VERSION ""

NS_ :

BS_:

BU_: ACC GW LAS BDC mADC FC APA HPP

BO_ 381 GW_17D: 64 GW
 SG_ PCU_RollingCounter_17D : 491|4@0+ (1,0) [0|15] ""  ACC,LAS,mADC
 SG_ PCU_CRCCheck_17D : 503|16@0+ (1,0) [0|65535] ""  ACC,LAS,mADC
 SG_ PCU_RollingCounter_1C4 : 435|4@0+ (1,0) [0|15] ""  APA
 SG_ PCU_RearMotSts : 408|1@0+ (1,0) [0|1] "" Vector__XXX
 SG_ PCU_PwrIndcdRealTqRearWhl : 391|15@0+ (1,-5400) [-5400|12000] "Nm"  ACC,LAS,APA,FC,mADC
 SG_ PCU_PwrIndcdDrvrReqTqWhlRear : 392|15@0+ (1,-5400) [-5400|12000] "Nm"  ACC,LAS,FC
 SG_ PCU_ESPTqReqAvlRear : 409|1@0+ (1,0) [0|1] "" Vector__XXX
 SG_ PCU_CRCCheck_1C4 : 447|8@0+ (1,0) [0|255] ""  APA
 SG_ PCU_RollingCounter_1BE : 371|4@0+ (1,0) [0|15] "" Vector__XXX
 SG_ PCU_MbRegenWhlRear : 343|16@0+ (1,-32768) [-32768|32767] "Nm" Vector__XXX
 SG_ PCU_MbRegenMaxWhlTotal : 327|16@0+ (1,-32768) [-32768|32767] "Nm" Vector__XXX
 SG_ PCU_MbRegenMaxRearWhl : 359|16@0+ (1,-32768) [-32768|32767] "Nm" Vector__XXX
 SG_ PCU_CRCCheck_1BE : 383|8@0+ (1,0) [0|255] "" Vector__XXX
 SG_ PCU_PwrTrainSts : 311|2@0+ (1,0) [0|3] ""  ACC,LAS,APA,FC
 SG_ PCU_RollingCounter_1A6 : 307|4@0+ (1,0) [0|15] ""  APA
 SG_ PCU_MbRegenWhlFront : 263|16@0+ (1,-32768) [-32768|32767] "Nm" Vector__XXX
 SG_ PCU_MbRegenMaxWhlQlfr : 293|2@0+ (1,0) [0|2] "" Vector__XXX
 SG_ PCU_MbRegenMaxFrontWhlVld : 294|1@0+ (1,0) [0|1] "" Vector__XXX
 SG_ PCU_MbRegenMaxFrontWhl : 279|16@0+ (1,-32768) [-32768|32767] "Nm" Vector__XXX
 SG_ PCU_CRCCheck_1A6 : 319|8@0+ (1,0) [0|255] ""  APA
 SG_ PCU_APATorqRequestAvailable : 289|1@0+ (1,0) [0|1] ""  APA,mADC
 SG_ PCU_APARequestEnable : 309|2@0+ (1,0) [0|3] ""  APA,mADC
 SG_ PCU_AccPedlVld : 288|1@0+ (1,0) [0|1] ""  ACC,LAS,APA,mADC,FC
 SG_ PCU_AccPedl : 303|8@0+ (0.392,0) [0|99.96] "pct"  ACC,LAS,APA,mADC,FC
 SG_ PCU_StartStopActiveVld : 234|1@0+ (1,0) [0|1] ""  mADC
 SG_ PCU_StartStopActive : 235|1@0+ (1,0) [0|1] ""  mADC
 SG_ PCU_RollingCounter_211 : 243|4@0+ (1,0) [0|15] "" Vector__XXX
 SG_ PCU_RearMotStsVld : 236|1@0+ (1,0) [0|1] "" Vector__XXX
 SG_ PCU_QECACC : 230|2@0+ (1,0) [0|3] ""  ACC,LAS,mADC,FC
 SG_ PCU_PwrIndcdRealTqWhlFailr : 225|1@0+ (1,0) [0|1] ""  ACC,LAS,APA,mADC,FC
 SG_ PCU_PwrIndcdRealTqFrontWhl : 199|15@0+ (1,-5400) [-5400|12000] "Nm"  ACC,LAS,APA,mADC,FC
 SG_ PCU_PwrIndcdDrvrReqTqWhlFront : 200|15@0+ (1,-5400) [-5400|12000] "Nm"  ACC,LAS,APA,mADC,FC
 SG_ PCU_FrontMotStsVld : 239|1@0+ (1,0) [0|1] "" Vector__XXX
 SG_ PCU_FrontMotSts : 217|1@0+ (1,0) [0|1] "" Vector__XXX
 SG_ PCU_ESPTqReqAvlFront : 216|1@0+ (1,0) [0|1] "" Vector__XXX
 SG_ PCU_EngStsVld : 238|1@0+ (1,0) [0|1] ""  mADC
 SG_ PCU_EngSts : 227|1@0+ (1,0) [0|1] ""  mADC
 SG_ PCU_EngClutchStsVld : 237|1@0+ (1,0) [0|1] "" Vector__XXX
 SG_ PCU_EngClutchSts : 226|1@0+ (1,0) [0|1] "" Vector__XXX
 SG_ PCU_ECGPOvrd : 231|1@0+ (1,0) [0|1] ""  ACC,LAS,FC,mADC
 SG_ PCU_CRCCheck_211 : 255|8@0+ (1,0) [0|255] "" Vector__XXX
 SG_ PCU_AccReqPossible : 228|1@0+ (1,0) [0|1] ""  ACC,LAS,FC,mADC
 SG_ RGearbox_ActualDrivingGear : 110|2@0+ (1,0) [0|3] "" Vector__XXX
 SG_ PCU_TrsmTarIdleSpdReq : 108|9@0+ (10,0) [0|5110] "rpm" Vector__XXX
 SG_ PCU_TarGearReqValid : 111|1@0+ (1,0) [0|1] ""  ACC,LAS,FC
 SG_ PCU_TarGearReq : 99|4@0+ (1,0) [0|15] ""  ACC,LAS,FC
 SG_ PCU_SpdCtrlModSelect : 88|2@0+ (1,0) [0|3] "" Vector__XXX
 SG_ PCU_RollingCounter_1C6 : 115|4@0+ (1,0) [0|15] "" Vector__XXX
 SG_ PCU_RealAccPedlVld : 79|1@0+ (1,0) [0|1] ""  ACC,LAS,APA,mADC,FC
 SG_ PCU_RealAccPedl : 71|8@0+ (0.392,0) [0|99.96] "%"  LAS,APA,mADC,FC,ACC
 SG_ PCU_MILReq : 100|1@0+ (1,0) [0|1] "" Vector__XXX
 SG_ PCU_K3CluSts : 78|1@0+ (1,0) [0|1] "" Vector__XXX
 SG_ PCU_FlywhTqTransLoadActInvld : 77|1@0+ (1,0) [0|1] "" Vector__XXX
 SG_ PCU_FlywhTqTransLoadAct : 76|8@0+ (1,0) [0|254] "Nm" Vector__XXX
 SG_ PCU_EngTarIdleSpdReq : 84|9@0+ (10,0) [0|5110] "rpm" Vector__XXX
 SG_ PCU_EngStrtMod : 91|3@0+ (1,0) [0|7] "" Vector__XXX
 SG_ PCU_CRCCheck_1C6 : 127|8@0+ (1,0) [0|255] "" Vector__XXX
 SG_ PCU_ClrDiagcInfo : 102|2@0+ (1,0) [0|3] "" Vector__XXX
 SG_ PCU_StrtTrqCtl : 182|1@0+ (1,0) [0|1] "" Vector__XXX
 SG_ PCU_StrtInhb : 183|1@0+ (1,0) [0|1] "" Vector__XXX
 SG_ PCU_RollingCounter_1E1 : 179|4@0+ (1,0) [0|15] "" Vector__XXX
 SG_ PCU_PtStsChrgCrp : 135|2@0+ (1,0) [0|3] "" Vector__XXX
 SG_ PCU_FuCutOffReq : 153|1@0+ (1,0) [0|1] "" Vector__XXX
 SG_ PCU_EngIgnAgIntvEnbl : 169|1@0+ (1,0) [0|1] "" Vector__XXX
 SG_ PCU_EngTqFlywhSlowReq : 151|13@0+ (0.1,-350) [-350|400] "Nm" Vector__XXX
 SG_ PCU_EngTqFlywhReqVld : 133|1@0+ (1,0) [0|1] "" Vector__XXX
 SG_ PCU_EngTqFlywhFastReq : 132|13@0+ (0.1,-350) [-350|400] "Nm" Vector__XXX
 SG_ PCU_EngTqFlywhAllwdMaxVld : 152|1@0+ (1,0) [0|1] "" Vector__XXX
 SG_ PCU_EngTqFlywhAllwdMax : 167|13@0+ (0.1,-350) [-350|400] "Nm" Vector__XXX
 SG_ PCU_EngStrtOrd : 180|1@0+ (1,0) [0|1] "" Vector__XXX
 SG_ PCU_EngStpOrd : 181|1@0+ (1,0) [0|1] "" Vector__XXX
 SG_ PCU_EMSSurgeDamperEna : 168|1@0+ (1,0) [0|1] "" Vector__XXX
 SG_ PCU_CRCCheck_1E1 : 191|8@0+ (1,0) [0|255] "" Vector__XXX
 SG_ PCU_BrkPedlSts2 : 170|1@0+ (1,0) [0|1] ""  mADC
 SG_ PCU_BrkPedlSts1 : 154|1@0+ (1,0) [0|1] ""  mADC
 SG_ PCU_VehSts : 8|3@0+ (1,0) [0|7] "" Vector__XXX
 SG_ PCU_VehSpdVld : 44|1@0+ (1,0) [0|1] "" Vector__XXX
 SG_ PCU_VehSpd : 43|8@0+ (1,0) [0|254] "km/h" Vector__XXX
 SG_ PCU_SOCDisp : 15|7@0+ (1,0) [0|100] "%" Vector__XXX
 SG_ PCU_CRCID191 : 63|8@0+ (1,0) [0|255] "" Vector__XXX
 SG_ PCU_ChrgUnlckILimReq : 29|1@0+ (1,0) [0|1] "" Vector__XXX
 SG_ PCU_ChrgSuspReq : 47|1@0+ (1,0) [0|1] "" Vector__XXX
 SG_ PCU_ChrgIReqLimFac : 26|2@0+ (1,0) [0|3] "" Vector__XXX
 SG_ PCU_ChrgAllwd : 31|1@0+ (1,0) [0|1] "" Vector__XXX
 SG_ PCU_CHMAsignalSts : 27|1@0+ (1,0) [0|1] "" Vector__XXX
 SG_ PCU_BMSOperModReq : 21|3@0+ (1,0) [0|6] "" Vector__XXX
 SG_ PCU_BattIntrHeatAllwd : 30|1@0+ (1,0) [0|1] "" Vector__XXX
 SG_ PCU_ActHVPwrCnsExt : 7|8@0+ (0.1,0) [0|25.5] "kw" Vector__XXX
 SG_ PCU_191CycCntr : 51|4@0+ (1,0) [0|15] "" Vector__XXX

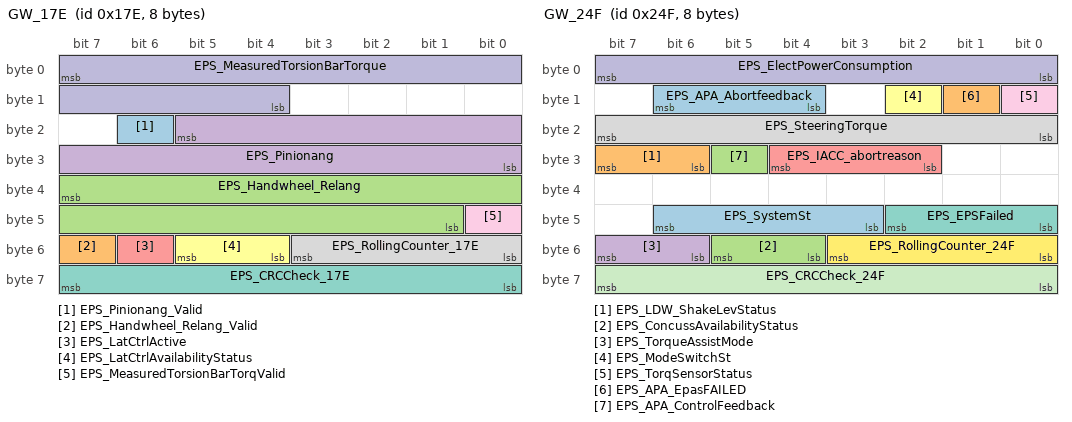
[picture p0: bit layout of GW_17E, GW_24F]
BO_ 382 GW_17E: 8 GW
 SG_ EPS_Pinionang_Valid : 22|1@0+ (1,0) [0|1] ""  mADC,FC
 SG_ EPS_Handwheel_Relang_Valid : 55|1@0+ (1,0) [0|1] ""  LAS,mADC
 SG_ EPS_Handwheel_Relang : 39|15@0+ (0.1,-1080) [-1080|1080] "degree"  LAS,FC,mADC
 SG_ EPS_Pinionang : 21|14@0+ (0.1,-720) [-720|720] "degree"  LAS,FC,mADC
 SG_ EPS_LatCtrlActive : 54|1@0+ (1,0) [0|1] ""  LAS,FC,mADC
 SG_ EPS_LatCtrlAvailabilityStatus : 53|2@0+ (1,0) [0|3] ""  LAS,FC,mADC
 SG_ EPS_CRCCheck_17E : 63|8@0+ (1,0) [0|255] ""  ACC,LAS,FC,mADC
 SG_ EPS_RollingCounter_17E : 51|4@0+ (1,0) [0|15] ""  ACC,LAS,FC,mADC
 SG_ EPS_MeasuredTorsionBarTorqValid : 40|1@0+ (1,0) [0|1] ""  ACC,LAS,FC,mADC
 SG_ EPS_MeasuredTorsionBarTorque : 7|12@0+ (0.01,-20.48) [-20.48|20.46] "Nm"  ACC,LAS,FC,mADC

BO_ 442 ACC_1BA: 32 ACC
 SG_ ACC_CRCCheck_1BA_0 : 63|8@0+ (1,0) [0|255] ""  ACC,LAS,GW,FC,mADC
 SG_ ACC_RollingCounter_1BA_0 : 51|4@0+ (1,0) [0|15] ""  ACC,LAS,GW,FC,mADC
 SG_ ACC_LatAngReqActive : 35|1@0+ (1,0) [0|1] ""  ACC,LAS,GW,FC,mADC
 SG_ ACC_LatAngReq : 17|14@0+ (0.1,-720) [-720|720] "degree"  ACC,LAS,GW,FC,mADC
 SG_ ACC_MotorTorqueMinLimitRequest : 12|11@0+ (0.02,-20.48) [-20.48|20.44] "Nm"  ACC,LAS,GW,FC,mADC
 SG_ ACC_MotorTorqueMaxLimitRequest : 7|11@0+ (0.02,-20.48) [-20.48|20.44] "Nm"  ACC,LAS,GW,FC,mADC

BO_ 523 GW_20B: 64 GW
 SG_ IBCU_BrkPedlStsGbVld : 303|2@0+ (1,0) [0|2] ""  ACC,LAS,APA,FC,mADC
 SG_ IBCU_BrkPedoplStsGb : 295|8@0+ (1,0) [0|255] "%"  ACC,LAS,APA,FC,mADC
 SG_ ESP_Vehicle_Speed_Reference : 103|13@0+ (0.05625,0) [0|360] "km/h"  ACC,LAS,FC,APA
 SG_ IBCU_precheckStatus : 309|2@0+ (1,0) [0|3] ""  ACC,LAS,APA
 SG_ ESP_PrefillforAPA_Available : 280|1@0+ (1,0) [0|1] ""  ACC,LAS,APA,mADC
 SG_ ESP_PrefillforAPA_active : 281|1@0+ (1,0) [0|1] ""  ACC,LAS,APA,mADC
 SG_ IBCU_BrakeDiscHighTempWarning : 283|2@0+ (1,0) [0|3] ""  ACC,LAS,FC,APA
 SG_ ESP_RollingCounter_20B : 491|4@0+ (1,0) [0|15] ""  ACC,LAS,FC,HPP,mADC
 SG_ ESP_CRCCheck_20B : 503|16@0+ (1,0) [0|65535] ""  ACC,LAS,FC,HPP,mADC
 SG_ Wheel_Speed_RR_Valid_Data : 71|1@0+ (1,0) [0|1] ""  APA,ACC,LAS,FC,HPP,mADC
 SG_ Wheel_Speed_RR_Pulse : 231|8@0+ (1,0) [0|254] ""  APA,ACC,LAS,FC,HPP,mADC
 SG_ Wheel_Speed_RR_Direction : 70|2@0+ (1,0) [0|3] ""  APA,ACC,LAS,FC,HPP,mADC
 SG_ Wheel_Speed_RR_Data : 68|13@0+ (0.05625,0) [0|360] "km/h"  APA,ACC,LAS,FC,HPP,mADC
 SG_ Wheel_Speed_RL_Valid_Data : 87|1@0+ (1,0) [0|1] ""  APA,ACC,LAS,FC,HPP,mADC
 SG_ Wheel_Speed_RL_Pulse : 239|8@0+ (1,0) [0|254] ""  APA,ACC,LAS,FC,HPP,mADC
 SG_ Wheel_Speed_RL_Direction : 86|2@0+ (1,0) [0|3] ""  APA,ACC,LAS,FC,HPP,mADC
 SG_ Wheel_Speed_RL_Data : 84|13@0+ (0.05625,0) [0|360] "km/h"  APA,ACC,LAS,FC,HPP,mADC
 SG_ Wheel_Speed_FR_Valid_Data : 7|1@0+ (1,0) [0|1] ""  APA,ACC,LAS,FC,HPP,mADC
 SG_ Wheel_Speed_FR_Pulse : 223|8@0+ (1,0) [0|254] ""  APA,ACC,LAS,FC,HPP,mADC
 SG_ Wheel_Speed_FR_Direction : 6|2@0+ (1,0) [0|3] ""  APA,ACC,LAS,FC,HPP,mADC
 SG_ Wheel_Speed_FR_Data : 4|13@0+ (0.05625,0) [0|360] "km/h"  APA,ACC,LAS,FC,HPP,mADC
 SG_ Wheel_Speed_FL_Valid_Data : 23|1@0+ (1,0) [0|1] ""  APA,ACC,LAS,FC,HPP,mADC
 SG_ Wheel_Speed_FL_Pulse : 215|8@0+ (1,0) [0|254] ""  APA,ACC,LAS,FC,HPP,mADC
 SG_ Wheel_Speed_FL_Direction : 22|2@0+ (1,0) [0|3] ""  APA,ACC,LAS,FC,HPP,mADC
 SG_ Wheel_Speed_FL_Data : 20|13@0+ (0.05625,0) [0|360] "km/h"  APA,ACC,LAS,FC,HPP,mADC
 SG_ ESP_VehicleStandstill : 267|1@0+ (1,0) [0|1] ""  APA,ACC,LAS,FC,mADC
 SG_ ESP_VDCActive : 266|1@0+ (1,0) [0|1] ""  ACC,LAS,FC,mADC
 SG_ ESP_UrgencyBrakeAlarm : 118|1@0+ (1,0) [0|1] "" Vector__XXX
 SG_ ESP_TODTorqueMaxLimit : 47|12@0+ (1,0) [0|4094] "NM" Vector__XXX
 SG_ ESP_TCSActive : 265|1@0+ (1,0) [0|1] ""  ACC,LAS,FC,mADC
 SG_ ESP_RollingCounter_277 : 307|4@0+ (1,0) [0|15] ""  APA,ACC,LAS,FC
 SG_ ESP_RollingCounter_258 : 243|4@0+ (1,0) [0|15] ""  APA,ACC,LAS,FC,HPP
 SG_ ESP_RollingCounter_208 : 115|4@0+ (1,0) [0|15] ""  APA,ACC,LAS,FC,HPP
 SG_ ESP_RollingCounter_206 : 51|4@0+ (1,0) [0|15] ""  APA,ACC,LAS,FC,HPP
 SG_ ESP_QDCACC : 279|2@0+ (1,0) [0|3] ""  ACC,LAS,FC,mADC
 SG_ ESP_PrefillAvailable : 259|1@0+ (1,0) [0|1] ""  ACC,LAS,FC,APA,mADC,HPP
 SG_ ESP_PrefillActive : 260|1@0+ (1,0) [0|1] ""  ACC,LAS,FC,APA,mADC,HPP
 SG_ ESP_OnlyABSActive : 264|1@0+ (1,0) [0|1] ""  ACC,LAS,FC,mADC
 SG_ ESP_MasCylBrakePressureValid : 199|1@0+ (1,0) [0|1] ""  APA,ACC,LAS,FC,mADC
 SG_ ESP_MasCylBrakePressure : 195|12@0+ (0.1,0) [0|250] "Bar"  APA,ACC,LAS,FC,mADC
 SG_ ESP_IncreasePressureReqOK : 275|1@0+ (1,0) [0|1] "NA"  APA,mADC
 SG_ ESP_HHC_Available : 245|1@0+ (1,0) [0|1] ""  mADC
 SG_ ESP_HHC_Active : 244|1@0+ (1,0) [0|1] ""  mADC
 SG_ ESP_HDC_STATUS : 274|2@0+ (1,0) [0|3] ""  ACC,LAS,mADC
 SG_ ESP_HBBActiveStatus : 272|1@0+ (1,0) [0|1] ""  mADC
 SG_ ESP_ECDAvailable : 116|1@0+ (1,0) [0|1] "" Vector__XXX
 SG_ ESP_ECDActive : 117|1@0+ (1,0) [0|1] "" Vector__XXX
 SG_ ESP_CRCCheck_277 : 319|8@0+ (1,0) [0|255] ""  APA,ACC,LAS,FC
 SG_ ESP_CRCCheck_258 : 255|8@0+ (1,0) [0|255] ""  ACC,LAS,FC,APA,HPP
 SG_ ESP_CRCCheck_208 : 127|8@0+ (1,0) [0|255] ""  APA,ACC,LAS,FC,HPP
 SG_ ESP_CRCCheck_206 : 63|8@0+ (1,0) [0|255] ""  APA,ACC,LAS,FC,HPP
 SG_ ESP_CDP_ParkingAvailForACC : 284|1@0+ (1,0) [0|1] "" Vector__XXX
 SG_ ESP_CDP_ParkingActiveForACC : 285|1@0+ (1,0) [0|1] "" Vector__XXX
 SG_ ESP_CDD_Available_APA : 276|1@0+ (1,0) [0|1] "NA"  APA,mADC
 SG_ ESP_CDD_Available : 268|1@0+ (1,0) [0|1] ""  ACC,LAS,FC,mADC
 SG_ ESP_CDD_Active_APA : 277|1@0+ (1,0) [0|1] "NA"  APA,mADC
 SG_ ESP_CDD_Active : 269|1@0+ (1,0) [0|1] ""  ACC,LAS,FC,mADC
 SG_ ESP_BrakeOverHeatBrakeDiscTemp : 270|1@0+ (1,0) [0|1] ""  ACC,LAS,FC,mADC
 SG_ ESP_BrakeLightOnRequest : 197|2@0+ (1,0) [0|3] "" Vector__XXX
 SG_ ESP_BrakeForce : 263|1@0+ (1,0) [0|1] ""  ACC,LAS,FC,APA,mADC
 SG_ ESP_AWBavailable : 271|1@0+ (1,0) [0|1] ""  ACC,LAS,FC,mADC
 SG_ ESP_AWBactive : 256|1@0+ (1,0) [0|1] ""  ACC,LAS,FC,mADC
 SG_ ESP_AutoHoldStandby : 198|1@0+ (1,0) [0|1] "" Vector__XXX
 SG_ ESP_AutoHoldAvailable : 246|1@0+ (1,0) [0|1] ""  LAS,ACC
 SG_ ESP_AutoHoldActive : 247|1@0+ (1,0) [0|1] ""  LAS,ACC,mADC
 SG_ ESP_AEBdecActive : 257|1@0+ (1,0) [0|1] ""  ACC,LAS,FC,mADC
 SG_ ESP_AEBAvailable : 258|1@0+ (1,0) [0|1] ""  ACC,LAS,FC,mADC
 SG_ ESP_ABAavailable : 261|1@0+ (1,0) [0|1] ""  ACC,LAS,FC,mADC
 SG_ ESP_ABAactive : 262|1@0+ (1,0) [0|1] ""  ACC,LAS,FC,mADC
 SG_ ABS_TODFastOpenRequest : 33|2@0+ (1,0) [0|3] "" Vector__XXX

BO_ 591 GW_24F: 8 GW
 SG_ EPS_SystemSt : 46|4@0+ (1,0) [0|15] ""  mADC
 SG_ EPS_LDW_ShakeLevStatus : 31|2@0+ (1,0) [0|3] ""  LAS,FC,mADC
 SG_ EPS_ConcussAvailabilityStatus : 53|2@0+ (1,0) [0|3] ""  ACC,LAS,FC,APA,mADC,HPP
 SG_ EPS_TorqueAssistMode : 55|2@0+ (1,0) [0|3] ""  ACC,LAS,FC,APA,mADC
 SG_ EPS_IACC_abortreason : 28|3@0+ (1,0) [0|7] ""  LAS,FC,APA,mADC,HPP
 SG_ EPS_ModeSwitchSt : 10|1@0+ (1,0) [0|1] ""  mADC
 SG_ EPS_EPSFailed : 42|3@0+ (1,0) [0|7] ""  mADC
 SG_ EPS_SteeringTorque : 23|8@0+ (0.1794,-22.78) [-22.78|22.78] "Nm"  APA,mADC
 SG_ EPS_TorqSensorStatus : 8|1@0+ (1,0) [0|1] ""  APA,mADC
 SG_ EPS_ElectPowerConsumption : 7|8@0+ (0.5,0) [0|127] "A"  APA,mADC
 SG_ EPS_CRCCheck_24F : 63|8@0+ (1,0) [0|255] ""  ACC,LAS,FC,APA,mADC,HPP
 SG_ EPS_RollingCounter_24F : 51|4@0+ (1,0) [0|15] ""  ACC,LAS,FC,APA,mADC
 SG_ EPS_APA_Abortfeedback : 14|3@0+ (1,0) [0|7] ""  APA,mADC
 SG_ EPS_APA_EpasFAILED : 9|1@0+ (1,0) [0|1] ""  APA,mADC
 SG_ EPS_APA_ControlFeedback : 29|1@0+ (1,0) [0|1] ""  APA,mADC

BO_ 651 GW_28B: 8 GW
 SG_ BCM_RefuelReq : 55|1@0+ (1,0) [0|1] "" Vector__XXX
 SG_ BCM_TrunkReleaseTrigger : 31|4@0+ (1,0) [0|15] "" Vector__XXX
 SG_ BCM_LockTrigger : 12|5@0+ (1,0) [0|31] ""  mADC
 SG_ BCM_UnlockTrigger : 44|5@0+ (1,0) [0|31] ""  mADC
 SG_ BCM_CRCCheck_28B : 63|8@0+ (1,0) [0|255] ""  FC,LAS,ACC,mADC
 SG_ BCM_RollingCounter_28B : 51|4@0+ (1,0) [0|15] ""  FC,LAS,ACC,mADC
 SG_ BCM_TurnIndicatorLeft : 22|2@0+ (1,0) [0|3] ""  ACC,LAS,FC,APA,mADC,HPP
 SG_ BCM_TurnIndicatorRight : 20|2@0+ (1,0) [0|3] ""  ACC,LAS,FC,APA,mADC,HPP
 SG_ PEPS_ShiftForbidRq : 54|1@0+ (1,0) [0|1] "" Vector__XXX
 SG_ BCM_KeyAlarmStatus : 53|2@0+ (1,0) [0|3] ""  APA,mADC
 SG_ PEPS_RemoteStartReq : 39|2@0+ (1,0) [0|3] ""  APA
 SG_ BCM_emergencylightstatus : 37|2@0+ (1,0) [0|3] ""  LAS,FC,APA,mADC,ACC
 SG_ BCM_PowerStatusFeedback : 35|2@0+ (1,0) [0|3] ""  APA,ACC,LAS,FC,mADC
 SG_ BCM_RearDefrosterstatus : 33|2@0+ (1,0) [0|3] ""  mADC
 SG_ BCM_DriverDoorStatus : 23|1@0+ (1,0) [0|1] ""  APA,ACC,FC,LAS,mADC
 SG_ BCM_HoodStatus : 18|1@0+ (1,0) [0|1] ""  ACC,mADC
 SG_ PEPS_StartControlsignal : 17|2@0+ (1,0) [0|3] "" Vector__XXX
 SG_ BCM_LowBeamStatus : 7|2@0+ (1,0) [0|3] ""  LAS,FC,APA,mADC
 SG_ BCM_HighBeamStatus : 5|2@0+ (1,0) [0|3] ""  LAS,FC,APA,mADC
 SG_ BCM_TurnLightSwitchSts : 3|2@0+ (1,0) [0|3] ""  APA,LAS,FC,ACC,mADC
 SG_ BCM_MirrorAdjustSts : 14|2@0+ (1,0) [0|3] ""  LAS,ACC,mADC

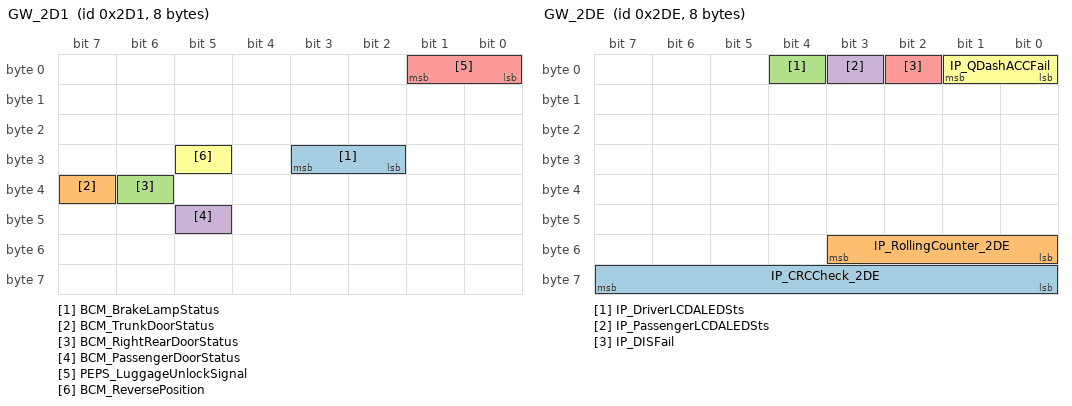
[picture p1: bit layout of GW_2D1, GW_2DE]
BO_ 721 GW_2D1: 8 GW
 SG_ BCM_BrakeLampStatus : 27|2@0+ (1,0) [0|3] ""  mADC
 SG_ BCM_TrunkDoorStatus : 39|1@0+ (1,0) [0|1] ""  ACC,LAS,FC,APA,mADC
 SG_ BCM_RightRearDoorStatus : 38|1@0+ (1,0) [0|1] ""  ACC,LAS,FC,APA,mADC
 SG_ BCM_PassengerDoorStatus : 45|1@0+ (1,0) [0|1] ""  ACC,LAS,FC,APA,mADC
 SG_ PEPS_LuggageUnlockSignal : 1|2@0+ (1,0) [0|3] "" Vector__XXX
 SG_ BCM_ReversePosition : 29|1@0+ (1,0) [0|1] ""  mADC

BO_ 734 GW_2DE: 8 GW
 SG_ IP_CRCCheck_2DE : 63|8@0+ (1,0) [0|255] ""  ACC,APA,FC,LAS,mADC
 SG_ IP_RollingCounter_2DE : 51|4@0+ (1,0) [0|15] ""  ACC,APA,FC,LAS,mADC
 SG_ IP_DriverLCDALEDSts : 4|1@0+ (1,0) [0|1] ""  APA,mADC
 SG_ IP_PassengerLCDALEDSts : 3|1@0+ (1,0) [0|1] ""  APA,mADC
 SG_ IP_DISFail : 2|1@0+ (1,0) [0|1] ""  ACC,LAS,FC,mADC
 SG_ IP_QDashACCFail : 1|2@0+ (1,0) [0|3] ""  ACC,LAS,FC,mADC

BO_ 742 GW_2E6: 8 GW
 SG_ EMS_WarmUpCycle : 9|1@0+ (1,0) [0|1] "" Vector__XXX
 SG_ EMS_SecIgnitionCyclesCounter : 53|1@0+ (1,0) [0|1] "" Vector__XXX
 SG_ EMS_RollingCounter_2E6 : 51|4@0+ (1,0) [0|15] "" Vector__XXX
 SG_ EMS_LoBattU : 31|8@0+ (0.1,0) [0|25.4] "V" Vector__XXX
 SG_ EMS_LoBattErr : 14|1@0+ (1,0) [0|1] "" Vector__XXX
 SG_ EMS_IgnitionCyclesCounterValid : 52|1@0+ (1,0) [0|1] "" Vector__XXX
 SG_ EMS_GeneralDenoStatusValid : 11|1@0+ (1,0) [0|1] "" Vector__XXX
 SG_ EMS_GeneralDenominatorStatus : 12|1@0+ (1,0) [0|1] "" Vector__XXX
 SG_ EMS_FirstIgnitionCycleCounter : 10|1@0+ (1,0) [0|1] "" Vector__XXX
 SG_ EMS_EngTCoolt : 23|8@0+ (0.75,-48) [-48|142.5] "°C" Vector__XXX
 SG_ EMS_EngineIntakeAirTemp : 7|8@0+ (0.75,-40) [-40|150.5] "degreeC" Vector__XXX
 SG_ EMS_DrivingCycle : 8|1@0+ (1,0) [0|1] "" Vector__XXX
 SG_ EMS_CRCCheck_2E6 : 63|8@0+ (1,0) [0|255] "" Vector__XXX
 SG_ EMS_CooltTErr : 15|1@0+ (1,0) [0|1] "" Vector__XXX
 SG_ EMS_Coolreq : 39|7@0+ (1,0) [0|100] "%" Vector__XXX
 SG_ EMS_CatalystWarmUp : 13|1@0+ (1,0) [0|1] "" Vector__XXX
 SG_ EMS_AltitudeFactorValid : 32|1@0+ (1,0) [0|1] "" Vector__XXX
 SG_ EMS_AltitudeFactor : 47|8@0+ (0.01575,0) [0|4] ""  ACC,FC

BO_ 794 ACC_31A: 64 ACC
 SG_ ADC_EcasModeReq : 165|3@0+ (1,0) [0|7] ""  ACC,LAS,mADC,GW
 SG_ ACC_AEBTargetLatRelSpeed : 293|10@0+ (0.125,-64) [-64|63.875] "m/s"  ACC,LAS,GW,mADC
 SG_ ACC_LngTakeOverReqReason : 232|5@0+ (1,0) [0|31] ""  ACC,LAS,FC,GW,mADC
 SG_ ACC_ELKAlert : 25|2@0+ (1,0) [0|3] ""  ACC,LAS,GW,mADC
 SG_ ACC_CRCCheck_367 : 255|8@0+ (1,0) [0|255] ""  ACC,LAS,FC,GW
 SG_ ACC_RollingCounter_367 : 243|4@0+ (1,0) [0|15] ""  ACC,LAS,FC,GW
 SG_ ACC_LatPathHeadingAngle : 227|11@0- (0.1,0) [-90|90] "degree"  ACC,LAS,GW,mADC
 SG_ ACC_ELKEnableStatus : 222|1@0+ (1,0) [0|1] ""  ACC,LAS,GW,mADC
 SG_ ACC_ELKInterventionMode : 210|2@0+ (1,0) [0|3] ""  ACC,LAS,GW,mADC
 SG_ ACC_ELKMode : 213|3@0+ (1,0) [0|7] ""  ACC,LAS,GW,mADC
 SG_ ACC_CRCCheck_30D : 191|8@0+ (1,0) [0|255] ""  ACC,LAS,FC,GW
 SG_ ACC_RollingCounter_30D : 179|4@0+ (1,0) [0|15] ""  ACC,LAS,FC,GW
 SG_ ACC_RRLaneDetection : 174|2@0+ (1,0) [0|3] ""  ACC,LAS,GW,mADC
 SG_ ACC_LLLaneDetection : 167|2@0+ (1,0) [0|3] ""  ACC,LAS,GW,mADC
 SG_ ACC_HighBeamControl : 182|2@0+ (1,0) [0|3] ""  ACC,LAS,GW
 SG_ ACC_TargetBasedLateralControl : 150|2@0+ (1,0) [0|3] ""  ACC,LAS,FC,GW,mADC
 SG_ ACC_IACCHWATextInfoForDriver : 128|6@0+ (1,0) [0|63] ""  ACC,LAS,FC,GW,mADC
 SG_ ACC_EmergencyLightingRequest : 148|2@0+ (1,0) [0|3] ""  ACC,LAS,FC,GW,mADC
 SG_ ACC_DriverHandsOffStatus : 137|2@0+ (1,0) [0|3] ""  ACC,LAS,FC,GW,mADC
 SG_ ACC_IACCHWAMode : 135|3@0+ (1,0) [0|7] ""  ACC,LAS,FC,GW,APA,mADC
 SG_ ACC_CRCCheck_30A : 127|8@0+ (1,0) [0|255] ""  ACC,LAS,FC,GW
 SG_ ACC_RollingCounter_30A : 115|4@0+ (1,0) [0|15] ""  ACC,LAS,FC,GW
 SG_ ACC_LaneChangeStatus : 117|2@0+ (1,0) [0|3] ""  ACC,LAS,GW,mADC
 SG_ ACC_RoadCurvatureFar : 109|7@0+ (0.0005,-0.03) [-0.03|0.03] "1/m"  ACC,LAS,GW
 SG_ ACC_RoadCurvatureNear : 100|7@0+ (0.0005,-0.03) [-0.03|0.03] "1/m"  ACC,LAS,GW
 SG_ ACC_RoadCurvature : 91|7@0+ (0.0005,-0.03) [-0.03|0.03] "1/m"  ACC,LAS,GW
 SG_ ACC_IACCHWAEnable : 78|1@0+ (1,0) [0|1] ""  ACC,LAS,GW,mADC
 SG_ ACC_RLaneMarkerType : 71|4@0+ (1,0) [0|15] ""  ACC,LAS,FC,GW,mADC
 SG_ ACC_LLaneMarkerType : 95|4@0+ (1,0) [0|15] ""  ACC,LAS,FC,GW,mADC
 SG_ ACC_HostLaneRightStatus : 87|4@0+ (1,0) [0|15] ""  ACC,LAS,FC,GW,mADC
 SG_ ACC_HostLaneLeftStatus : 83|4@0+ (1,0) [0|15] ""  ACC,LAS,FC,GW,mADC
 SG_ ACC_LASWarningModeSelectionSts : 74|3@0+ (1,0) [0|7] ""  ACC,GW,LAS,mADC
 SG_ ACC_LASModeSelectionStatus : 66|3@0+ (1,0) [0|7] ""  ACC,LAS,GW,mADC
 SG_ ACC_CRCCheck_36D : 63|8@0+ (1,0) [0|255] ""  ACC,LAS,FC,GW
 SG_ ACC_RollingCounter_36D : 51|4@0+ (1,0) [0|15] ""  ACC,LAS,FC,GW
 SG_ ACC_FRadarFailureStatus : 53|2@0+ (1,0) [0|3] ""  LAS,ACC,GW,mADC
 SG_ ACC_AEBTargetLatRange : 21|10@0+ (0.1,-50) [-50|50] "m"  ACC,LAS,GW,mADC
 SG_ ACC_AEBTargetRelSpeed : 14|9@0+ (1,-250) [-250|250] "km/h"  ACC,LAS,GW,mADC
 SG_ ACC_AEBTargetLngRange : 7|9@0+ (0.5,-70) [-70|180] "m"  ACC,LAS,GW,mADC
 SG_ ACC_Voiceinfo : 47|5@0+ (1,0) [0|31] ""  ACC,LAS,FC,GW,mADC
 SG_ ACC_AEBTargetmode : 33|2@0+ (1,0) [0|3] ""  ACC,LAS,GW,mADC
 SG_ ACC_AEBTextInfo : 37|4@0+ (1,0) [0|15] ""  ACC,LAS,GW,mADC
 SG_ ACC_AEBStatus : 39|2@0+ (1,0) [0|3] ""  ACC,LAS,GW,mADC

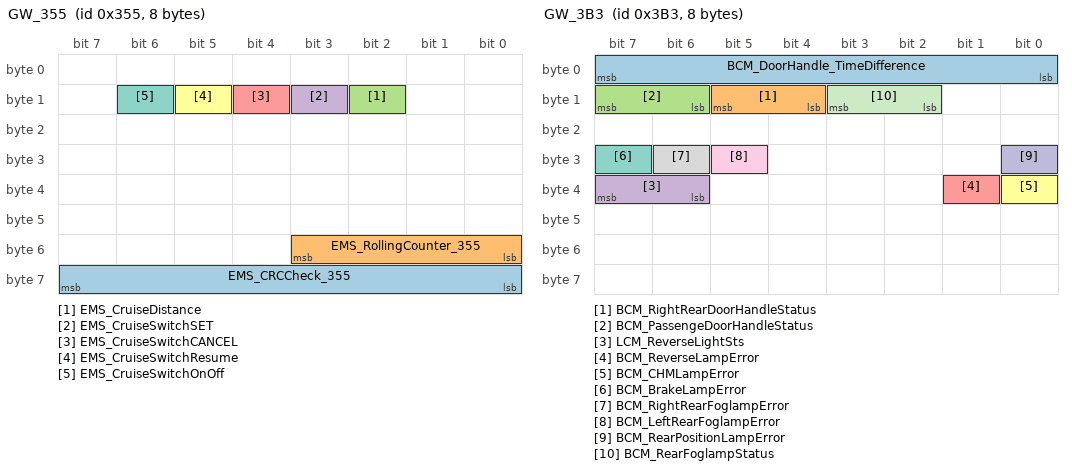
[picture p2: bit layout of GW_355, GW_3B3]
BO_ 853 GW_355: 8 GW
 SG_ EMS_CRCCheck_355 : 63|8@0+ (1,0) [0|255] ""  ACC,FC,LAS
 SG_ EMS_RollingCounter_355 : 51|4@0+ (1,0) [0|15] ""  ACC,FC,LAS
 SG_ EMS_CruiseDistance : 10|1@0+ (1,0) [0|1] ""  ACC,LAS,FC
 SG_ EMS_CruiseSwitchSET : 11|1@0+ (1,0) [0|1] ""  ACC,LAS,FC
 SG_ EMS_CruiseSwitchCANCEL : 12|1@0+ (1,0) [0|1] ""  ACC,LAS,FC
 SG_ EMS_CruiseSwitchResume : 13|1@0+ (1,0) [0|1] ""  ACC,LAS,FC
 SG_ EMS_CruiseSwitchOnOff : 14|1@0+ (1,0) [0|1] ""  ACC,LAS,FC

BO_ 943 GW_3AF: 64 GW
 SG_ HU_CRCCheck_3AF : 503|16@0+ (1,0) [0|65535] ""  ACC,LAS
 SG_ HU_RollingCounter_3AF : 491|4@0+ (1,0) [0|15] ""  ACC,LAS
 SG_ HU_Novice_Enable : 245|2@0+ (1,0) [0|3] ""  APA
 SG_ HU_ADAS_Posn_Offset : 353|13@0+ (1,0) [0|8191] "m"  ACC,LAS,mADC
 SG_ HU_ADAS_Posn_Pathldx : 359|6@0+ (1,0) [0|63] ""  ACC,LAS,mADC
 SG_ HU_EHPHeartFlag : 345|1@0+ (1,0) [0|1] ""  ACC,LAS
 SG_ HU_EHRHeartFlag : 344|1@0+ (1,0) [0|1] ""  ACC,LAS
 SG_ HU_LaneType_ID6 : 349|4@0+ (1,0) [0|15] ""  ACC,LAS,mADC
 SG_ HU_LaneType_ID5 : 337|4@0+ (1,0) [0|15] ""  ACC,LAS,mADC
 SG_ HU_LaneType_ID4 : 341|4@0+ (1,0) [0|15] ""  ACC,LAS,mADC
 SG_ HU_LaneType_ID3 : 329|4@0+ (1,0) [0|15] ""  ACC,LAS,mADC
 SG_ HU_LaneType_ID2 : 333|4@0+ (1,0) [0|15] ""  ACC,LAS,mADC
 SG_ HU_LaneType_ID1 : 321|4@0+ (1,0) [0|15] ""  ACC,LAS,mADC
 SG_ HU_ServiceRoadDis : 327|6@0+ (10,0) [0|600] "m"  ACC,LAS,mADC
 SG_ HU_ServiceRoad : 183|2@0+ (1,0) [0|3] "m"  ACC,LAS,mADC
 SG_ HU_WeatherType : 181|7@0+ (1,0) [0|127] ""  ACC,LAS,mADC
 SG_ HU_BridgeDis : 163|6@0+ (10,0) [0|600] "m"  ACC,LAS,mADC
 SG_ HU_BridgeInfo : 165|2@0+ (1,0) [0|3] ""  ACC,LAS,mADC
 SG_ HU_AccidentProneDistance : 147|6@0+ (10,0) [0|600] "m"  ACC,LAS,mADC
 SG_ HU_AccidentProne : 149|2@0+ (1,0) [0|3] ""  ACC,LAS,mADC
 SG_ HU_IntervalVelocityDis : 139|6@0+ (10,0) [0|600] "m"  ACC,LAS,mADC
 SG_ HU_IntervalVelocityInfo : 141|2@0+ (1,0) [0|3] ""  ACC,LAS,mADC
 SG_ HU_SlopeGradient_100m : 135|10@0+ (0.1,-51.1) [-51.1|51.1] "m"  ACC,LAS,mADC
 SG_ HU_SlopeGradient_50m : 111|10@0+ (0.1,-51.1) [-51.1|51.1] ""  ACC,LAS,mADC
 SG_ HU_SlopeGradient_40m : 89|10@0+ (0.1,-51.1) [-51.1|51.1] "m"  ACC,LAS,mADC
 SG_ HU_SlopeGradient_30m : 83|10@0+ (0.1,-51.1) [-51.1|51.1] ""  ACC,LAS,mADC
 SG_ HU_SlopeGradient_20m : 77|10@0+ (0.1,-51.1) [-51.1|51.1] ""  ACC,LAS,mADC
 SG_ HU_SlopeGradient_10m : 71|10@0+ (0.1,-51.1) [-51.1|51.1] ""  ACC,LAS,mADC
 SG_ HU_CRCCheck_3AF_3 : 255|8@0+ (1,0) [0|255] ""  LAS,ACC,mADC
 SG_ HU_RollingCounter_3AF_3 : 243|4@0+ (1,0) [0|15] ""  LAS,ACC,mADC
 SG_ HU_RampDistance : 239|10@0+ (10,0) [0|3000] "m"  LAS,ACC,mADC
 SG_ HU_NavSpeedLimitType : 231|2@0+ (1,0) [0|3] ""  LAS,ACC,mADC
 SG_ HU_CurveDistance : 229|6@0+ (10,0) [0|600] "m"  LAS,ACC,mADC
 SG_ HU_EnterCurveInfo : 220|2@0+ (1,0) [0|3] ""  LAS,ACC,mADC
 SG_ HU_NavCurrentRoadType : 218|3@0+ (1,0) [0|7] ""  LAS,ACC,FC,mADC
 SG_ HU_EnterRampInfo : 215|2@0+ (1,0) [0|3] ""  LAS,ACC,mADC
 SG_ HU_RampInfo : 209|2@0+ (1,0) [0|3] ""  LAS,ACC,mADC
 SG_ HU_NavCountryCode : 199|8@0+ (1,0) [0|255] ""  ACC,LAS,mADC
 SG_ HU_NavStatus : 223|1@0+ (1,0) [0|1] ""  LAS,ACC,mADC
 SG_ HU_NavSpeedLimitUnits : 213|2@0+ (1,0) [0|3] ""  ACC,LAS,mADC
 SG_ HU_NavSpeedLimitStatus : 211|2@0+ (1,0) [0|3] ""  ACC,LAS,mADC
 SG_ HU_NavSpeedLimit : 207|8@0+ (1,0) [0|255] ""  LAS,ACC,mADC
 SG_ HU_CRCCheck_3BB : 319|8@0+ (1,0) [0|255] ""  ACC,FC,LAS
 SG_ HU_RollingCounter_3BB : 307|4@0+ (1,0) [0|15] ""  ACC,FC,LAS
 SG_ HU_SpeedLimitDistance : 261|6@0+ (10,0) [0|600] "m"  ACC,LAS,mADC

BO_ 947 GW_3B3: 8 GW
 SG_ BCM_DoorHandle_TimeDifference : 7|8@0+ (5,0) [0|1275] "ms" Vector__XXX
 SG_ BCM_RightRearDoorHandleStatus : 13|2@0+ (1,0) [0|3] ""  mADC
 SG_ BCM_PassengeDoorHandleStatus : 15|2@0+ (1,0) [0|3] ""  mADC
 SG_ LCM_ReverseLightSts : 39|2@0+ (1,0) [0|3] ""  mADC
 SG_ BCM_ReverseLampError : 33|1@0+ (1,0) [0|1] ""  mADC
 SG_ BCM_CHMLampError : 32|1@0+ (1,0) [0|1] ""  mADC
 SG_ BCM_BrakeLampError : 31|1@0+ (1,0) [0|1] ""  ACC,LAS,mADC
 SG_ BCM_RightRearFoglampError : 30|1@0+ (1,0) [0|1] ""  mADC
 SG_ BCM_LeftRearFoglampError : 29|1@0+ (1,0) [0|1] ""  mADC
 SG_ BCM_RearPositionLampError : 24|1@0+ (1,0) [0|1] ""  mADC
 SG_ BCM_RearFoglampStatus : 11|2@0+ (1,0) [0|3] ""  ACC,LAS,mADC

BO_ 957 GW_3BD: 64 GW
 SG_ HU_ADSRoadVoiceEnable : 23|2@0+ (1,0) [0|3] "" Vector__XXX
 SG_ HU_ADSLaneChangeVoiceEnable : 55|2@0+ (1,0) [0|3] "" Vector__XXX
 SG_ HU_ADSSafeVoiceEnable : 53|2@0+ (1,0) [0|3] "" Vector__XXX
 SG_ HU_AVMMapDisplayFeedback : 101|2@0+ (1,0) [0|3] ""  APA
 SG_ HU_APAThemeChange : 292|3@0+ (1,0) [0|7] ""  APA
 SG_ HU_RearFoglampSet : 244|2@0+ (1,0) [0|3] "" Vector__XXX
 SG_ HU_AutoHeadLiSet : 242|3@0+ (1,0) [0|7] ""  mADC
 SG_ HU_TransparentValueCarRequest : 31|7@0+ (1,0) [0|100] ""  APA
 SG_ HU_RADSSwitch : 220|2@0+ (1,0) [0|3] ""  mADC
 SG_ HU_CRCCheck_394 : 63|8@0+ (1,0) [0|255] ""  mADC
 SG_ HU_RollingCounter_394 : 51|4@0+ (1,0) [0|15] ""  mADC
 SG_ HU_CurrentMedia_Info : 207|8@0+ (1,0) [0|255] "" Vector__XXX
 SG_ HU_LaneChangeReq : 13|2@0+ (1,0) [0|3] ""  mADC
 SG_ HU_HWAEnable : 5|2@0+ (1,0) [0|3] "" Vector__XXX
 SG_ HU_Compass : 179|9@0+ (1,0) [0|360] "Degree" Vector__XXX
 SG_ HU_APARemoteDispSts : 208|1@0+ (1,0) [0|1] "" Vector__XXX
 SG_ HU_RemoteDispSts : 195|1@0+ (1,0) [0|1] "" Vector__XXX
 SG_ HU_IRLCEnable : 3|2@0+ (1,0) [0|3] "" Vector__XXX
 SG_ HU_ADSRescueConfirm : 19|2@0+ (1,0) [0|3] "" Vector__XXX
 SG_ HU_CSLAEnable : 7|2@0+ (1,0) [0|3] ""  ACC,LAS
 SG_ HU_UDLCEnable : 17|2@0+ (1,0) [0|3] ""  mADC
 SG_ HU_ESSEnable : 11|2@0+ (1,0) [0|3] ""  mADC
 SG_ HU_ELKEnable : 1|2@0+ (1,0) [0|3] ""  LAS,FC,mADC
 SG_ HU_TLAEnable : 9|2@0+ (1,0) [0|3] ""  LAS,mADC
 SG_ HU_EXT_RemoteDetectUploadStatus : 227|2@0+ (1,0) [0|3] "" Vector__XXX
 SG_ HU_PACModeSelect : 229|2@0+ (1,0) [0|3] "" Vector__XXX
 SG_ HU_APAActive : 196|1@0+ (1,0) [0|1] "" Vector__XXX
 SG_ HU_CrossParkingModeSet : 235|2@0+ (1,0) [0|3] "" Vector__XXX
 SG_ HU_ASPSwitch : 233|2@0+ (1,0) [0|3] "" Vector__XXX
 SG_ HU_ASPRemindEnable : 231|2@0+ (1,0) [0|3] "" Vector__XXX
 SG_ HU_ASPModeSelect : 238|3@0+ (1,0) [0|7] "" Vector__XXX
 SG_ HU_LAEBEnable : 194|2@0+ (1,0) [0|3] ""  APA,mADC
 SG_ HU_APAModeSelect : 247|3@0+ (1,0) [0|7] ""  mADC
 SG_ HU_DVRUpdateReq : 289|2@0+ (1,0) [0|3] "" Vector__XXX
 SG_ HU_LicenseNumberCheckSum : 284|8@0+ (1,0) [0|255] "" Vector__XXX
 SG_ HU_LicenseNumber : 275|7@0+ (1,0) [0|127] "" Vector__XXX
 SG_ HU_LicenseNumberSet : 264|4@0+ (1,0) [0|15] "" Vector__XXX
 SG_ HU_WheelHubSet : 267|3@0+ (1,0) [0|7] "" Vector__XXX
 SG_ HU_BodyColourSet : 263|4@0+ (1,0) [0|15] "" Vector__XXX
 SG_ HU_AVMDVRReplayModeReq : 258|3@0+ (1,0) [0|7] "" Vector__XXX
 SG_ HU_HUDPosAdjustDec : 180|1@0+ (1,0) [0|1] "" Vector__XXX
 SG_ HU_HUDPosAdjustInc : 181|1@0+ (1,0) [0|1] "" Vector__XXX
 SG_ HU_VC_VR : 183|2@0+ (1,0) [0|3] "" Vector__XXX
 SG_ HU_Seeoffanimation : 143|1@0+ (1,0) [0|1] "" Vector__XXX
 SG_ HU_LanguageSync : 218|3@0+ (1,0) [0|7] ""  APA
 SG_ HU_DVREditSelected : 117|12@0+ (1,0) [0|4095] "" Vector__XXX
 SG_ HU_NaviIconNumber_2 : 135|4@0+ (1,0) [0|15] "" Vector__XXX
 SG_ HU_SurrondingMonitorDone : 151|1@0+ (1,0) [0|1] "" Vector__XXX
 SG_ HU_BcallReq : 150|2@0+ (1,0) [0|3] "" Vector__XXX
 SG_ HU_NaviIconNumber : 175|8@0+ (1,0) [0|255] "" Vector__XXX
 SG_ HU_NaviDistance : 144|17@0+ (1,0) [0|131070] "m"  ACC,LAS,mADC
 SG_ HU_DVRErrorRecord : 148|2@0+ (1,0) [0|3] "" Vector__XXX
 SG_ HU_DVRSystemImprint : 146|2@0+ (1,0) [0|3] "" Vector__XXX
 SG_ HU_SDCapacity : 129|2@0+ (1,0) [0|3] "" Vector__XXX
 SG_ HU_TUIDReq : 139|2@0+ (1,0) [0|3] "" Vector__XXX
 SG_ HU_RegisterStatus : 137|2@0+ (1,0) [0|3] "" Vector__XXX
 SG_ HU_AutoViewSet : 130|1@0+ (1,0) [0|1] "" Vector__XXX
 SG_ HU_RealTimeReq : 119|2@0+ (1,0) [0|3] "" Vector__XXX
 SG_ HU_RebroadcastReq : 97|2@0+ (1,0) [0|3] "" Vector__XXX
 SG_ HU_360AVMdetectionRequest : 108|5@0+ (1,0) [0|31] "" Vector__XXX
 SG_ HU_3DAVMReq : 32|2@0+ (1,0) [0|3] "" Vector__XXX
 SG_ HU_VisionAngleReq : 121|2@0+ (1,0) [0|3] "" Vector__XXX

BO_ 964 GW_3C4: 64 GW
 SG_ HU_CRCCheck_3C4 : 503|16@0+ (1,0) [0|65535] ""  ACC,LAS
 SG_ HU_RollingCounter_3C4 : 491|4@0+ (1,0) [0|15] ""  ACC,LAS
 SG_ HU_CRCCheck_3C7 : 319|8@0+ (1,0) [0|255] ""  LAS,ACC
 SG_ HU_RollingCounter_3C7 : 307|4@0+ (1,0) [0|15] ""  LAS,ACC
 SG_ HU_CRCCheck_3C6 : 255|8@0+ (1,0) [0|255] ""  LAS,ACC
 SG_ HU_RollingCounter_3C6 : 243|4@0+ (1,0) [0|15] ""  LAS,ACC
 SG_ HU_CRCCheck_3C4_2 : 191|8@0+ (1,0) [0|255] ""  LAS,ACC
 SG_ HU_RollingCounter_3C4_2 : 179|4@0+ (1,0) [0|15] ""  LAS,ACC
 SG_ HU_CRCCheck_3C2 : 127|8@0+ (1,0) [0|255] ""  LAS,ACC
 SG_ HU_RollingCounter_3C2 : 115|4@0+ (1,0) [0|15] ""  LAS,ACC
 SG_ HU_MapMatchStatus : 309|2@0+ (1,0) [0|3] ""  LAS,ACC,mADC
 SG_ HU_MapDataUpdateStatus : 118|3@0+ (1,0) [0|7] ""  LAS,ACC,mADC
 SG_ HU_RoadCurvature_600m : 281|10@0+ (1,0) [0|1023] "1/m"  LAS,ACC,mADC
 SG_ HU_RoadCurvature_400m : 275|10@0+ (1,0) [0|1023] "1/m"  LAS,ACC,mADC
 SG_ HU_RoadCurvature_300m : 269|10@0+ (1,0) [0|1023] "1/m"  LAS,ACC,mADC
 SG_ HU_RoadCurvature_100m : 263|10@0+ (1,0) [0|1023] "1/m"  LAS,ACC,mADC
 SG_ HU_RoadCurvature_90m : 239|10@0+ (1,0) [0|1023] "1/m"  LAS,ACC,mADC
 SG_ HU_RoadCurvature_80m : 217|10@0+ (1,0) [0|1023] "1/m"  LAS,ACC,mADC
 SG_ HU_RoadCurvature_70m : 211|10@0+ (1,0) [0|1023] "1/m"  LAS,ACC,mADC
 SG_ HU_RoadCurvature_60m : 205|10@0+ (1,0) [0|1023] "1/m"  LAS,ACC,mADC
 SG_ HU_RoadCurvature_50m : 199|10@0+ (1,0) [0|1023] "1/m"  LAS,ACC,mADC
 SG_ HU_RoadCurvature_40m : 161|10@0+ (1,0) [0|1023] "1/m"  LAS,ACC,mADC
 SG_ HU_RoadCurvature_30m : 155|10@0+ (1,0) [0|1023] "1/m"  LAS,ACC,mADC
 SG_ HU_RoadCurvature_20m : 149|10@0+ (1,0) [0|1023] "1/m"  LAS,ACC,mADC
 SG_ HU_RoadCurvature_10m : 143|10@0+ (1,0) [0|1023] "1/m"  LAS,ACC,mADC
 SG_ HU_Road_TrafficFlow : 105|3@0+ (1,0) [0|7] ""  LAS,ACC,mADC
 SG_ HU_Lane_Changtype : 129|2@0+ (1,0) [0|3] ""  LAS,ACC
 SG_ HU_To_NumchangeOfLanes_Dist : 135|6@0+ (10,0) [0|600] "m"  LAS,ACC
 SG_ HU_TollDis : 85|6@0+ (10,0) [0|600] "m"  LAS,ACC,mADC
 SG_ HU_TollInfo : 87|2@0+ (1,0) [0|3] ""  LAS,ACC,mADC
 SG_ HU_LaneCnt : 66|3@0+ (1,0) [0|7] ""  LAS,ACC,mADC
 SG_ HU_ForwardRoadType : 69|3@0+ (1,0) [0|7] ""  LAS,ACC,mADC
 SG_ HU_RampSide : 71|2@0+ (1,0) [0|3] ""  LAS,ACC,mADC
 SG_ HU_CRCCheck_3B8 : 63|8@0+ (1,0) [0|255] ""  LAS,ACC
 SG_ HU_RollingCounter_3B8 : 51|4@0+ (1,0) [0|15] ""  LAS,ACC
 SG_ HU_NavGuiganceStatus : 47|2@0+ (1,0) [0|3] ""  LAS,ACC,mADC
 SG_ HU_TunnelLength : 37|6@0+ (1,0) [0|63] "m"  LAS,ACC,mADC
 SG_ HU_RoadCurvatureFar : 17|10@0+ (1,0) [0|1023] ""  LAS,ACC,mADC
 SG_ HU_TunnelDistance : 23|6@0+ (10,0) [0|600] "m"  LAS,ACC,mADC
 SG_ HU_RoadCurvature : 1|10@0+ (1,0) [0|1023] ""  LAS,ACC,mADC
 SG_ HU_EnterTunnelInfo : 3|2@0+ (1,0) [0|3] ""  LAS,ACC,mADC

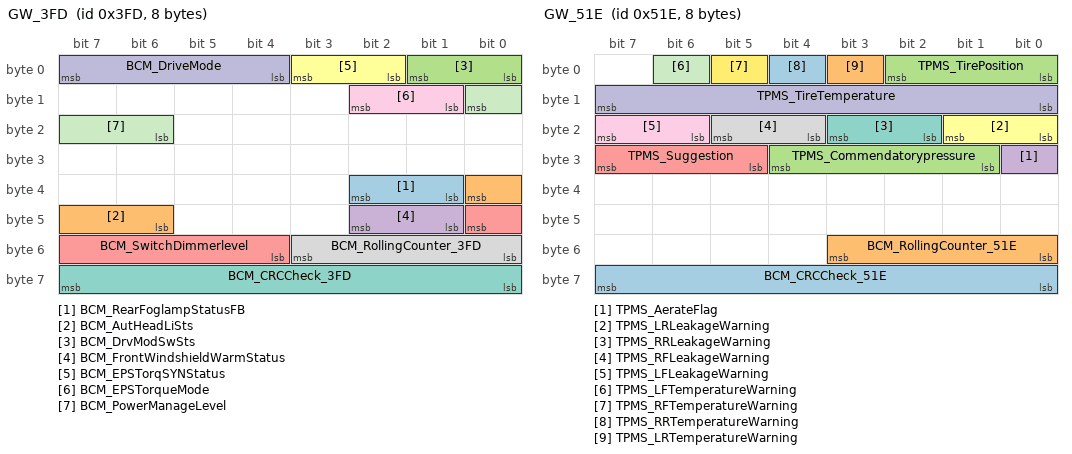
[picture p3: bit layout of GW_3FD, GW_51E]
BO_ 1021 GW_3FD: 8 GW
 SG_ BCM_RearFoglampStatusFB : 34|2@0+ (1,0) [0|3] "" Vector__XXX
 SG_ BCM_AutHeadLiSts : 32|3@0+ (1,0) [0|7] ""  mADC
 SG_ BCM_DrvModSwSts : 1|2@0+ (1,0) [0|3] "" Vector__XXX
 SG_ BCM_FrontWindshieldWarmStatus : 42|2@0+ (1,0) [0|3] ""  mADC
 SG_ BCM_SwitchDimmerlevel : 40|5@0+ (1,0) [0|31] "" Vector__XXX
 SG_ BCM_EPSTorqSYNStatus : 3|2@0+ (1,0) [0|3] "" Vector__XXX
 SG_ BCM_CRCCheck_3FD : 63|8@0+ (1,0) [0|255] ""  ACC,LAS,mADC
 SG_ BCM_RollingCounter_3FD : 51|4@0+ (1,0) [0|15] ""  ACC,LAS,mADC
 SG_ BCM_EPSTorqueMode : 10|2@0+ (1,0) [0|3] "" Vector__XXX
 SG_ BCM_DriveMode : 7|4@0+ (1,0) [0|15] ""  ACC,LAS,FC,mADC
 SG_ BCM_PowerManageLevel : 8|3@0+ (1,0) [0|7] ""  mADC,FC,ACC,LAS,APA

BO_ 1023 GW_3FF: 8 GW
 SG_ BCM_CRCCheck_3FF : 63|8@0+ (1,0) [0|255] ""  ACC,LAS,mADC
 SG_ BCM_RollingCounter_3FF : 51|4@0+ (1,0) [0|15] ""  ACC,LAS,mADC
 SG_ BCM_FloorLampStatus : 55|2@0+ (1,0) [0|3] "" Vector__XXX
 SG_ BCM_TurnIndicatorRightError : 46|1@0+ (1,0) [0|1] ""  mADC
 SG_ BCM_TurnIndicatorLeftError : 45|1@0+ (1,0) [0|1] ""  mADC
 SG_ BCM_PositionLampSwitchStatus : 44|1@0+ (1,0) [0|1] "" Vector__XXX
 SG_ LCM_DRLSts : 43|1@0+ (1,0) [0|1] "" Vector__XXX
 SG_ BCM_FollowMeHomeLightSetStatus : 42|3@0+ (1,0) [0|7] "" Vector__XXX
 SG_ BCM_RightDayLampError : 35|1@0+ (1,0) [0|1] "" Vector__XXX
 SG_ BCM_LeftDayLampError : 34|1@0+ (1,0) [0|1] "" Vector__XXX
 SG_ BCM_RightFrontFoglampError : 28|1@0+ (1,0) [0|1] ""  mADC
 SG_ BCM_LeftFrontFoglampError : 27|1@0+ (1,0) [0|1] ""  mADC
 SG_ BCM_RightLowBeamError : 26|1@0+ (1,0) [0|1] ""  ACC,LAS,FC,mADC
 SG_ BCM_LeftLowBeamError : 25|1@0+ (1,0) [0|1] ""  ACC,LAS,FC,mADC
 SG_ BCM_FrontPositionLampError : 23|1@0+ (1,0) [0|1] "" Vector__XXX
 SG_ BCM_HighBeamLampError : 53|1@0+ (1,0) [0|1] ""  mADC
 SG_ BCM_AutoHeadlightSts : 22|1@0+ (1,0) [0|1] ""  ACC,LAS,FC,mADC
 SG_ BCM_FrontFoglampStatus : 21|2@0+ (1,0) [0|3] ""  ACC,LAS,mADC
 SG_ BCM_FollowMeTurnon : 15|1@0+ (1,0) [0|1] "" Vector__XXX
 SG_ BCM_PositionLampStatus : 17|2@0+ (1,0) [0|3] ""  APA
 SG_ PEPS_WelcomeLightStaus : 14|2@0+ (1,0) [0|3] "" Vector__XXX
 SG_ BCM_Musiclightfeedback : 12|2@0+ (1,0) [0|3] "" Vector__XXX
 SG_ BCM_MusicPlayRequestSignal : 7|2@0+ (1,0) [0|3] "" Vector__XXX
 SG_ BCM_MusicLightModeSelectSts : 2|3@0+ (1,0) [0|7] "" Vector__XXX

BO_ 1310 GW_51E: 8 GW
 SG_ BCM_CRCCheck_51E : 63|8@0+ (1,0) [0|255] "" Vector__XXX
 SG_ BCM_RollingCounter_51E : 51|4@0+ (1,0) [0|15] "" Vector__XXX
 SG_ TPMS_Commendatorypressure : 28|4@0+ (1,0) [0|15] "" Vector__XXX
 SG_ TPMS_AerateFlag : 24|1@0+ (1,0) [0|1] "" Vector__XXX
 SG_ TPMS_Suggestion : 31|3@0+ (1,0) [0|7] "" Vector__XXX
 SG_ TPMS_LRLeakageWarning : 17|2@0+ (1,0) [0|3] "" Vector__XXX
 SG_ TPMS_RRLeakageWarning : 19|2@0+ (1,0) [0|3] "" Vector__XXX
 SG_ TPMS_RFLeakageWarning : 21|2@0+ (1,0) [0|3] "" Vector__XXX
 SG_ TPMS_LFLeakageWarning : 23|2@0+ (1,0) [0|3] "" Vector__XXX
 SG_ TPMS_TireTemperature : 15|8@0+ (1,-40) [-40|215] "°C"  ACC,LAS
 SG_ TPMS_LFTemperatureWarning : 6|1@0+ (1,0) [0|1] "" Vector__XXX
 SG_ TPMS_RFTemperatureWarning : 5|1@0+ (1,0) [0|1] "" Vector__XXX
 SG_ TPMS_RRTemperatureWarning : 4|1@0+ (1,0) [0|1] "" Vector__XXX
 SG_ TPMS_LRTemperatureWarning : 3|1@0+ (1,0) [0|1] "" Vector__XXX
 SG_ TPMS_TirePosition : 2|3@0+ (1,0) [0|4] ""  ACC,LAS

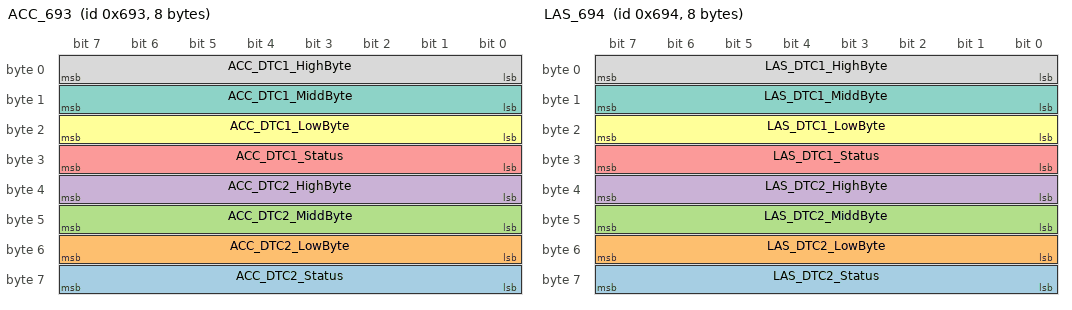
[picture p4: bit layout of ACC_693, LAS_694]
BO_ 1683 ACC_693: 8 ACC
 SG_ ACC_DTC2_Status : 63|8@0+ (1,0) [0|255] ""  GW,mADC
 SG_ ACC_DTC2_LowByte : 55|8@0+ (1,0) [0|255] ""  GW,mADC
 SG_ ACC_DTC2_MiddByte : 47|8@0+ (1,0) [0|255] ""  GW,mADC
 SG_ ACC_DTC2_HighByte : 39|8@0+ (1,0) [0|255] ""  GW,mADC
 SG_ ACC_DTC1_Status : 31|8@0+ (1,0) [0|255] ""  GW,mADC
 SG_ ACC_DTC1_LowByte : 23|8@0+ (1,0) [0|255] ""  GW,mADC
 SG_ ACC_DTC1_MiddByte : 15|8@0+ (1,0) [0|255] ""  GW,mADC
 SG_ ACC_DTC1_HighByte : 7|8@0+ (1,0) [0|255] ""  GW,mADC

BO_ 1684 LAS_694: 8 LAS
 SG_ LAS_DTC2_Status : 63|8@0+ (1,0) [0|255] ""  GW,FC
 SG_ LAS_DTC2_LowByte : 55|8@0+ (1,0) [0|255] ""  GW,FC
 SG_ LAS_DTC2_MiddByte : 47|8@0+ (1,0) [0|255] ""  GW,FC
 SG_ LAS_DTC2_HighByte : 39|8@0+ (1,0) [0|255] ""  GW,FC
 SG_ LAS_DTC1_Status : 31|8@0+ (1,0) [0|255] ""  GW,FC
 SG_ LAS_DTC1_LowByte : 23|8@0+ (1,0) [0|255] ""  GW,FC
 SG_ LAS_DTC1_MiddByte : 15|8@0+ (1,0) [0|255] ""  GW,FC
 SG_ LAS_DTC1_HighByte : 7|8@0+ (1,0) [0|255] ""  GW,FC

BO_ 1106 LAS_452: 8 LAS
 SG_ NM_message452 : 0|1@0+ (1,0) [1|1] ""  FC,GW,BDC

CM_ BO_ 381 " ";
CM_ SG_ 381 PCU_RollingCounter_1C4 " ";
CM_ SG_ 381 PCU_RearMotSts " ";
CM_ SG_ 381 PCU_PwrIndcdRealTqRearWhl "ACC 主控则ACC接收，LAS 主控则LAS接收 ";
CM_ SG_ 381 PCU_PwrIndcdDrvrReqTqWhlRear "ACC 主控则ACC接收，LAS 主控则LAS接收 ";
CM_ SG_ 381 PCU_ESPTqReqAvlRear " ";
CM_ SG_ 381 PCU_CRCCheck_1C4 " ";
CM_ SG_ 381 PCU_RollingCounter_1BE " ";
CM_ SG_ 381 PCU_MbRegenWhlRear " ";
CM_ SG_ 381 PCU_MbRegenMaxWhlTotal " ";
CM_ SG_ 381 PCU_MbRegenMaxRearWhl " ";
CM_ SG_ 381 PCU_CRCCheck_1BE " ";
CM_ SG_ 381 PCU_PwrTrainSts "ACC 主控则ACC接收，LAS 主控则LAS接收 ";
CM_ SG_ 381 PCU_RollingCounter_1A6 " ";
CM_ SG_ 381 PCU_MbRegenWhlFront " ";
CM_ SG_ 381 PCU_MbRegenMaxWhlQlfr " ";
CM_ SG_ 381 PCU_MbRegenMaxFrontWhlVld " ";
CM_ SG_ 381 PCU_MbRegenMaxFrontWhl " ";
CM_ SG_ 381 PCU_CRCCheck_1A6 " ";
CM_ SG_ 381 PCU_APATorqRequestAvailable "APA配置接收方无BDC ";
CM_ SG_ 381 PCU_APARequestEnable "APA配置接收方无BDC ";
CM_ SG_ 381 PCU_AccPedlVld "ACC 主控则ACC接收，LAS 主控则LAS接收 ";
CM_ SG_ 381 PCU_AccPedl "RMU法规要求
ACC 主控则ACC接收，LAS 主控则LAS接收 ";
CM_ SG_ 381 PCU_StartStopActiveVld " ";
CM_ SG_ 381 PCU_StartStopActive " ";
CM_ SG_ 381 PCU_RollingCounter_211 " ";
CM_ SG_ 381 PCU_RearMotStsVld " ";
CM_ SG_ 381 PCU_QECACC "ACC 主控则ACC接收，LAS 主控则LAS接收 ";
CM_ SG_ 381 PCU_PwrIndcdRealTqWhlFailr "ACC 主控则ACC接收，LAS 主控则LAS接收 ";
CM_ SG_ 381 PCU_PwrIndcdRealTqFrontWhl "ACC 主控则ACC接收，LAS 主控则LAS接收 ";
CM_ SG_ 381 PCU_PwrIndcdDrvrReqTqWhlFront "ACC 主控则ACC接收，LAS 主控则LAS接收 ";
CM_ SG_ 381 PCU_FrontMotStsVld " ";
CM_ SG_ 381 PCU_FrontMotSts " ";
CM_ SG_ 381 PCU_ESPTqReqAvlFront " ";
CM_ SG_ 381 PCU_EngStsVld " ";
CM_ SG_ 381 PCU_EngSts " ";
CM_ SG_ 381 PCU_EngClutchStsVld " ";
CM_ SG_ 381 PCU_EngClutchSts " ";
CM_ SG_ 381 PCU_ECGPOvrd "ACC 主控则ACC接收，LAS 主控则LAS接收 ";
CM_ SG_ 381 PCU_CRCCheck_211 " ";
CM_ SG_ 381 PCU_AccReqPossible "ACC 主控则ACC接收，LAS 主控则LAS接收 ";
CM_ SG_ 381 RGearbox_ActualDrivingGear " ";
CM_ SG_ 381 PCU_TarGearReqValid "ACC 主控则ACC接收，LAS 主控则LAS接收 ";
CM_ SG_ 381 PCU_TarGearReq "ACC 主控则ACC接收，LAS 主控则LAS接收 ";
CM_ SG_ 381 PCU_RollingCounter_1C6 "，类型增加REEV ";
CM_ SG_ 381 PCU_RealAccPedlVld "ACC 主控则ACC接收，LAS 主控则LAS接收 ";
CM_ SG_ 381 PCU_RealAccPedl "APA配置接收方无BDC ";
CM_ SG_ 381 PCU_K3CluSts " ";
CM_ SG_ 381 PCU_ClrDiagcInfo " ";
CM_ SG_ 381 PCU_FuCutOffReq " ";
CM_ SG_ 381 PCU_VehSts "
0x0=静止
0x1=电机驱动
0x2=串联驱动
0x3=并联驱动
0x4=能量回收（将制动,滑行能量回收合并为能量回收）
0x5=并联充电
0x6=车辆静止，怠速充电
0x7=怠速 ";
CM_ SG_ 381 PCU_VehSpdVld " ";
CM_ SG_ 381 PCU_VehSpd " ";
CM_ SG_ 381 PCU_SOCDisp " ";
CM_ SG_ 381 PCU_CRCID191 " ";
CM_ SG_ 381 PCU_ChrgUnlckILimReq " ";
CM_ SG_ 381 PCU_ChrgSuspReq "充电枪电子锁需要 ";
CM_ SG_ 381 PCU_ChrgIReqLimFac " ";
CM_ SG_ 381 PCU_ChrgAllwd " ";
CM_ SG_ 381 PCU_CHMAsignalSts " ";
CM_ SG_ 381 PCU_BMSOperModReq " ";
CM_ SG_ 381 PCU_BattIntrHeatAllwd " ";
CM_ SG_ 381 PCU_ActHVPwrCnsExt " ";
CM_ SG_ 381 PCU_191CycCntr " ";
CM_ BO_ 382 " ";
CM_ SG_ 382 EPS_Pinionang_Valid " ";
CM_ SG_ 382 EPS_Handwheel_Relang_Valid " ";
CM_ SG_ 382 EPS_Handwheel_Relang " ";
CM_ SG_ 382 EPS_Pinionang " ";
CM_ SG_ 382 EPS_LatCtrlActive "平台为10ms，CD569特例为8ms ";
CM_ SG_ 382 EPS_LatCtrlAvailabilityStatus "平台为10ms，CD569特例为8ms ";
CM_ SG_ 382 EPS_CRCCheck_17E "平台为10ms，CD569特例为8ms ";
CM_ SG_ 382 EPS_RollingCounter_17E "1.rolling counter
2.平台为10ms，CD569特例为8ms ";
CM_ SG_ 382 EPS_MeasuredTorsionBarTorqValid "平台为10ms，CD569特例为8ms ";
CM_ SG_ 382 EPS_MeasuredTorsionBarTorque "平台为10ms，CD569特例为8ms ";
CM_ BO_ 442 " ";
CM_ SG_ 442 ACC_CRCCheck_1BA_0 "ACC 主控则ACC发送，LAS 主控则LAS发送 ";
CM_ SG_ 442 ACC_RollingCounter_1BA_0 "ACC 主控则ACC发送，LAS 主控则LAS发送 ";
CM_ SG_ 442 ACC_LatAngReqActive "ACC 主控则ACC发送，LAS 主控则LAS发送 ";
CM_ SG_ 442 ACC_LatAngReq "ACC 主控则ACC发送，LAS 主控则LAS发送 ";
CM_ SG_ 442 ACC_MotorTorqueMinLimitRequest "ACC 主控则ACC发送，LAS 主控则LAS发送 ";
CM_ SG_ 442 ACC_MotorTorqueMaxLimitRequest "ACC 主控则ACC发送，LAS 主控则LAS发送 ";
CM_ BO_ 523 " ";
CM_ SG_ 523 IBCU_precheckStatus "APA配置接收方无BDC ";
CM_ SG_ 523 Wheel_Speed_RR_Pulse "All4wheelpulsesignalsaresentbyABSwithoutfiltering.Theriseedgeandfalledgearebothcountedinit,thewheelpulsemustbesequentialintheway0,1,2…254,0,1… ";
CM_ SG_ 523 Wheel_Speed_RR_Direction "APA配置接收方无BDC ";
CM_ SG_ 523 Wheel_Speed_RR_Data "APA配置接收方无BDC ";
CM_ SG_ 523 Wheel_Speed_RL_Pulse "All4wheelpulsesignalsaresentbyABSwithoutfiltering.Theriseedgeandfalledgearebothcountedinit,thewheelpulsemustbesequentialintheway0,1,2…254,0,2… ";
CM_ SG_ 523 Wheel_Speed_RL_Direction "APA配置接收方无BDC ";
CM_ SG_ 523 Wheel_Speed_RL_Data "APA配置接收方无BDC ";
CM_ SG_ 523 Wheel_Speed_FR_Pulse "All4wheelpulsesignalsaresentbyABSwithoutfiltering.Theriseedgeandfalledgearebothcountedinit,thewheelpulsemustbesequentialintheway0,1,2…254,0,3… ";
CM_ SG_ 523 Wheel_Speed_FR_Direction "APA配置接收方无BDC ";
CM_ SG_ 523 Wheel_Speed_FR_Data "APA配置接收方无BDC ";
CM_ SG_ 523 Wheel_Speed_FL_Pulse "All4wheelpulsesignalsaresentbyABSwithoutfiltering.Theriseedgeandfalledgearebothcountedinit,thewheelpulsemustbesequentialintheway0,1,2…254,0,4… ";
CM_ SG_ 523 Wheel_Speed_FL_Direction "APA配置接收方无BDC ";
CM_ SG_ 523 Wheel_Speed_FL_Data "APA配置接收方无BDC ";
CM_ SG_ 523 ESP_VehicleStandstill "APA配置接收方无BDC ";
CM_ SG_ 523 ESP_UrgencyBrakeAlarm " ";
CM_ SG_ 523 ESP_TODTorqueMaxLimit " ";
CM_ SG_ 523 ESP_RollingCounter_277 "rollingcounter ";
CM_ SG_ 523 ESP_RollingCounter_258 "258 ";
CM_ SG_ 523 ESP_RollingCounter_208 "rollingcounter ";
CM_ SG_ 523 ESP_RollingCounter_206 "rollingcounter ";
CM_ SG_ 523 ESP_QDCACC "ACC 主控则ACC接收，LAS 主控则LAS接收 ";
CM_ SG_ 523 ESP_PrefillAvailable "ACC 主控则ACC接收，LAS 主控则LAS接收 ";
CM_ SG_ 523 ESP_PrefillActive "ACC 主控则ACC接收，LAS 主控则LAS接收 ";
CM_ SG_ 523 ESP_MasCylBrakePressureValid "258 ";
CM_ SG_ 523 ESP_MasCylBrakePressure "indicatedthepressureofbrakemastercylinder,butnotthepressureofbrake ";
CM_ SG_ 523 ESP_IncreasePressureReqOK "建压成功后持续发15帧 ";
CM_ SG_ 523 ESP_HHC_Available "258 AT/DCT ";
CM_ SG_ 523 ESP_HHC_Active "258 ";
CM_ SG_ 523 ESP_ECDAvailable "ESP发送 ";
CM_ SG_ 523 ESP_ECDActive "ESP发送 ";
CM_ SG_ 523 ESP_CRCCheck_277 " ";
CM_ SG_ 523 ESP_CRCCheck_258 "258 ";
CM_ SG_ 523 ESP_CRCCheck_208 " ";
CM_ SG_ 523 ESP_CRCCheck_206 " ";
CM_ SG_ 523 ESP_CDP_ParkingAvailForACC " ";
CM_ SG_ 523 ESP_CDP_ParkingActiveForACC " ";
CM_ SG_ 523 ESP_CDD_Available_APA "APA配置接收方无BDC ";
CM_ SG_ 523 ESP_CDD_Available "ACC 主控则ACC接收，LAS 主控则LAS接收 ";
CM_ SG_ 523 ESP_CDD_Active_APA "APA配置接收方无BDC ";
CM_ SG_ 523 ESP_CDD_Active "ACC 主控则ACC接收，LAS 主控则LAS接收 ";
CM_ SG_ 523 ESP_BrakeLightOnRequest "258 ";
CM_ SG_ 523 ESP_BrakeForce "APA配置接收方无BDC ";
CM_ SG_ 523 ESP_AWBavailable "ACC 主控则ACC接收，LAS 主控则LAS接收 ";
CM_ SG_ 523 ESP_AWBactive "ACC 主控则ACC接收，LAS 主控则LAS接收 ";
CM_ SG_ 523 ESP_AutoHoldStandby "258 ";
CM_ SG_ 523 ESP_AutoHoldAvailable "258 ";
CM_ SG_ 523 ESP_AutoHoldActive "258 ";
CM_ SG_ 523 ESP_AEBdecActive "ACC 主控则ACC接收，LAS 主控则LAS接收 ";
CM_ SG_ 523 ESP_AEBAvailable "ACC 主控则ACC接收，LAS 主控则LAS接收 ";
CM_ SG_ 523 ESP_ABAavailable "ACC 主控则ACC接收，LAS 主控则LAS接收 ";
CM_ SG_ 523 ESP_ABAactive "ACC 主控则ACC接收，LAS 主控则LAS接收 ";
CM_ SG_ 523 ABS_TODFastOpenRequest " ";
CM_ BO_ 591 " ";
CM_ SG_ 591 EPS_SystemSt " ";
CM_ SG_ 591 EPS_LDW_ShakeLevStatus " ";
CM_ SG_ 591 EPS_EPSFailed "APA配置接收方无BDC ";
CM_ SG_ 591 EPS_APA_Abortfeedback "APA配置接收方无BDC ";
CM_ SG_ 591 EPS_APA_EpasFAILED "APA needs ";
CM_ SG_ 591 EPS_APA_ControlFeedback "即EPS_PAS_Requestfeedback ";
CM_ BO_ 651 " ";
CM_ SG_ 651 BCM_RefuelReq "PHEV专用 ";
CM_ SG_ 651 PEPS_ShiftForbidRq "GW报文转发 ";
CM_ BO_ 721 " ";
CM_ SG_ 721 BCM_ReversePosition "MT车型 ";
CM_ BO_ 734 " ";
CM_ SG_ 734 IP_DriverLCDALEDSts "GW报文转发 ";
CM_ SG_ 734 IP_PassengerLCDALEDSts "GW报文转发 ";
CM_ SG_ 734 IP_DISFail "GW报文转发 ";
CM_ SG_ 734 IP_QDashACCFail "ACC 主控则ACC接收，LAS 主控则LAS接收 ";
CM_ BO_ 742 " ";
CM_ SG_ 742 EMS_WarmUpCycle " ";
CM_ SG_ 742 EMS_RollingCounter_2E6 " ";
CM_ SG_ 742 EMS_GeneralDenoStatusValid "TCU是否需要
法规需求 ";
CM_ SG_ 742 EMS_GeneralDenominatorStatus "TCU是否需要
法规需求 ";
CM_ SG_ 742 EMS_FirstIgnitionCycleCounter "TCU是否需要
法规需求 ";
CM_ SG_ 742 EMS_DrivingCycle "TCU是否需要 ";
CM_ SG_ 742 EMS_CRCCheck_2E6 " ";
CM_ SG_ 742 EMS_Coolreq " ";
CM_ BO_ 794 " ";
CM_ SG_ 794 ACC_AEBTargetLatRelSpeed "借鉴C385 ";
CM_ SG_ 794 ACC_ELKAlert "ACC 主控则ACC发送，LAS 主控则LAS发送 ";
CM_ SG_ 794 ACC_CRCCheck_367 "ACC 主控则ACC发送，LAS 主控则LAS发送 ";
CM_ SG_ 794 ACC_RollingCounter_367 "ACC 主控则ACC发送，LAS 主控则LAS发送 ";
CM_ SG_ 794 ACC_LatPathHeadingAngle "ACC 主控则ACC发送，LAS 主控则LAS发送 ";
CM_ SG_ 794 ACC_ELKEnableStatus "ACC 主控则ACC发送，LAS 主控则LAS发送 ";
CM_ SG_ 794 ACC_ELKInterventionMode "ACC 主控则ACC发送，LAS 主控则LAS发送 ";
CM_ SG_ 794 ACC_ELKMode "ACC 主控则ACC发送，LAS 主控则LAS发送 ";
CM_ SG_ 794 ACC_CRCCheck_30D "ACC 主控则ACC发送，LAS 主控则LAS发送 ";
CM_ SG_ 794 ACC_RollingCounter_30D "ACC 主控则ACC发送，LAS 主控则LAS发送 ";
CM_ SG_ 794 ACC_RRLaneDetection "ACC 主控则ACC发送，LAS 主控则LAS发送 ";
CM_ SG_ 794 ACC_LLLaneDetection "ACC 主控则ACC发送，LAS 主控则LAS发送 ";
CM_ SG_ 794 ACC_HighBeamControl "ACC 主控则ACC发送，LAS 主控则LAS发送 ";
CM_ SG_ 794 ACC_TargetBasedLateralControl "ACC 主控则ACC发送，LAS 主控则LAS发送 ";
CM_ SG_ 794 ACC_IACCHWATextInfoForDriver "ACC 主控则ACC发送，LAS 主控则LAS发送 ";
CM_ SG_ 794 ACC_EmergencyLightingRequest "ACC 主控则ACC发送，LAS 主控则LAS发送 ";
CM_ SG_ 794 ACC_DriverHandsOffStatus "ACC 主控则ACC发送，LAS 主控则LAS发送 ";
CM_ SG_ 794 ACC_IACCHWAMode "ACC 主控则ACC发送，LAS 主控则LAS发送 ";
CM_ SG_ 794 ACC_CRCCheck_30A "ACC 主控则ACC发送，LAS 主控则LAS发送 ";
CM_ SG_ 794 ACC_RollingCounter_30A "ACC 主控则ACC发送，LAS 主控则LAS发送 ";
CM_ SG_ 794 ACC_LaneChangeStatus "800W摄像头使用 ";
CM_ SG_ 794 ACC_RoadCurvatureFar "1、向左为正，向右为负
2、ACC 主控则ACC发送，LAS 主控则LAS发送 ";
CM_ SG_ 794 ACC_RoadCurvatureNear "1、向左为正，向右为负
2、ACC 主控则ACC发送，LAS 主控则LAS发送 ";
CM_ SG_ 794 ACC_RoadCurvature "ACC 主控则ACC发送，LAS 主控则LAS发送 ";
CM_ SG_ 794 ACC_IACCHWAEnable "ACC 主控则ACC发送，LAS 主控则LAS发送 ";
CM_ SG_ 794 ACC_RLaneMarkerType "ACC 主控则ACC发送，LAS 主控则LAS发送，其余由APA或AVM发送 ";
CM_ SG_ 794 ACC_LLaneMarkerType "ACC 主控则ACC发送，LAS 主控则LAS发送，其余由APA或AVM发送 ";
CM_ SG_ 794 ACC_HostLaneRightStatus "ACC 主控则ACC发送，LAS 主控则LAS发送，其余由APA或AVM发送 ";
CM_ SG_ 794 ACC_HostLaneLeftStatus "ACC 主控则ACC发送，LAS 主控则LAS发送，其余由APA或AVM发送 ";
CM_ SG_ 794 ACC_LASWarningModeSelectionSts "ACC 主控则ACC发送，LAS 主控则LAS发送 ";
CM_ SG_ 794 ACC_LASModeSelectionStatus "ACC 主控则ACC发送，LAS 主控则LAS发送 ";
CM_ SG_ 794 ACC_CRCCheck_36D "ACC 主控则ACC发送，LAS 主控则LAS发送 ";
CM_ SG_ 794 ACC_RollingCounter_36D "ACC 主控则ACC发送，LAS 主控则LAS发送 ";
CM_ SG_ 794 ACC_FRadarFailureStatus " ";
CM_ SG_ 794 ACC_AEBTargetLatRange "ACC 主控则ACC发送，LAS 主控则LAS发送 ";
CM_ SG_ 794 ACC_AEBTargetRelSpeed "ACC 主控则ACC发送，LAS 主控则LAS发送 ";
CM_ SG_ 794 ACC_AEBTargetLngRange "1、负数代表向后，正数代表向前，原点为前雷达波束发射面
2、ACC 主控则ACC发送，LAS 主控则LAS发送 ";
CM_ SG_ 794 ACC_Voiceinfo "ACC 主控则ACC发送，LAS 主控则LAS发送 ";
CM_ SG_ 794 ACC_AEBTargetmode "ACC 主控则ACC发送，LAS 主控则LAS发送 ";
CM_ SG_ 794 ACC_AEBTextInfo "ACC 主控则ACC发送，LAS 主控则LAS发送 ";
CM_ SG_ 794 ACC_AEBStatus "ACC 主控则ACC发送，LAS 主控则LAS发送 ";
CM_ BO_ 853 "源端P_EMS_355 ";
CM_ SG_ 853 EMS_CRCCheck_355 " ";
CM_ SG_ 853 EMS_CruiseDistance "1、无相关配置时保留信号默认发0
2、ACC 主控则ACC接收，LAS 主控则LAS接收 ";
CM_ SG_ 853 EMS_CruiseSwitchSET "1、无相关配置时保留信号默认发0
2、ACC 主控则ACC接收，LAS 主控则LAS接收 ";
CM_ SG_ 853 EMS_CruiseSwitchCANCEL "1、无相关配置时保留信号默认发0
2、ACC 主控则ACC接收，LAS 主控则LAS接收 ";
CM_ SG_ 853 EMS_CruiseSwitchResume "1、无相关配置时保留信号默认发0
2、ACC 主控则ACC接收，LAS 主控则LAS接收 ";
CM_ SG_ 853 EMS_CruiseSwitchOnOff "1、无相关配置时保留信号默认发0
2、ACC 主控则ACC接收，LAS 主控则LAS接收 ";
CM_ BO_ 943 " ";
CM_ SG_ 943 HU_Novice_Enable " ";
CM_ SG_ 943 HU_ADAS_Posn_Offset " ";
CM_ SG_ 943 HU_ADAS_Posn_Pathldx " ";
CM_ SG_ 943 HU_EHPHeartFlag " ";
CM_ SG_ 943 HU_EHRHeartFlag " ";
CM_ SG_ 943 HU_LaneType_ID6 " ";
CM_ SG_ 943 HU_LaneType_ID5 " ";
CM_ SG_ 943 HU_LaneType_ID4 " ";
CM_ SG_ 943 HU_LaneType_ID3 " ";
CM_ SG_ 943 HU_LaneType_ID2 " ";
CM_ SG_ 943 HU_LaneType_ID1 " ";
CM_ SG_ 943 HU_ServiceRoadDis " ";
CM_ SG_ 943 HU_ServiceRoad " ";
CM_ SG_ 943 HU_WeatherType " ";
CM_ SG_ 943 HU_BridgeDis " ";
CM_ SG_ 943 HU_BridgeInfo " ";
CM_ SG_ 943 HU_AccidentProneDistance " ";
CM_ SG_ 943 HU_AccidentProne " ";
CM_ SG_ 943 HU_IntervalVelocityDis " ";
CM_ SG_ 943 HU_IntervalVelocityInfo " ";
CM_ SG_ 943 HU_SlopeGradient_100m " ";
CM_ SG_ 943 HU_SlopeGradient_50m " ";
CM_ SG_ 943 HU_SlopeGradient_40m " ";
CM_ SG_ 943 HU_SlopeGradient_30m " ";
CM_ SG_ 943 HU_SlopeGradient_20m " ";
CM_ SG_ 943 HU_SlopeGradient_10m " ";
CM_ BO_ 947 " ";
CM_ SG_ 947 BCM_DoorHandle_TimeDifference "1、检测到第一个输入变低时开始计时，输出停止前检测到第二个输入变低时停止计时，CAN信号的时间为两个输入变化的时间，发送三帧，
2、两个都未到位发送无效值，
3、展开或者折叠时如果在最大驱动时间内都未收到最后一个到位（第一个收到了），则发送无效值
4、3帧信号还没有更新完成时，如果又触发计时逻辑，按后一次的时间更新CAN信号，不保持上一次3帧发完 ";
CM_ BO_ 957 " ";
CM_ SG_ 957 HU_RearFoglampSet " ";
CM_ SG_ 957 HU_AutoHeadLiSet " ";
CM_ SG_ 957 HU_RADSSwitch " ";
CM_ SG_ 957 HU_RollingCounter_394 " ";
CM_ SG_ 957 HU_CurrentMedia_Info " ";
CM_ SG_ 957 HU_HWAEnable " ";
CM_ SG_ 957 HU_Compass "仪表车头朝向指北针罗盘显示控制信号 ";
CM_ SG_ 957 HU_APARemoteDispSts " ";
CM_ SG_ 957 HU_RemoteDispSts " ";
CM_ SG_ 957 HU_IRLCEnable " ";
CM_ SG_ 957 HU_ADSRescueConfirm " ";
CM_ SG_ 957 HU_CSLAEnable "ACC 主控则ACC接收，LAS 主控则LAS接收 ";
CM_ SG_ 957 HU_UDLCEnable " ";
CM_ SG_ 957 HU_ESSEnable " ";
CM_ SG_ 957 HU_ELKEnable " ";
CM_ SG_ 957 HU_TLAEnable " ";
CM_ SG_ 957 HU_ASPModeSelect "需要HU判断逻辑,用户a秒之内未操作发送0x3（同用户直接点取消）,车机记忆NeverRemind状态,并根据情况响应APA发出的ASP可用请求,如果NeverRemind被勾选,则忽略APA的请求；NeverRemind可以在设置中取消；
APP收到0x3后退出到遥控泊车界面,同时车机退出显示,需要按键激活进入泊车界面,两个界面均显示ASP实际的状态。此时,无论从车机还是APP点击进入ASP,两个界面均同步显示相关信息(网关加密发送给RFBT) ";
CM_ SG_ 957 HU_DVRUpdateReq "GW报文转发 ";
CM_ SG_ 957 HU_LicenseNumberCheckSum "该信号是对车牌设置的校验，非该帧报文的校验
G ";
CM_ SG_ 957 HU_LicenseNumber "GW报文转发 ";
CM_ SG_ 957 HU_LicenseNumberSet "GW报文转发 ";
CM_ SG_ 957 HU_WheelHubSet "GW报文转发 ";
CM_ SG_ 957 HU_BodyColourSet "GW报文转发 ";
CM_ SG_ 957 HU_AVMDVRReplayModeReq "GW报文转发 ";
CM_ SG_ 957 HU_VC_VR "暂时C301使用 ";
CM_ SG_ 957 HU_VisionAngleReq "513(周期)和514(事件)，当前多数项目使用514(事件)报文。 ";
CM_ BO_ 964 " ";
CM_ SG_ 964 HU_CRCCheck_3C7 " ";
CM_ SG_ 964 HU_RollingCounter_3C7 " ";
CM_ SG_ 964 HU_CRCCheck_3C6 " ";
CM_ SG_ 964 HU_RollingCounter_3C6 " ";
CM_ SG_ 964 HU_CRCCheck_3C4_2 " ";
CM_ SG_ 964 HU_RollingCounter_3C4_2 " ";
CM_ SG_ 964 HU_CRCCheck_3C2 " ";
CM_ SG_ 964 HU_RollingCounter_3C2 " ";
CM_ SG_ 964 HU_MapMatchStatus " ";
CM_ SG_ 964 HU_MapDataUpdateStatus " ";
CM_ SG_ 964 HU_RoadCurvature_600m " ";
CM_ SG_ 964 HU_RoadCurvature_400m " ";
CM_ SG_ 964 HU_RoadCurvature_300m " ";
CM_ SG_ 964 HU_RoadCurvature_100m " ";
CM_ SG_ 964 HU_RoadCurvature_90m " ";
CM_ SG_ 964 HU_RoadCurvature_80m " ";
CM_ SG_ 964 HU_RoadCurvature_70m " ";
CM_ SG_ 964 HU_RoadCurvature_60m " ";
CM_ SG_ 964 HU_RoadCurvature_50m " ";
CM_ SG_ 964 HU_RoadCurvature_40m " ";
CM_ SG_ 964 HU_RoadCurvature_30m " ";
CM_ SG_ 964 HU_RoadCurvature_20m " ";
CM_ SG_ 964 HU_RoadCurvature_10m " ";
CM_ SG_ 964 HU_Road_TrafficFlow " ";
CM_ SG_ 964 HU_Lane_Changtype " ";
CM_ SG_ 964 HU_To_NumchangeOfLanes_Dist " ";
CM_ SG_ 964 HU_TollDis " ";
CM_ SG_ 964 HU_TollInfo " ";
CM_ SG_ 964 HU_LaneCnt " ";
CM_ SG_ 964 HU_ForwardRoadType " ";
CM_ SG_ 964 HU_RampSide " ";
CM_ BO_ 1021 " ";
CM_ SG_ 1021 BCM_RearFoglampStatusFB " ";
CM_ SG_ 1021 BCM_AutHeadLiSts " ";
CM_ SG_ 1021 BCM_DrvModSwSts "PHEV使用 ";
CM_ SG_ 1021 BCM_EPSTorqSYNStatus "GW报文转发 ";
CM_ SG_ 1021 BCM_DriveMode "ACC 主控则ACC接收，LAS 主控则LAS接收 ";
CM_ BO_ 1023 " ";
CM_ SG_ 1023 BCM_HighBeamLampError " ";
CM_ BO_ 1310 " ";
CM_ SG_ 1310 TPMS_LRTemperatureWarning "GW报文转发 ";
CM_ SG_ 1310 TPMS_TirePosition "GW报文转发 ";
CM_ BO_ 1683 " ";
CM_ SG_ 1683 ACC_DTC2_Status "DTC上传 ";
CM_ SG_ 1683 ACC_DTC2_LowByte "DTC上传 ";
CM_ SG_ 1683 ACC_DTC2_MiddByte "DTC上传 ";
CM_ SG_ 1683 ACC_DTC2_HighByte "DTC上传 ";
CM_ SG_ 1683 ACC_DTC1_Status "DTC上传 ";
CM_ SG_ 1683 ACC_DTC1_LowByte "DTC上传 ";
CM_ SG_ 1683 ACC_DTC1_MiddByte "DTC上传 ";
CM_ SG_ 1683 ACC_DTC1_HighByte "DTC上传 ";
CM_ BO_ 1684 " ";
CM_ SG_ 1684 LAS_DTC2_Status "DTC上传 ";
CM_ SG_ 1684 LAS_DTC2_LowByte "DTC上传 ";
CM_ SG_ 1684 LAS_DTC2_MiddByte "DTC上传 ";
CM_ SG_ 1684 LAS_DTC2_HighByte "DTC上传 ";
CM_ SG_ 1684 LAS_DTC1_Status "DTC上传 ";
CM_ SG_ 1684 LAS_DTC1_LowByte "DTC上传 ";
CM_ SG_ 1684 LAS_DTC1_MiddByte "DTC上传 ";
CM_ SG_ 1684 LAS_DTC1_HighByte "DTC上传 ";
CM_ BO_ 1106 "Diag--VDC--ADAS1 ";
BA_DEF_ SG_  "GenSigStartValue" INT 0 0;
BA_DEF_ SG_  "GenSigInvalidValue" STRING ;
BA_DEF_ SG_  "GenSigCycleTime" INT 0 0;
BA_DEF_ SG_  "GenSigSendType" ENUM  "Cyclic","OnWrite","OnWriteWithRepetition","OnChange","OnChangeWithRepetition","IfActive","IfActiveWithRepetition","NoSigSendType","NotUsed","NotUsed","NotUsed","NotUsed","NotUsed";
BA_DEF_ BO_  "GenMsgSendType" ENUM  "Cyclic","Event","NotUsed","NotUsed","NotUsed","Cyclic","NotUsed","IfActive","NoMsgSendType","NotUsed";
BA_DEF_ BO_  "GenMsgILSupport" ENUM  "No","Yes";
BA_DEF_ BO_  "GenMsgCycleTime" INT 0 65535;
BA_DEF_ BO_  "CANFD_BRS" ENUM  "0","1";
BA_DEF_ BO_  "VFrameFormat" ENUM  "StandardCAN","ExtendedCAN","reserved","reserved","reserved","reserved","reserved","reserved","reserved","reserved","reserved","reserved","reserved","reserved","StandardCAN_FD","ExtendedCAN_FD";
BA_DEF_DEF_  "GenSigStartValue" 0;
BA_DEF_DEF_  "GenSigInvalidValue" "/";
BA_DEF_DEF_  "GenSigCycleTime" 0;
BA_DEF_DEF_  "GenSigSendType" "Cyclic";
BA_DEF_DEF_  "GenMsgSendType" "NoMsgSendType";
BA_DEF_DEF_  "GenMsgILSupport" "Yes";
BA_DEF_DEF_  "GenMsgCycleTime" 0;
BA_DEF_DEF_  "CANFD_BRS" "1";
BA_DEF_DEF_  "VFrameFormat" "StandardCAN";
BA_ "GenMsgSendType" BO_ 381 0;
BA_ "GenMsgCycleTime" BO_ 381 10;
BA_ "VFrameFormat" BO_ 381 14;
BA_ "GenMsgSendType" BO_ 382 0;
BA_ "GenMsgCycleTime" BO_ 382 10;
BA_ "VFrameFormat" BO_ 382 14;
BA_ "GenMsgSendType" BO_ 442 0;
BA_ "GenMsgCycleTime" BO_ 442 10;
BA_ "VFrameFormat" BO_ 442 14;
BA_ "GenMsgSendType" BO_ 523 0;
BA_ "GenMsgCycleTime" BO_ 523 20;
BA_ "VFrameFormat" BO_ 523 14;
BA_ "GenMsgSendType" BO_ 591 0;
BA_ "GenMsgCycleTime" BO_ 591 20;
BA_ "VFrameFormat" BO_ 591 14;
BA_ "GenMsgSendType" BO_ 651 0;
BA_ "GenMsgCycleTime" BO_ 651 40;
BA_ "VFrameFormat" BO_ 651 14;
BA_ "GenMsgSendType" BO_ 721 0;
BA_ "GenMsgCycleTime" BO_ 721 40;
BA_ "VFrameFormat" BO_ 721 14;
BA_ "GenMsgSendType" BO_ 734 0;
BA_ "GenMsgCycleTime" BO_ 734 50;
BA_ "VFrameFormat" BO_ 734 14;
BA_ "GenMsgSendType" BO_ 742 0;
BA_ "GenMsgCycleTime" BO_ 742 50;
BA_ "VFrameFormat" BO_ 742 14;
BA_ "GenMsgSendType" BO_ 794 0;
BA_ "GenMsgCycleTime" BO_ 794 100;
BA_ "VFrameFormat" BO_ 794 14;
BA_ "GenMsgSendType" BO_ 853 0;
BA_ "GenMsgCycleTime" BO_ 853 100;
BA_ "VFrameFormat" BO_ 853 14;
BA_ "GenMsgSendType" BO_ 943 0;
BA_ "GenMsgCycleTime" BO_ 943 100;
BA_ "VFrameFormat" BO_ 943 14;
BA_ "GenMsgSendType" BO_ 947 0;
BA_ "GenMsgCycleTime" BO_ 947 100;
BA_ "VFrameFormat" BO_ 947 14;
BA_ "GenMsgSendType" BO_ 957 0;
BA_ "GenMsgCycleTime" BO_ 957 100;
BA_ "VFrameFormat" BO_ 957 14;
BA_ "GenMsgSendType" BO_ 964 0;
BA_ "GenMsgCycleTime" BO_ 964 100;
BA_ "VFrameFormat" BO_ 964 14;
BA_ "GenMsgSendType" BO_ 1021 0;
BA_ "GenMsgCycleTime" BO_ 1021 100;
BA_ "VFrameFormat" BO_ 1021 14;
BA_ "GenMsgSendType" BO_ 1023 0;
BA_ "GenMsgCycleTime" BO_ 1023 100;
BA_ "VFrameFormat" BO_ 1023 14;
BA_ "GenMsgSendType" BO_ 1310 0;
BA_ "GenMsgCycleTime" BO_ 1310 500;
BA_ "VFrameFormat" BO_ 1310 14;
BA_ "GenMsgSendType" BO_ 1683 0;
BA_ "GenMsgCycleTime" BO_ 1683 500;
BA_ "VFrameFormat" BO_ 1683 14;
BA_ "GenMsgSendType" BO_ 1684 0;
BA_ "GenMsgCycleTime" BO_ 1684 500;
BA_ "VFrameFormat" BO_ 1684 14;
BA_ "GenMsgSendType" BO_ 1106 1;
BA_ "GenSigCycleTime" SG_ 381 PCU_RollingCounter_17D 10;
BA_ "GenSigCycleTime" SG_ 381 PCU_CRCCheck_17D 10;
BA_ "GenSigCycleTime" SG_ 381 PCU_RollingCounter_1C4 10;
BA_ "GenSigCycleTime" SG_ 381 PCU_RearMotSts 10;
BA_ "GenSigInvalidValue" SG_ 381 PCU_PwrIndcdRealTqRearWhl "32767";
BA_ "GenSigCycleTime" SG_ 381 PCU_PwrIndcdRealTqRearWhl 10;
BA_ "GenSigInvalidValue" SG_ 381 PCU_PwrIndcdDrvrReqTqWhlRear "32767";
BA_ "GenSigCycleTime" SG_ 381 PCU_PwrIndcdDrvrReqTqWhlRear 10;
BA_ "GenSigCycleTime" SG_ 381 PCU_ESPTqReqAvlRear 10;
BA_ "GenSigCycleTime" SG_ 381 PCU_CRCCheck_1C4 10;
BA_ "GenSigCycleTime" SG_ 381 PCU_RollingCounter_1BE 10;
BA_ "GenSigInvalidValue" SG_ 381 PCU_MbRegenWhlRear "65535";
BA_ "GenSigCycleTime" SG_ 381 PCU_MbRegenWhlRear 10;
BA_ "GenSigInvalidValue" SG_ 381 PCU_MbRegenMaxWhlTotal "65535";
BA_ "GenSigCycleTime" SG_ 381 PCU_MbRegenMaxWhlTotal 10;
BA_ "GenSigInvalidValue" SG_ 381 PCU_MbRegenMaxRearWhl "65535";
BA_ "GenSigCycleTime" SG_ 381 PCU_MbRegenMaxRearWhl 10;
BA_ "GenSigCycleTime" SG_ 381 PCU_CRCCheck_1BE 10;
BA_ "GenSigInvalidValue" SG_ 381 PCU_PwrTrainSts "3";
BA_ "GenSigCycleTime" SG_ 381 PCU_PwrTrainSts 10;
BA_ "GenSigCycleTime" SG_ 381 PCU_RollingCounter_1A6 10;
BA_ "GenSigInvalidValue" SG_ 381 PCU_MbRegenWhlFront "65535";
BA_ "GenSigCycleTime" SG_ 381 PCU_MbRegenWhlFront 10;
BA_ "GenSigCycleTime" SG_ 381 PCU_MbRegenMaxWhlQlfr 10;
BA_ "GenSigCycleTime" SG_ 381 PCU_MbRegenMaxFrontWhlVld 10;
BA_ "GenSigCycleTime" SG_ 381 PCU_MbRegenMaxFrontWhl 10;
BA_ "GenSigCycleTime" SG_ 381 PCU_CRCCheck_1A6 10;
BA_ "GenSigCycleTime" SG_ 381 PCU_APATorqRequestAvailable 10;
BA_ "GenSigInvalidValue" SG_ 381 PCU_APARequestEnable "3";
BA_ "GenSigCycleTime" SG_ 381 PCU_APARequestEnable 10;
BA_ "GenSigCycleTime" SG_ 381 PCU_AccPedlVld 10;
BA_ "GenSigCycleTime" SG_ 381 PCU_AccPedl 10;
BA_ "GenSigCycleTime" SG_ 381 PCU_StartStopActiveVld 10;
BA_ "GenSigCycleTime" SG_ 381 PCU_StartStopActive 10;
BA_ "GenSigCycleTime" SG_ 381 PCU_RollingCounter_211 10;
BA_ "GenSigCycleTime" SG_ 381 PCU_RearMotStsVld 10;
BA_ "GenSigCycleTime" SG_ 381 PCU_QECACC 10;
BA_ "GenSigInvalidValue" SG_ 381 PCU_PwrIndcdRealTqWhlFailr "1";
BA_ "GenSigCycleTime" SG_ 381 PCU_PwrIndcdRealTqWhlFailr 10;
BA_ "GenSigInvalidValue" SG_ 381 PCU_PwrIndcdRealTqFrontWhl "32767";
BA_ "GenSigCycleTime" SG_ 381 PCU_PwrIndcdRealTqFrontWhl 10;
BA_ "GenSigInvalidValue" SG_ 381 PCU_PwrIndcdDrvrReqTqWhlFront "32767";
BA_ "GenSigCycleTime" SG_ 381 PCU_PwrIndcdDrvrReqTqWhlFront 10;
BA_ "GenSigCycleTime" SG_ 381 PCU_FrontMotStsVld 10;
BA_ "GenSigCycleTime" SG_ 381 PCU_FrontMotSts 10;
BA_ "GenSigCycleTime" SG_ 381 PCU_ESPTqReqAvlFront 10;
BA_ "GenSigCycleTime" SG_ 381 PCU_EngStsVld 10;
BA_ "GenSigCycleTime" SG_ 381 PCU_EngSts 10;
BA_ "GenSigCycleTime" SG_ 381 PCU_EngClutchStsVld 10;
BA_ "GenSigCycleTime" SG_ 381 PCU_EngClutchSts 10;
BA_ "GenSigCycleTime" SG_ 381 PCU_ECGPOvrd 10;
BA_ "GenSigCycleTime" SG_ 381 PCU_CRCCheck_211 10;
BA_ "GenSigCycleTime" SG_ 381 PCU_AccReqPossible 10;
BA_ "GenSigInvalidValue" SG_ 381 RGearbox_ActualDrivingGear "3";
BA_ "GenSigCycleTime" SG_ 381 RGearbox_ActualDrivingGear 10;
BA_ "GenSigStartValue" SG_ 381 PCU_TrsmTarIdleSpdReq 800;
BA_ "GenSigCycleTime" SG_ 381 PCU_TrsmTarIdleSpdReq 10;
BA_ "GenSigCycleTime" SG_ 381 PCU_TarGearReqValid 10;
BA_ "GenSigInvalidValue" SG_ 381 PCU_TarGearReq "15";
BA_ "GenSigCycleTime" SG_ 381 PCU_TarGearReq 10;
BA_ "GenSigCycleTime" SG_ 381 PCU_SpdCtrlModSelect 10;
BA_ "GenSigCycleTime" SG_ 381 PCU_RollingCounter_1C6 10;
BA_ "GenSigCycleTime" SG_ 381 PCU_RealAccPedlVld 10;
BA_ "GenSigCycleTime" SG_ 381 PCU_RealAccPedl 10;
BA_ "GenSigCycleTime" SG_ 381 PCU_MILReq 10;
BA_ "GenSigCycleTime" SG_ 381 PCU_K3CluSts 10;
BA_ "GenSigCycleTime" SG_ 381 PCU_FlywhTqTransLoadActInvld 10;
BA_ "GenSigCycleTime" SG_ 381 PCU_FlywhTqTransLoadAct 10;
BA_ "GenSigStartValue" SG_ 381 PCU_EngTarIdleSpdReq 50;
BA_ "GenSigCycleTime" SG_ 381 PCU_EngTarIdleSpdReq 10;
BA_ "GenSigCycleTime" SG_ 381 PCU_EngStrtMod 10;
BA_ "GenSigCycleTime" SG_ 381 PCU_CRCCheck_1C6 10;
BA_ "GenSigCycleTime" SG_ 381 PCU_ClrDiagcInfo 10;
BA_ "GenSigCycleTime" SG_ 381 PCU_StrtTrqCtl 10;
BA_ "GenSigCycleTime" SG_ 381 PCU_StrtInhb 10;
BA_ "GenSigCycleTime" SG_ 381 PCU_RollingCounter_1E1 10;
BA_ "GenSigCycleTime" SG_ 381 PCU_PtStsChrgCrp 10;
BA_ "GenSigCycleTime" SG_ 381 PCU_FuCutOffReq 10;
BA_ "GenSigCycleTime" SG_ 381 PCU_EngIgnAgIntvEnbl 10;
BA_ "GenSigCycleTime" SG_ 381 PCU_EngTqFlywhSlowReq 10;
BA_ "GenSigCycleTime" SG_ 381 PCU_EngTqFlywhReqVld 10;
BA_ "GenSigCycleTime" SG_ 381 PCU_EngTqFlywhFastReq 10;
BA_ "GenSigCycleTime" SG_ 381 PCU_EngTqFlywhAllwdMaxVld 10;
BA_ "GenSigCycleTime" SG_ 381 PCU_EngTqFlywhAllwdMax 10;
BA_ "GenSigCycleTime" SG_ 381 PCU_EngStrtOrd 10;
BA_ "GenSigCycleTime" SG_ 381 PCU_EngStpOrd 10;
BA_ "GenSigCycleTime" SG_ 381 PCU_EMSSurgeDamperEna 10;
BA_ "GenSigCycleTime" SG_ 381 PCU_CRCCheck_1E1 10;
BA_ "GenSigCycleTime" SG_ 381 PCU_BrkPedlSts2 10;
BA_ "GenSigCycleTime" SG_ 381 PCU_BrkPedlSts1 10;
BA_ "GenSigCycleTime" SG_ 381 PCU_VehSts 10;
BA_ "GenSigCycleTime" SG_ 381 PCU_VehSpdVld 10;
BA_ "GenSigInvalidValue" SG_ 381 PCU_VehSpd "255";
BA_ "GenSigCycleTime" SG_ 381 PCU_VehSpd 10;
BA_ "GenSigInvalidValue" SG_ 381 PCU_SOCDisp "127";
BA_ "GenSigCycleTime" SG_ 381 PCU_SOCDisp 10;
BA_ "GenSigCycleTime" SG_ 381 PCU_CRCID191 10;
BA_ "GenSigCycleTime" SG_ 381 PCU_ChrgUnlckILimReq 10;
BA_ "GenSigCycleTime" SG_ 381 PCU_ChrgSuspReq 10;
BA_ "GenSigCycleTime" SG_ 381 PCU_ChrgIReqLimFac 10;
BA_ "GenSigCycleTime" SG_ 381 PCU_ChrgAllwd 10;
BA_ "GenSigCycleTime" SG_ 381 PCU_CHMAsignalSts 10;
BA_ "GenSigInvalidValue" SG_ 381 PCU_BMSOperModReq "7";
BA_ "GenSigCycleTime" SG_ 381 PCU_BMSOperModReq 10;
BA_ "GenSigCycleTime" SG_ 381 PCU_BattIntrHeatAllwd 10;
BA_ "GenSigInvalidValue" SG_ 381 PCU_ActHVPwrCnsExt "255";
BA_ "GenSigCycleTime" SG_ 381 PCU_ActHVPwrCnsExt 10;
BA_ "GenSigInvalidValue" SG_ 381 PCU_191CycCntr "15";
BA_ "GenSigCycleTime" SG_ 381 PCU_191CycCntr 10;
BA_ "GenSigCycleTime" SG_ 382 EPS_Pinionang_Valid 10;
BA_ "GenSigInvalidValue" SG_ 382 EPS_Handwheel_Relang_Valid "1";
BA_ "GenSigCycleTime" SG_ 382 EPS_Handwheel_Relang_Valid 10;
BA_ "GenSigInvalidValue" SG_ 382 EPS_Handwheel_Relang "32767";
BA_ "GenSigStartValue" SG_ 382 EPS_Handwheel_Relang 10800;
BA_ "GenSigCycleTime" SG_ 382 EPS_Handwheel_Relang 10;
BA_ "GenSigInvalidValue" SG_ 382 EPS_Pinionang "16383";
BA_ "GenSigStartValue" SG_ 382 EPS_Pinionang 7200;
BA_ "GenSigCycleTime" SG_ 382 EPS_Pinionang 10;
BA_ "GenSigInvalidValue" SG_ 382 EPS_LatCtrlActive "0";
BA_ "GenSigCycleTime" SG_ 382 EPS_LatCtrlActive 10;
BA_ "GenSigInvalidValue" SG_ 382 EPS_LatCtrlAvailabilityStatus "2";
BA_ "GenSigCycleTime" SG_ 382 EPS_LatCtrlAvailabilityStatus 10;
BA_ "GenSigCycleTime" SG_ 382 EPS_CRCCheck_17E 10;
BA_ "GenSigCycleTime" SG_ 382 EPS_RollingCounter_17E 10;
BA_ "GenSigInvalidValue" SG_ 382 EPS_MeasuredTorsionBarTorqValid "1";
BA_ "GenSigCycleTime" SG_ 382 EPS_MeasuredTorsionBarTorqValid 10;
BA_ "GenSigInvalidValue" SG_ 382 EPS_MeasuredTorsionBarTorque "4095";
BA_ "GenSigStartValue" SG_ 382 EPS_MeasuredTorsionBarTorque 2048;
BA_ "GenSigCycleTime" SG_ 382 EPS_MeasuredTorsionBarTorque 10;
BA_ "GenSigCycleTime" SG_ 442 ACC_CRCCheck_1BA_0 10;
BA_ "GenSigCycleTime" SG_ 442 ACC_RollingCounter_1BA_0 10;
BA_ "GenSigCycleTime" SG_ 442 ACC_LatAngReqActive 10;
BA_ "GenSigInvalidValue" SG_ 442 ACC_LatAngReq "14401";
BA_ "GenSigStartValue" SG_ 442 ACC_LatAngReq 7200;
BA_ "GenSigCycleTime" SG_ 442 ACC_LatAngReq 10;
BA_ "GenSigStartValue" SG_ 442 ACC_MotorTorqueMinLimitRequest 1024;
BA_ "GenSigCycleTime" SG_ 442 ACC_MotorTorqueMinLimitRequest 10;
BA_ "GenSigStartValue" SG_ 442 ACC_MotorTorqueMaxLimitRequest 1024;
BA_ "GenSigCycleTime" SG_ 442 ACC_MotorTorqueMaxLimitRequest 10;
BA_ "GenSigInvalidValue" SG_ 523 IBCU_BrkPedlStsGbVld "2";
BA_ "GenSigCycleTime" SG_ 523 IBCU_BrkPedlStsGbVld 20;
BA_ "GenSigInvalidValue" SG_ 523 IBCU_BrkPedoplStsGb "255";
BA_ "GenSigCycleTime" SG_ 523 IBCU_BrkPedoplStsGb 20;
BA_ "GenSigInvalidValue" SG_ 523 ESP_Vehicle_Speed_Reference "8191";
BA_ "GenSigCycleTime" SG_ 523 ESP_Vehicle_Speed_Reference 20;
BA_ "GenSigCycleTime" SG_ 523 IBCU_precheckStatus 20;
BA_ "GenSigCycleTime" SG_ 523 ESP_PrefillforAPA_Available 20;
BA_ "GenSigCycleTime" SG_ 523 ESP_PrefillforAPA_active 20;
BA_ "GenSigCycleTime" SG_ 523 IBCU_BrakeDiscHighTempWarning 20;
BA_ "GenSigCycleTime" SG_ 523 ESP_RollingCounter_20B 20;
BA_ "GenSigCycleTime" SG_ 523 ESP_CRCCheck_20B 20;
BA_ "GenSigInvalidValue" SG_ 523 Wheel_Speed_RR_Valid_Data "1";
BA_ "GenSigCycleTime" SG_ 523 Wheel_Speed_RR_Valid_Data 20;
BA_ "GenSigInvalidValue" SG_ 523 Wheel_Speed_RR_Pulse "255";
BA_ "GenSigCycleTime" SG_ 523 Wheel_Speed_RR_Pulse 20;
BA_ "GenSigCycleTime" SG_ 523 Wheel_Speed_RR_Direction 20;
BA_ "GenSigInvalidValue" SG_ 523 Wheel_Speed_RR_Data "8191";
BA_ "GenSigCycleTime" SG_ 523 Wheel_Speed_RR_Data 20;
BA_ "GenSigInvalidValue" SG_ 523 Wheel_Speed_RL_Valid_Data "1";
BA_ "GenSigCycleTime" SG_ 523 Wheel_Speed_RL_Valid_Data 20;
BA_ "GenSigInvalidValue" SG_ 523 Wheel_Speed_RL_Pulse "255";
BA_ "GenSigCycleTime" SG_ 523 Wheel_Speed_RL_Pulse 20;
BA_ "GenSigInvalidValue" SG_ 523 Wheel_Speed_RL_Direction "3";
BA_ "GenSigCycleTime" SG_ 523 Wheel_Speed_RL_Direction 20;
BA_ "GenSigInvalidValue" SG_ 523 Wheel_Speed_RL_Data "8191";
BA_ "GenSigCycleTime" SG_ 523 Wheel_Speed_RL_Data 20;
BA_ "GenSigInvalidValue" SG_ 523 Wheel_Speed_FR_Valid_Data "1";
BA_ "GenSigCycleTime" SG_ 523 Wheel_Speed_FR_Valid_Data 20;
BA_ "GenSigInvalidValue" SG_ 523 Wheel_Speed_FR_Pulse "255";
BA_ "GenSigCycleTime" SG_ 523 Wheel_Speed_FR_Pulse 20;
BA_ "GenSigInvalidValue" SG_ 523 Wheel_Speed_FR_Direction "3";
BA_ "GenSigCycleTime" SG_ 523 Wheel_Speed_FR_Direction 20;
BA_ "GenSigInvalidValue" SG_ 523 Wheel_Speed_FR_Data "8191";
BA_ "GenSigCycleTime" SG_ 523 Wheel_Speed_FR_Data 20;
BA_ "GenSigInvalidValue" SG_ 523 Wheel_Speed_FL_Valid_Data "1";
BA_ "GenSigCycleTime" SG_ 523 Wheel_Speed_FL_Valid_Data 20;
BA_ "GenSigInvalidValue" SG_ 523 Wheel_Speed_FL_Pulse "255";
BA_ "GenSigCycleTime" SG_ 523 Wheel_Speed_FL_Pulse 20;
BA_ "GenSigInvalidValue" SG_ 523 Wheel_Speed_FL_Direction "3";
BA_ "GenSigCycleTime" SG_ 523 Wheel_Speed_FL_Direction 20;
BA_ "GenSigInvalidValue" SG_ 523 Wheel_Speed_FL_Data "8191";
BA_ "GenSigCycleTime" SG_ 523 Wheel_Speed_FL_Data 20;
BA_ "GenSigCycleTime" SG_ 523 ESP_VehicleStandstill 20;
BA_ "GenSigCycleTime" SG_ 523 ESP_VDCActive 20;
BA_ "GenSigCycleTime" SG_ 523 ESP_UrgencyBrakeAlarm 20;
BA_ "GenSigInvalidValue" SG_ 523 ESP_TODTorqueMaxLimit "4095";
BA_ "GenSigCycleTime" SG_ 523 ESP_TODTorqueMaxLimit 20;
BA_ "GenSigCycleTime" SG_ 523 ESP_TCSActive 20;
BA_ "GenSigCycleTime" SG_ 523 ESP_RollingCounter_277 20;
BA_ "GenSigCycleTime" SG_ 523 ESP_RollingCounter_258 20;
BA_ "GenSigCycleTime" SG_ 523 ESP_RollingCounter_208 20;
BA_ "GenSigCycleTime" SG_ 523 ESP_RollingCounter_206 20;
BA_ "GenSigCycleTime" SG_ 523 ESP_QDCACC 20;
BA_ "GenSigCycleTime" SG_ 523 ESP_PrefillAvailable 20;
BA_ "GenSigCycleTime" SG_ 523 ESP_PrefillActive 20;
BA_ "GenSigCycleTime" SG_ 523 ESP_OnlyABSActive 20;
BA_ "GenSigCycleTime" SG_ 523 ESP_MasCylBrakePressureValid 20;
BA_ "GenSigInvalidValue" SG_ 523 ESP_MasCylBrakePressure "4095";
BA_ "GenSigCycleTime" SG_ 523 ESP_MasCylBrakePressure 20;
BA_ "GenSigInvalidValue" SG_ 523 ESP_IncreasePressureReqOK "0";
BA_ "GenSigCycleTime" SG_ 523 ESP_IncreasePressureReqOK 20;
BA_ "GenSigCycleTime" SG_ 523 ESP_HHC_Available 20;
BA_ "GenSigCycleTime" SG_ 523 ESP_HHC_Active 20;
BA_ "GenSigInvalidValue" SG_ 523 ESP_HDC_STATUS "3";
BA_ "GenSigCycleTime" SG_ 523 ESP_HDC_STATUS 20;
BA_ "GenSigCycleTime" SG_ 523 ESP_HBBActiveStatus 20;
BA_ "GenSigCycleTime" SG_ 523 ESP_ECDAvailable 20;
BA_ "GenSigCycleTime" SG_ 523 ESP_ECDActive 20;
BA_ "GenSigCycleTime" SG_ 523 ESP_CRCCheck_277 20;
BA_ "GenSigCycleTime" SG_ 523 ESP_CRCCheck_258 20;
BA_ "GenSigCycleTime" SG_ 523 ESP_CRCCheck_208 20;
BA_ "GenSigCycleTime" SG_ 523 ESP_CRCCheck_206 20;
BA_ "GenSigCycleTime" SG_ 523 ESP_CDP_ParkingAvailForACC 20;
BA_ "GenSigStartValue" SG_ 523 ESP_CDP_ParkingActiveForACC 1;
BA_ "GenSigCycleTime" SG_ 523 ESP_CDP_ParkingActiveForACC 20;
BA_ "GenSigCycleTime" SG_ 523 ESP_CDD_Available_APA 20;
BA_ "GenSigCycleTime" SG_ 523 ESP_CDD_Available 20;
BA_ "GenSigCycleTime" SG_ 523 ESP_CDD_Active_APA 20;
BA_ "GenSigCycleTime" SG_ 523 ESP_CDD_Active 20;
BA_ "GenSigCycleTime" SG_ 523 ESP_BrakeOverHeatBrakeDiscTemp 20;
BA_ "GenSigInvalidValue" SG_ 523 ESP_BrakeLightOnRequest "3";
BA_ "GenSigCycleTime" SG_ 523 ESP_BrakeLightOnRequest 20;
BA_ "GenSigCycleTime" SG_ 523 ESP_BrakeForce 20;
BA_ "GenSigCycleTime" SG_ 523 ESP_AWBavailable 20;
BA_ "GenSigCycleTime" SG_ 523 ESP_AWBactive 20;
BA_ "GenSigCycleTime" SG_ 523 ESP_AutoHoldStandby 20;
BA_ "GenSigCycleTime" SG_ 523 ESP_AutoHoldAvailable 20;
BA_ "GenSigCycleTime" SG_ 523 ESP_AutoHoldActive 20;
BA_ "GenSigCycleTime" SG_ 523 ESP_AEBdecActive 20;
BA_ "GenSigCycleTime" SG_ 523 ESP_AEBAvailable 20;
BA_ "GenSigCycleTime" SG_ 523 ESP_ABAavailable 20;
BA_ "GenSigCycleTime" SG_ 523 ESP_ABAactive 20;
BA_ "GenSigInvalidValue" SG_ 523 ABS_TODFastOpenRequest "3";
BA_ "GenSigCycleTime" SG_ 523 ABS_TODFastOpenRequest 20;
BA_ "GenSigInvalidValue" SG_ 591 EPS_SystemSt "15";
BA_ "GenSigCycleTime" SG_ 591 EPS_SystemSt 20;
BA_ "GenSigCycleTime" SG_ 591 EPS_LDW_ShakeLevStatus 20;
BA_ "GenSigInvalidValue" SG_ 591 EPS_ConcussAvailabilityStatus "2";
BA_ "GenSigCycleTime" SG_ 591 EPS_ConcussAvailabilityStatus 20;
BA_ "GenSigStartValue" SG_ 591 EPS_TorqueAssistMode 3;
BA_ "GenSigCycleTime" SG_ 591 EPS_TorqueAssistMode 20;
BA_ "GenSigCycleTime" SG_ 591 EPS_IACC_abortreason 20;
BA_ "GenSigCycleTime" SG_ 591 EPS_ModeSwitchSt 20;
BA_ "GenSigCycleTime" SG_ 591 EPS_EPSFailed 20;
BA_ "GenSigInvalidValue" SG_ 591 EPS_SteeringTorque "255";
BA_ "GenSigStartValue" SG_ 591 EPS_SteeringTorque 127;
BA_ "GenSigCycleTime" SG_ 591 EPS_SteeringTorque 20;
BA_ "GenSigCycleTime" SG_ 591 EPS_TorqSensorStatus 20;
BA_ "GenSigInvalidValue" SG_ 591 EPS_ElectPowerConsumption "255";
BA_ "GenSigCycleTime" SG_ 591 EPS_ElectPowerConsumption 20;
BA_ "GenSigCycleTime" SG_ 591 EPS_CRCCheck_24F 20;
BA_ "GenSigCycleTime" SG_ 591 EPS_RollingCounter_24F 20;
BA_ "GenSigCycleTime" SG_ 591 EPS_APA_Abortfeedback 20;
BA_ "GenSigCycleTime" SG_ 591 EPS_APA_EpasFAILED 20;
BA_ "GenSigCycleTime" SG_ 591 EPS_APA_ControlFeedback 20;
BA_ "GenSigCycleTime" SG_ 651 BCM_RefuelReq 40;
BA_ "GenSigInvalidValue" SG_ 651 BCM_TrunkReleaseTrigger "0";
BA_ "GenSigCycleTime" SG_ 651 BCM_TrunkReleaseTrigger 40;
BA_ "GenSigInvalidValue" SG_ 651 BCM_LockTrigger "0";
BA_ "GenSigCycleTime" SG_ 651 BCM_LockTrigger 40;
BA_ "GenSigInvalidValue" SG_ 651 BCM_UnlockTrigger "0";
BA_ "GenSigCycleTime" SG_ 651 BCM_UnlockTrigger 40;
BA_ "GenSigCycleTime" SG_ 651 BCM_CRCCheck_28B 40;
BA_ "GenSigCycleTime" SG_ 651 BCM_RollingCounter_28B 40;
BA_ "GenSigInvalidValue" SG_ 651 BCM_TurnIndicatorLeft "3";
BA_ "GenSigCycleTime" SG_ 651 BCM_TurnIndicatorLeft 40;
BA_ "GenSigInvalidValue" SG_ 651 BCM_TurnIndicatorRight "3";
BA_ "GenSigCycleTime" SG_ 651 BCM_TurnIndicatorRight 40;
BA_ "GenSigInvalidValue" SG_ 651 PEPS_ShiftForbidRq "0";
BA_ "GenSigCycleTime" SG_ 651 PEPS_ShiftForbidRq 40;
BA_ "GenSigStartValue" SG_ 651 BCM_KeyAlarmStatus 2;
BA_ "GenSigCycleTime" SG_ 651 BCM_KeyAlarmStatus 40;
BA_ "GenSigInvalidValue" SG_ 651 PEPS_RemoteStartReq "3";
BA_ "GenSigCycleTime" SG_ 651 PEPS_RemoteStartReq 40;
BA_ "GenSigInvalidValue" SG_ 651 BCM_emergencylightstatus "3";
BA_ "GenSigCycleTime" SG_ 651 BCM_emergencylightstatus 40;
BA_ "GenSigCycleTime" SG_ 651 BCM_PowerStatusFeedback 40;
BA_ "GenSigInvalidValue" SG_ 651 BCM_RearDefrosterstatus "3";
BA_ "GenSigCycleTime" SG_ 651 BCM_RearDefrosterstatus 40;
BA_ "GenSigCycleTime" SG_ 651 BCM_DriverDoorStatus 40;
BA_ "GenSigCycleTime" SG_ 651 BCM_HoodStatus 40;
BA_ "GenSigInvalidValue" SG_ 651 PEPS_StartControlsignal "3";
BA_ "GenSigCycleTime" SG_ 651 PEPS_StartControlsignal 40;
BA_ "GenSigInvalidValue" SG_ 651 BCM_LowBeamStatus "3";
BA_ "GenSigCycleTime" SG_ 651 BCM_LowBeamStatus 40;
BA_ "GenSigInvalidValue" SG_ 651 BCM_HighBeamStatus "3";
BA_ "GenSigCycleTime" SG_ 651 BCM_HighBeamStatus 40;
BA_ "GenSigInvalidValue" SG_ 651 BCM_TurnLightSwitchSts "3";
BA_ "GenSigCycleTime" SG_ 651 BCM_TurnLightSwitchSts 40;
BA_ "GenSigCycleTime" SG_ 651 BCM_MirrorAdjustSts 40;
BA_ "GenSigInvalidValue" SG_ 721 BCM_BrakeLampStatus "3";
BA_ "GenSigCycleTime" SG_ 721 BCM_BrakeLampStatus 40;
BA_ "GenSigCycleTime" SG_ 721 BCM_TrunkDoorStatus 40;
BA_ "GenSigCycleTime" SG_ 721 BCM_RightRearDoorStatus 40;
BA_ "GenSigCycleTime" SG_ 721 BCM_PassengerDoorStatus 40;
BA_ "GenSigInvalidValue" SG_ 721 PEPS_LuggageUnlockSignal "0";
BA_ "GenSigCycleTime" SG_ 721 PEPS_LuggageUnlockSignal 40;
BA_ "GenSigCycleTime" SG_ 721 BCM_ReversePosition 40;
BA_ "GenSigCycleTime" SG_ 734 IP_CRCCheck_2DE 50;
BA_ "GenSigCycleTime" SG_ 734 IP_RollingCounter_2DE 50;
BA_ "GenSigInvalidValue" SG_ 734 IP_DriverLCDALEDSts "0";
BA_ "GenSigCycleTime" SG_ 734 IP_DriverLCDALEDSts 50;
BA_ "GenSigInvalidValue" SG_ 734 IP_PassengerLCDALEDSts "0";
BA_ "GenSigCycleTime" SG_ 734 IP_PassengerLCDALEDSts 50;
BA_ "GenSigInvalidValue" SG_ 734 IP_DISFail "0";
BA_ "GenSigCycleTime" SG_ 734 IP_DISFail 50;
BA_ "GenSigInvalidValue" SG_ 734 IP_QDashACCFail "0";
BA_ "GenSigCycleTime" SG_ 734 IP_QDashACCFail 50;
BA_ "GenSigCycleTime" SG_ 742 EMS_WarmUpCycle 50;
BA_ "GenSigInvalidValue" SG_ 742 EMS_SecIgnitionCyclesCounter "1";
BA_ "GenSigCycleTime" SG_ 742 EMS_SecIgnitionCyclesCounter 50;
BA_ "GenSigCycleTime" SG_ 742 EMS_RollingCounter_2E6 50;
BA_ "GenSigCycleTime" SG_ 742 EMS_LoBattU 50;
BA_ "GenSigCycleTime" SG_ 742 EMS_LoBattErr 50;
BA_ "GenSigInvalidValue" SG_ 742 EMS_IgnitionCyclesCounterValid "1";
BA_ "GenSigCycleTime" SG_ 742 EMS_IgnitionCyclesCounterValid 50;
BA_ "GenSigInvalidValue" SG_ 742 EMS_GeneralDenoStatusValid "1";
BA_ "GenSigCycleTime" SG_ 742 EMS_GeneralDenoStatusValid 50;
BA_ "GenSigInvalidValue" SG_ 742 EMS_GeneralDenominatorStatus "1";
BA_ "GenSigCycleTime" SG_ 742 EMS_GeneralDenominatorStatus 50;
BA_ "GenSigInvalidValue" SG_ 742 EMS_FirstIgnitionCycleCounter "1";
BA_ "GenSigCycleTime" SG_ 742 EMS_FirstIgnitionCycleCounter 50;
BA_ "GenSigCycleTime" SG_ 742 EMS_EngTCoolt 50;
BA_ "GenSigCycleTime" SG_ 742 EMS_EngineIntakeAirTemp 50;
BA_ "GenSigCycleTime" SG_ 742 EMS_DrivingCycle 50;
BA_ "GenSigCycleTime" SG_ 742 EMS_CRCCheck_2E6 50;
BA_ "GenSigCycleTime" SG_ 742 EMS_CooltTErr 50;
BA_ "GenSigCycleTime" SG_ 742 EMS_Coolreq 50;
BA_ "GenSigCycleTime" SG_ 742 EMS_CatalystWarmUp 50;
BA_ "GenSigInvalidValue" SG_ 742 EMS_AltitudeFactorValid "1";
BA_ "GenSigCycleTime" SG_ 742 EMS_AltitudeFactorValid 50;
BA_ "GenSigInvalidValue" SG_ 742 EMS_AltitudeFactor "255";
BA_ "GenSigStartValue" SG_ 742 EMS_AltitudeFactor 63;
BA_ "GenSigCycleTime" SG_ 742 EMS_AltitudeFactor 50;
BA_ "GenSigInvalidValue" SG_ 794 ADC_EcasModeReq "0";
BA_ "GenSigCycleTime" SG_ 794 ADC_EcasModeReq 100;
BA_ "GenSigCycleTime" SG_ 794 ACC_AEBTargetLatRelSpeed 100;
BA_ "GenSigInvalidValue" SG_ 794 ACC_LngTakeOverReqReason "0";
BA_ "GenSigCycleTime" SG_ 794 ACC_LngTakeOverReqReason 100;
BA_ "GenSigCycleTime" SG_ 794 ACC_ELKAlert 100;
BA_ "GenSigCycleTime" SG_ 794 ACC_CRCCheck_367 100;
BA_ "GenSigCycleTime" SG_ 794 ACC_RollingCounter_367 100;
BA_ "GenSigCycleTime" SG_ 794 ACC_LatPathHeadingAngle 100;
BA_ "GenSigCycleTime" SG_ 794 ACC_ELKEnableStatus 100;
BA_ "GenSigCycleTime" SG_ 794 ACC_ELKInterventionMode 100;
BA_ "GenSigInvalidValue" SG_ 794 ACC_ELKMode "3";
BA_ "GenSigCycleTime" SG_ 794 ACC_ELKMode 100;
BA_ "GenSigCycleTime" SG_ 794 ACC_CRCCheck_30D 100;
BA_ "GenSigCycleTime" SG_ 794 ACC_RollingCounter_30D 100;
BA_ "GenSigCycleTime" SG_ 794 ACC_RRLaneDetection 100;
BA_ "GenSigCycleTime" SG_ 794 ACC_LLLaneDetection 100;
BA_ "GenSigCycleTime" SG_ 794 ACC_HighBeamControl 100;
BA_ "GenSigCycleTime" SG_ 794 ACC_TargetBasedLateralControl 100;
BA_ "GenSigCycleTime" SG_ 794 ACC_IACCHWATextInfoForDriver 100;
BA_ "GenSigCycleTime" SG_ 794 ACC_EmergencyLightingRequest 100;
BA_ "GenSigInvalidValue" SG_ 794 ACC_DriverHandsOffStatus "3";
BA_ "GenSigCycleTime" SG_ 794 ACC_DriverHandsOffStatus 100;
BA_ "GenSigInvalidValue" SG_ 794 ACC_IACCHWAMode "7";
BA_ "GenSigCycleTime" SG_ 794 ACC_IACCHWAMode 100;
BA_ "GenSigCycleTime" SG_ 794 ACC_CRCCheck_30A 100;
BA_ "GenSigCycleTime" SG_ 794 ACC_RollingCounter_30A 100;
BA_ "GenSigCycleTime" SG_ 794 ACC_LaneChangeStatus 100;
BA_ "GenSigStartValue" SG_ 794 ACC_RoadCurvatureFar 60;
BA_ "GenSigCycleTime" SG_ 794 ACC_RoadCurvatureFar 100;
BA_ "GenSigStartValue" SG_ 794 ACC_RoadCurvatureNear 60;
BA_ "GenSigCycleTime" SG_ 794 ACC_RoadCurvatureNear 100;
BA_ "GenSigStartValue" SG_ 794 ACC_RoadCurvature 60;
BA_ "GenSigCycleTime" SG_ 794 ACC_RoadCurvature 100;
BA_ "GenSigCycleTime" SG_ 794 ACC_IACCHWAEnable 100;
BA_ "GenSigStartValue" SG_ 794 ACC_RLaneMarkerType 7;
BA_ "GenSigCycleTime" SG_ 794 ACC_RLaneMarkerType 100;
BA_ "GenSigStartValue" SG_ 794 ACC_LLaneMarkerType 7;
BA_ "GenSigCycleTime" SG_ 794 ACC_LLaneMarkerType 100;
BA_ "GenSigCycleTime" SG_ 794 ACC_HostLaneRightStatus 100;
BA_ "GenSigCycleTime" SG_ 794 ACC_HostLaneLeftStatus 100;
BA_ "GenSigStartValue" SG_ 794 ACC_LASWarningModeSelectionSts 2;
BA_ "GenSigCycleTime" SG_ 794 ACC_LASWarningModeSelectionSts 100;
BA_ "GenSigStartValue" SG_ 794 ACC_LASModeSelectionStatus 1;
BA_ "GenSigCycleTime" SG_ 794 ACC_LASModeSelectionStatus 100;
BA_ "GenSigCycleTime" SG_ 794 ACC_CRCCheck_36D 100;
BA_ "GenSigCycleTime" SG_ 794 ACC_RollingCounter_36D 100;
BA_ "GenSigInvalidValue" SG_ 794 ACC_FRadarFailureStatus "3";
BA_ "GenSigCycleTime" SG_ 794 ACC_FRadarFailureStatus 100;
BA_ "GenSigStartValue" SG_ 794 ACC_AEBTargetLatRange 500;
BA_ "GenSigCycleTime" SG_ 794 ACC_AEBTargetLatRange 100;
BA_ "GenSigStartValue" SG_ 794 ACC_AEBTargetRelSpeed 250;
BA_ "GenSigCycleTime" SG_ 794 ACC_AEBTargetRelSpeed 100;
BA_ "GenSigStartValue" SG_ 794 ACC_AEBTargetLngRange 500;
BA_ "GenSigCycleTime" SG_ 794 ACC_AEBTargetLngRange 100;
BA_ "GenSigCycleTime" SG_ 794 ACC_Voiceinfo 100;
BA_ "GenSigCycleTime" SG_ 794 ACC_AEBTargetmode 100;
BA_ "GenSigCycleTime" SG_ 794 ACC_AEBTextInfo 100;
BA_ "GenSigInvalidValue" SG_ 794 ACC_AEBStatus "3";
BA_ "GenSigCycleTime" SG_ 794 ACC_AEBStatus 100;
BA_ "GenSigCycleTime" SG_ 853 EMS_CRCCheck_355 100;
BA_ "GenSigCycleTime" SG_ 853 EMS_RollingCounter_355 100;
BA_ "GenSigInvalidValue" SG_ 853 EMS_CruiseDistance "0";
BA_ "GenSigCycleTime" SG_ 853 EMS_CruiseDistance 100;
BA_ "GenSigInvalidValue" SG_ 853 EMS_CruiseSwitchSET "0";
BA_ "GenSigCycleTime" SG_ 853 EMS_CruiseSwitchSET 100;
BA_ "GenSigInvalidValue" SG_ 853 EMS_CruiseSwitchCANCEL "0";
BA_ "GenSigCycleTime" SG_ 853 EMS_CruiseSwitchCANCEL 100;
BA_ "GenSigInvalidValue" SG_ 853 EMS_CruiseSwitchResume "0";
BA_ "GenSigCycleTime" SG_ 853 EMS_CruiseSwitchResume 100;
BA_ "GenSigInvalidValue" SG_ 853 EMS_CruiseSwitchOnOff "0";
BA_ "GenSigCycleTime" SG_ 853 EMS_CruiseSwitchOnOff 100;
BA_ "GenSigCycleTime" SG_ 943 HU_CRCCheck_3AF 100;
BA_ "GenSigCycleTime" SG_ 943 HU_RollingCounter_3AF 100;
BA_ "GenSigCycleTime" SG_ 943 HU_Novice_Enable 100;
BA_ "GenSigInvalidValue" SG_ 943 HU_ADAS_Posn_Offset "8191";
BA_ "GenSigCycleTime" SG_ 943 HU_ADAS_Posn_Offset 100;
BA_ "GenSigInvalidValue" SG_ 943 HU_ADAS_Posn_Pathldx "0";
BA_ "GenSigCycleTime" SG_ 943 HU_ADAS_Posn_Pathldx 100;
BA_ "GenSigCycleTime" SG_ 943 HU_EHPHeartFlag 100;
BA_ "GenSigCycleTime" SG_ 943 HU_EHRHeartFlag 100;
BA_ "GenSigInvalidValue" SG_ 943 HU_LaneType_ID6 "15";
BA_ "GenSigCycleTime" SG_ 943 HU_LaneType_ID6 100;
BA_ "GenSigInvalidValue" SG_ 943 HU_LaneType_ID5 "15";
BA_ "GenSigCycleTime" SG_ 943 HU_LaneType_ID5 100;
BA_ "GenSigInvalidValue" SG_ 943 HU_LaneType_ID4 "15";
BA_ "GenSigCycleTime" SG_ 943 HU_LaneType_ID4 100;
BA_ "GenSigInvalidValue" SG_ 943 HU_LaneType_ID3 "15";
BA_ "GenSigCycleTime" SG_ 943 HU_LaneType_ID3 100;
BA_ "GenSigInvalidValue" SG_ 943 HU_LaneType_ID2 "15";
BA_ "GenSigCycleTime" SG_ 943 HU_LaneType_ID2 100;
BA_ "GenSigInvalidValue" SG_ 943 HU_LaneType_ID1 "15";
BA_ "GenSigCycleTime" SG_ 943 HU_LaneType_ID1 100;
BA_ "GenSigInvalidValue" SG_ 943 HU_ServiceRoadDis "63";
BA_ "GenSigStartValue" SG_ 943 HU_ServiceRoadDis 63;
BA_ "GenSigCycleTime" SG_ 943 HU_ServiceRoadDis 100;
BA_ "GenSigInvalidValue" SG_ 943 HU_ServiceRoad "3";
BA_ "GenSigCycleTime" SG_ 943 HU_ServiceRoad 100;
BA_ "GenSigInvalidValue" SG_ 943 HU_WeatherType "63";
BA_ "GenSigStartValue" SG_ 943 HU_WeatherType 63;
BA_ "GenSigCycleTime" SG_ 943 HU_WeatherType 100;
BA_ "GenSigInvalidValue" SG_ 943 HU_BridgeDis "63";
BA_ "GenSigStartValue" SG_ 943 HU_BridgeDis 63;
BA_ "GenSigCycleTime" SG_ 943 HU_BridgeDis 100;
BA_ "GenSigInvalidValue" SG_ 943 HU_BridgeInfo "3";
BA_ "GenSigCycleTime" SG_ 943 HU_BridgeInfo 100;
BA_ "GenSigInvalidValue" SG_ 943 HU_AccidentProneDistance "63";
BA_ "GenSigStartValue" SG_ 943 HU_AccidentProneDistance 63;
BA_ "GenSigCycleTime" SG_ 943 HU_AccidentProneDistance 100;
BA_ "GenSigInvalidValue" SG_ 943 HU_AccidentProne "3";
BA_ "GenSigCycleTime" SG_ 943 HU_AccidentProne 100;
BA_ "GenSigInvalidValue" SG_ 943 HU_IntervalVelocityDis "63";
BA_ "GenSigStartValue" SG_ 943 HU_IntervalVelocityDis 63;
BA_ "GenSigCycleTime" SG_ 943 HU_IntervalVelocityDis 100;
BA_ "GenSigInvalidValue" SG_ 943 HU_IntervalVelocityInfo "0";
BA_ "GenSigCycleTime" SG_ 943 HU_IntervalVelocityInfo 100;
BA_ "GenSigInvalidValue" SG_ 943 HU_SlopeGradient_100m "1023";
BA_ "GenSigStartValue" SG_ 943 HU_SlopeGradient_100m 1023;
BA_ "GenSigCycleTime" SG_ 943 HU_SlopeGradient_100m 100;
BA_ "GenSigInvalidValue" SG_ 943 HU_SlopeGradient_50m "1023";
BA_ "GenSigStartValue" SG_ 943 HU_SlopeGradient_50m 1023;
BA_ "GenSigCycleTime" SG_ 943 HU_SlopeGradient_50m 100;
BA_ "GenSigInvalidValue" SG_ 943 HU_SlopeGradient_40m "1023";
BA_ "GenSigStartValue" SG_ 943 HU_SlopeGradient_40m 1023;
BA_ "GenSigCycleTime" SG_ 943 HU_SlopeGradient_40m 100;
BA_ "GenSigInvalidValue" SG_ 943 HU_SlopeGradient_30m "1023";
BA_ "GenSigStartValue" SG_ 943 HU_SlopeGradient_30m 1023;
BA_ "GenSigCycleTime" SG_ 943 HU_SlopeGradient_30m 100;
BA_ "GenSigInvalidValue" SG_ 943 HU_SlopeGradient_20m "1023";
BA_ "GenSigStartValue" SG_ 943 HU_SlopeGradient_20m 1023;
BA_ "GenSigCycleTime" SG_ 943 HU_SlopeGradient_20m 100;
BA_ "GenSigInvalidValue" SG_ 943 HU_SlopeGradient_10m "1023";
BA_ "GenSigStartValue" SG_ 943 HU_SlopeGradient_10m 1023;
BA_ "GenSigCycleTime" SG_ 943 HU_SlopeGradient_10m 100;
BA_ "GenSigCycleTime" SG_ 943 HU_CRCCheck_3AF_3 100;
BA_ "GenSigCycleTime" SG_ 943 HU_RollingCounter_3AF_3 100;
BA_ "GenSigInvalidValue" SG_ 943 HU_RampDistance "1023";
BA_ "GenSigStartValue" SG_ 943 HU_RampDistance 1023;
BA_ "GenSigCycleTime" SG_ 943 HU_RampDistance 100;
BA_ "GenSigInvalidValue" SG_ 943 HU_NavSpeedLimitType "0";
BA_ "GenSigCycleTime" SG_ 943 HU_NavSpeedLimitType 100;
BA_ "GenSigInvalidValue" SG_ 943 HU_CurveDistance "63";
BA_ "GenSigStartValue" SG_ 943 HU_CurveDistance 63;
BA_ "GenSigCycleTime" SG_ 943 HU_CurveDistance 100;
BA_ "GenSigInvalidValue" SG_ 943 HU_EnterCurveInfo "0";
BA_ "GenSigCycleTime" SG_ 943 HU_EnterCurveInfo 100;
BA_ "GenSigInvalidValue" SG_ 943 HU_NavCurrentRoadType "0";
BA_ "GenSigCycleTime" SG_ 943 HU_NavCurrentRoadType 100;
BA_ "GenSigInvalidValue" SG_ 943 HU_EnterRampInfo "0";
BA_ "GenSigCycleTime" SG_ 943 HU_EnterRampInfo 100;
BA_ "GenSigInvalidValue" SG_ 943 HU_RampInfo "0";
BA_ "GenSigCycleTime" SG_ 943 HU_RampInfo 100;
BA_ "GenSigInvalidValue" SG_ 943 HU_NavCountryCode "0";
BA_ "GenSigCycleTime" SG_ 943 HU_NavCountryCode 100;
BA_ "GenSigInvalidValue" SG_ 943 HU_NavStatus "1";
BA_ "GenSigCycleTime" SG_ 943 HU_NavStatus 100;
BA_ "GenSigInvalidValue" SG_ 943 HU_NavSpeedLimitUnits "0";
BA_ "GenSigCycleTime" SG_ 943 HU_NavSpeedLimitUnits 100;
BA_ "GenSigInvalidValue" SG_ 943 HU_NavSpeedLimitStatus "1";
BA_ "GenSigCycleTime" SG_ 943 HU_NavSpeedLimitStatus 100;
BA_ "GenSigInvalidValue" SG_ 943 HU_NavSpeedLimit "255";
BA_ "GenSigStartValue" SG_ 943 HU_NavSpeedLimit 254;
BA_ "GenSigCycleTime" SG_ 943 HU_NavSpeedLimit 100;
BA_ "GenSigCycleTime" SG_ 943 HU_CRCCheck_3BB 100;
BA_ "GenSigCycleTime" SG_ 943 HU_RollingCounter_3BB 100;
BA_ "GenSigInvalidValue" SG_ 943 HU_SpeedLimitDistance "63";
BA_ "GenSigStartValue" SG_ 943 HU_SpeedLimitDistance 63;
BA_ "GenSigCycleTime" SG_ 943 HU_SpeedLimitDistance 100;
BA_ "GenSigInvalidValue" SG_ 947 BCM_DoorHandle_TimeDifference "255";
BA_ "GenSigStartValue" SG_ 947 BCM_DoorHandle_TimeDifference 255;
BA_ "GenSigCycleTime" SG_ 947 BCM_DoorHandle_TimeDifference 100;
BA_ "GenSigCycleTime" SG_ 947 BCM_RightRearDoorHandleStatus 100;
BA_ "GenSigCycleTime" SG_ 947 BCM_PassengeDoorHandleStatus 100;
BA_ "GenSigInvalidValue" SG_ 947 LCM_ReverseLightSts "3";
BA_ "GenSigCycleTime" SG_ 947 LCM_ReverseLightSts 100;
BA_ "GenSigCycleTime" SG_ 947 BCM_ReverseLampError 100;
BA_ "GenSigCycleTime" SG_ 947 BCM_CHMLampError 100;
BA_ "GenSigCycleTime" SG_ 947 BCM_BrakeLampError 100;
BA_ "GenSigCycleTime" SG_ 947 BCM_RightRearFoglampError 100;
BA_ "GenSigCycleTime" SG_ 947 BCM_LeftRearFoglampError 100;
BA_ "GenSigCycleTime" SG_ 947 BCM_RearPositionLampError 100;
BA_ "GenSigInvalidValue" SG_ 947 BCM_RearFoglampStatus "3";
BA_ "GenSigCycleTime" SG_ 947 BCM_RearFoglampStatus 100;
BA_ "GenSigCycleTime" SG_ 957 HU_ADSRoadVoiceEnable 100;
BA_ "GenSigCycleTime" SG_ 957 HU_ADSLaneChangeVoiceEnable 100;
BA_ "GenSigCycleTime" SG_ 957 HU_ADSSafeVoiceEnable 100;
BA_ "GenSigInvalidValue" SG_ 957 HU_AVMMapDisplayFeedback "3";
BA_ "GenSigStartValue" SG_ 957 HU_AVMMapDisplayFeedback 3;
BA_ "GenSigCycleTime" SG_ 957 HU_AVMMapDisplayFeedback 100;
BA_ "GenSigCycleTime" SG_ 957 HU_APAThemeChange 100;
BA_ "GenSigCycleTime" SG_ 957 HU_RearFoglampSet 100;
BA_ "GenSigCycleTime" SG_ 957 HU_AutoHeadLiSet 100;
BA_ "GenSigCycleTime" SG_ 957 HU_TransparentValueCarRequest 100;
BA_ "GenSigInvalidValue" SG_ 957 HU_RADSSwitch "0";
BA_ "GenSigCycleTime" SG_ 957 HU_RADSSwitch 100;
BA_ "GenSigCycleTime" SG_ 957 HU_CRCCheck_394 100;
BA_ "GenSigCycleTime" SG_ 957 HU_RollingCounter_394 100;
BA_ "GenSigInvalidValue" SG_ 957 HU_CurrentMedia_Info "0";
BA_ "GenSigCycleTime" SG_ 957 HU_CurrentMedia_Info 100;
BA_ "GenSigCycleTime" SG_ 957 HU_LaneChangeReq 100;
BA_ "GenSigCycleTime" SG_ 957 HU_HWAEnable 100;
BA_ "GenSigInvalidValue" SG_ 957 HU_Compass "511";
BA_ "GenSigCycleTime" SG_ 957 HU_Compass 100;
BA_ "GenSigCycleTime" SG_ 957 HU_APARemoteDispSts 100;
BA_ "GenSigCycleTime" SG_ 957 HU_RemoteDispSts 100;
BA_ "GenSigCycleTime" SG_ 957 HU_IRLCEnable 100;
BA_ "GenSigCycleTime" SG_ 957 HU_ADSRescueConfirm 100;
BA_ "GenSigInvalidValue" SG_ 957 HU_CSLAEnable "3";
BA_ "GenSigStartValue" SG_ 957 HU_CSLAEnable 3;
BA_ "GenSigCycleTime" SG_ 957 HU_CSLAEnable 100;
BA_ "GenSigInvalidValue" SG_ 957 HU_UDLCEnable "0";
BA_ "GenSigCycleTime" SG_ 957 HU_UDLCEnable 100;
BA_ "GenSigInvalidValue" SG_ 957 HU_ESSEnable "0";
BA_ "GenSigCycleTime" SG_ 957 HU_ESSEnable 100;
BA_ "GenSigInvalidValue" SG_ 957 HU_ELKEnable "0";
BA_ "GenSigCycleTime" SG_ 957 HU_ELKEnable 100;
BA_ "GenSigInvalidValue" SG_ 957 HU_TLAEnable "0";
BA_ "GenSigCycleTime" SG_ 957 HU_TLAEnable 100;
BA_ "GenSigInvalidValue" SG_ 957 HU_EXT_RemoteDetectUploadStatus "0";
BA_ "GenSigCycleTime" SG_ 957 HU_EXT_RemoteDetectUploadStatus 100;
BA_ "GenSigInvalidValue" SG_ 957 HU_PACModeSelect "0";
BA_ "GenSigCycleTime" SG_ 957 HU_PACModeSelect 100;
BA_ "GenSigCycleTime" SG_ 957 HU_APAActive 100;
BA_ "GenSigCycleTime" SG_ 957 HU_CrossParkingModeSet 100;
BA_ "GenSigCycleTime" SG_ 957 HU_ASPSwitch 100;
BA_ "GenSigCycleTime" SG_ 957 HU_ASPRemindEnable 100;
BA_ "GenSigInvalidValue" SG_ 957 HU_ASPModeSelect "7";
BA_ "GenSigCycleTime" SG_ 957 HU_ASPModeSelect 100;
BA_ "GenSigCycleTime" SG_ 957 HU_LAEBEnable 100;
BA_ "GenSigInvalidValue" SG_ 957 HU_APAModeSelect "3";
BA_ "GenSigStartValue" SG_ 957 HU_APAModeSelect 7;
BA_ "GenSigCycleTime" SG_ 957 HU_APAModeSelect 100;
BA_ "GenSigCycleTime" SG_ 957 HU_DVRUpdateReq 100;
BA_ "GenSigCycleTime" SG_ 957 HU_LicenseNumberCheckSum 100;
BA_ "GenSigCycleTime" SG_ 957 HU_LicenseNumber 100;
BA_ "GenSigCycleTime" SG_ 957 HU_LicenseNumberSet 100;
BA_ "GenSigCycleTime" SG_ 957 HU_WheelHubSet 100;
BA_ "GenSigCycleTime" SG_ 957 HU_BodyColourSet 100;
BA_ "GenSigCycleTime" SG_ 957 HU_AVMDVRReplayModeReq 100;
BA_ "GenSigCycleTime" SG_ 957 HU_HUDPosAdjustDec 100;
BA_ "GenSigCycleTime" SG_ 957 HU_HUDPosAdjustInc 100;
BA_ "GenSigCycleTime" SG_ 957 HU_VC_VR 100;
BA_ "GenSigInvalidValue" SG_ 957 HU_Seeoffanimation "0";
BA_ "GenSigCycleTime" SG_ 957 HU_Seeoffanimation 100;
BA_ "GenSigCycleTime" SG_ 957 HU_LanguageSync 100;
BA_ "GenSigCycleTime" SG_ 957 HU_DVREditSelected 100;
BA_ "GenSigInvalidValue" SG_ 957 HU_NaviIconNumber_2 "0";
BA_ "GenSigCycleTime" SG_ 957 HU_NaviIconNumber_2 100;
BA_ "GenSigInvalidValue" SG_ 957 HU_SurrondingMonitorDone "0";
BA_ "GenSigCycleTime" SG_ 957 HU_SurrondingMonitorDone 100;
BA_ "GenSigInvalidValue" SG_ 957 HU_BcallReq "0";
BA_ "GenSigCycleTime" SG_ 957 HU_BcallReq 100;
BA_ "GenSigInvalidValue" SG_ 957 HU_NaviIconNumber "LastValue";
BA_ "GenSigCycleTime" SG_ 957 HU_NaviIconNumber 100;
BA_ "GenSigInvalidValue" SG_ 957 HU_NaviDistance "131071";
BA_ "GenSigCycleTime" SG_ 957 HU_NaviDistance 100;
BA_ "GenSigInvalidValue" SG_ 957 HU_DVRErrorRecord "3";
BA_ "GenSigCycleTime" SG_ 957 HU_DVRErrorRecord 100;
BA_ "GenSigInvalidValue" SG_ 957 HU_DVRSystemImprint "3";
BA_ "GenSigCycleTime" SG_ 957 HU_DVRSystemImprint 100;
BA_ "GenSigInvalidValue" SG_ 957 HU_SDCapacity "3";
BA_ "GenSigCycleTime" SG_ 957 HU_SDCapacity 100;
BA_ "GenSigInvalidValue" SG_ 957 HU_TUIDReq "3";
BA_ "GenSigCycleTime" SG_ 957 HU_TUIDReq 100;
BA_ "GenSigInvalidValue" SG_ 957 HU_RegisterStatus "3";
BA_ "GenSigCycleTime" SG_ 957 HU_RegisterStatus 100;
BA_ "GenSigInvalidValue" SG_ 957 HU_AutoViewSet "LastValue";
BA_ "GenSigStartValue" SG_ 957 HU_AutoViewSet 1;
BA_ "GenSigCycleTime" SG_ 957 HU_AutoViewSet 100;
BA_ "GenSigInvalidValue" SG_ 957 HU_RealTimeReq "3";
BA_ "GenSigCycleTime" SG_ 957 HU_RealTimeReq 100;
BA_ "GenSigInvalidValue" SG_ 957 HU_RebroadcastReq "3";
BA_ "GenSigCycleTime" SG_ 957 HU_RebroadcastReq 100;
BA_ "GenSigCycleTime" SG_ 957 HU_360AVMdetectionRequest 100;
BA_ "GenSigInvalidValue" SG_ 957 HU_3DAVMReq "3";
BA_ "GenSigStartValue" SG_ 957 HU_3DAVMReq 3;
BA_ "GenSigCycleTime" SG_ 957 HU_3DAVMReq 100;
BA_ "GenSigInvalidValue" SG_ 957 HU_VisionAngleReq "3";
BA_ "GenSigCycleTime" SG_ 957 HU_VisionAngleReq 100;
BA_ "GenSigCycleTime" SG_ 964 HU_CRCCheck_3C4 100;
BA_ "GenSigCycleTime" SG_ 964 HU_RollingCounter_3C4 100;
BA_ "GenSigCycleTime" SG_ 964 HU_CRCCheck_3C7 100;
BA_ "GenSigCycleTime" SG_ 964 HU_RollingCounter_3C7 100;
BA_ "GenSigCycleTime" SG_ 964 HU_CRCCheck_3C6 100;
BA_ "GenSigCycleTime" SG_ 964 HU_RollingCounter_3C6 100;
BA_ "GenSigCycleTime" SG_ 964 HU_CRCCheck_3C4_2 100;
BA_ "GenSigCycleTime" SG_ 964 HU_RollingCounter_3C4_2 100;
BA_ "GenSigCycleTime" SG_ 964 HU_CRCCheck_3C2 100;
BA_ "GenSigCycleTime" SG_ 964 HU_RollingCounter_3C2 100;
BA_ "GenSigInvalidValue" SG_ 964 HU_MapMatchStatus "3";
BA_ "GenSigCycleTime" SG_ 964 HU_MapMatchStatus 100;
BA_ "GenSigInvalidValue" SG_ 964 HU_MapDataUpdateStatus "7";
BA_ "GenSigCycleTime" SG_ 964 HU_MapDataUpdateStatus 100;
BA_ "GenSigInvalidValue" SG_ 964 HU_RoadCurvature_600m "1023";
BA_ "GenSigStartValue" SG_ 964 HU_RoadCurvature_600m 511;
BA_ "GenSigCycleTime" SG_ 964 HU_RoadCurvature_600m 100;
BA_ "GenSigInvalidValue" SG_ 964 HU_RoadCurvature_400m "1023";
BA_ "GenSigStartValue" SG_ 964 HU_RoadCurvature_400m 511;
BA_ "GenSigCycleTime" SG_ 964 HU_RoadCurvature_400m 100;
BA_ "GenSigInvalidValue" SG_ 964 HU_RoadCurvature_300m "1023";
BA_ "GenSigStartValue" SG_ 964 HU_RoadCurvature_300m 511;
BA_ "GenSigCycleTime" SG_ 964 HU_RoadCurvature_300m 100;
BA_ "GenSigInvalidValue" SG_ 964 HU_RoadCurvature_100m "1023";
BA_ "GenSigStartValue" SG_ 964 HU_RoadCurvature_100m 511;
BA_ "GenSigCycleTime" SG_ 964 HU_RoadCurvature_100m 100;
BA_ "GenSigInvalidValue" SG_ 964 HU_RoadCurvature_90m "1023";
BA_ "GenSigStartValue" SG_ 964 HU_RoadCurvature_90m 511;
BA_ "GenSigCycleTime" SG_ 964 HU_RoadCurvature_90m 100;
BA_ "GenSigInvalidValue" SG_ 964 HU_RoadCurvature_80m "1023";
BA_ "GenSigStartValue" SG_ 964 HU_RoadCurvature_80m 511;
BA_ "GenSigCycleTime" SG_ 964 HU_RoadCurvature_80m 100;
BA_ "GenSigInvalidValue" SG_ 964 HU_RoadCurvature_70m "1023";
BA_ "GenSigStartValue" SG_ 964 HU_RoadCurvature_70m 511;
BA_ "GenSigCycleTime" SG_ 964 HU_RoadCurvature_70m 100;
BA_ "GenSigInvalidValue" SG_ 964 HU_RoadCurvature_60m "1023";
BA_ "GenSigStartValue" SG_ 964 HU_RoadCurvature_60m 511;
BA_ "GenSigCycleTime" SG_ 964 HU_RoadCurvature_60m 100;
BA_ "GenSigInvalidValue" SG_ 964 HU_RoadCurvature_50m "1023";
BA_ "GenSigStartValue" SG_ 964 HU_RoadCurvature_50m 511;
BA_ "GenSigCycleTime" SG_ 964 HU_RoadCurvature_50m 100;
BA_ "GenSigInvalidValue" SG_ 964 HU_RoadCurvature_40m "1023";
BA_ "GenSigStartValue" SG_ 964 HU_RoadCurvature_40m 511;
BA_ "GenSigCycleTime" SG_ 964 HU_RoadCurvature_40m 100;
BA_ "GenSigInvalidValue" SG_ 964 HU_RoadCurvature_30m "1023";
BA_ "GenSigStartValue" SG_ 964 HU_RoadCurvature_30m 511;
BA_ "GenSigCycleTime" SG_ 964 HU_RoadCurvature_30m 100;
BA_ "GenSigInvalidValue" SG_ 964 HU_RoadCurvature_20m "1023";
BA_ "GenSigStartValue" SG_ 964 HU_RoadCurvature_20m 511;
BA_ "GenSigCycleTime" SG_ 964 HU_RoadCurvature_20m 100;
BA_ "GenSigInvalidValue" SG_ 964 HU_RoadCurvature_10m "1023";
BA_ "GenSigStartValue" SG_ 964 HU_RoadCurvature_10m 511;
BA_ "GenSigCycleTime" SG_ 964 HU_RoadCurvature_10m 100;
BA_ "GenSigInvalidValue" SG_ 964 HU_Road_TrafficFlow "7";
BA_ "GenSigCycleTime" SG_ 964 HU_Road_TrafficFlow 100;
BA_ "GenSigInvalidValue" SG_ 964 HU_Lane_Changtype "3";
BA_ "GenSigStartValue" SG_ 964 HU_Lane_Changtype 3;
BA_ "GenSigCycleTime" SG_ 964 HU_Lane_Changtype 100;
BA_ "GenSigInvalidValue" SG_ 964 HU_To_NumchangeOfLanes_Dist "63";
BA_ "GenSigStartValue" SG_ 964 HU_To_NumchangeOfLanes_Dist 63;
BA_ "GenSigCycleTime" SG_ 964 HU_To_NumchangeOfLanes_Dist 100;
BA_ "GenSigInvalidValue" SG_ 964 HU_TollDis "63";
BA_ "GenSigStartValue" SG_ 964 HU_TollDis 63;
BA_ "GenSigCycleTime" SG_ 964 HU_TollDis 100;
BA_ "GenSigInvalidValue" SG_ 964 HU_TollInfo "3";
BA_ "GenSigStartValue" SG_ 964 HU_TollInfo 3;
BA_ "GenSigCycleTime" SG_ 964 HU_TollInfo 100;
BA_ "GenSigInvalidValue" SG_ 964 HU_LaneCnt "0";
BA_ "GenSigCycleTime" SG_ 964 HU_LaneCnt 100;
BA_ "GenSigInvalidValue" SG_ 964 HU_ForwardRoadType "0";
BA_ "GenSigCycleTime" SG_ 964 HU_ForwardRoadType 100;
BA_ "GenSigInvalidValue" SG_ 964 HU_RampSide "0";
BA_ "GenSigCycleTime" SG_ 964 HU_RampSide 100;
BA_ "GenSigCycleTime" SG_ 964 HU_CRCCheck_3B8 100;
BA_ "GenSigCycleTime" SG_ 964 HU_RollingCounter_3B8 100;
BA_ "GenSigInvalidValue" SG_ 964 HU_NavGuiganceStatus "3";
BA_ "GenSigCycleTime" SG_ 964 HU_NavGuiganceStatus 100;
BA_ "GenSigInvalidValue" SG_ 964 HU_TunnelLength "63";
BA_ "GenSigStartValue" SG_ 964 HU_TunnelLength 63;
BA_ "GenSigCycleTime" SG_ 964 HU_TunnelLength 100;
BA_ "GenSigInvalidValue" SG_ 964 HU_RoadCurvatureFar "1023";
BA_ "GenSigStartValue" SG_ 964 HU_RoadCurvatureFar 511;
BA_ "GenSigCycleTime" SG_ 964 HU_RoadCurvatureFar 100;
BA_ "GenSigInvalidValue" SG_ 964 HU_TunnelDistance "63";
BA_ "GenSigStartValue" SG_ 964 HU_TunnelDistance 63;
BA_ "GenSigCycleTime" SG_ 964 HU_TunnelDistance 100;
BA_ "GenSigInvalidValue" SG_ 964 HU_RoadCurvature "1023";
BA_ "GenSigStartValue" SG_ 964 HU_RoadCurvature 511;
BA_ "GenSigCycleTime" SG_ 964 HU_RoadCurvature 100;
BA_ "GenSigInvalidValue" SG_ 964 HU_EnterTunnelInfo "0";
BA_ "GenSigCycleTime" SG_ 964 HU_EnterTunnelInfo 100;
BA_ "GenSigCycleTime" SG_ 1021 BCM_RearFoglampStatusFB 100;
BA_ "GenSigCycleTime" SG_ 1021 BCM_AutHeadLiSts 100;
BA_ "GenSigCycleTime" SG_ 1021 BCM_DrvModSwSts 100;
BA_ "GenSigInvalidValue" SG_ 1021 BCM_FrontWindshieldWarmStatus "0";
BA_ "GenSigCycleTime" SG_ 1021 BCM_FrontWindshieldWarmStatus 100;
BA_ "GenSigInvalidValue" SG_ 1021 BCM_SwitchDimmerlevel "31";
BA_ "GenSigCycleTime" SG_ 1021 BCM_SwitchDimmerlevel 100;
BA_ "GenSigCycleTime" SG_ 1021 BCM_EPSTorqSYNStatus 100;
BA_ "GenSigCycleTime" SG_ 1021 BCM_CRCCheck_3FD 100;
BA_ "GenSigCycleTime" SG_ 1021 BCM_RollingCounter_3FD 100;
BA_ "GenSigCycleTime" SG_ 1021 BCM_EPSTorqueMode 100;
BA_ "GenSigInvalidValue" SG_ 1021 BCM_DriveMode "15";
BA_ "GenSigCycleTime" SG_ 1021 BCM_DriveMode 100;
BA_ "GenSigInvalidValue" SG_ 1021 BCM_PowerManageLevel "7";
BA_ "GenSigCycleTime" SG_ 1021 BCM_PowerManageLevel 100;
BA_ "GenSigCycleTime" SG_ 1023 BCM_CRCCheck_3FF 100;
BA_ "GenSigCycleTime" SG_ 1023 BCM_RollingCounter_3FF 100;
BA_ "GenSigInvalidValue" SG_ 1023 BCM_FloorLampStatus "3";
BA_ "GenSigCycleTime" SG_ 1023 BCM_FloorLampStatus 100;
BA_ "GenSigCycleTime" SG_ 1023 BCM_TurnIndicatorRightError 100;
BA_ "GenSigCycleTime" SG_ 1023 BCM_TurnIndicatorLeftError 100;
BA_ "GenSigInvalidValue" SG_ 1023 BCM_PositionLampSwitchStatus "0";
BA_ "GenSigCycleTime" SG_ 1023 BCM_PositionLampSwitchStatus 100;
BA_ "GenSigInvalidValue" SG_ 1023 LCM_DRLSts "0";
BA_ "GenSigCycleTime" SG_ 1023 LCM_DRLSts 100;
BA_ "GenSigInvalidValue" SG_ 1023 BCM_FollowMeHomeLightSetStatus "0";
BA_ "GenSigCycleTime" SG_ 1023 BCM_FollowMeHomeLightSetStatus 100;
BA_ "GenSigCycleTime" SG_ 1023 BCM_RightDayLampError 100;
BA_ "GenSigCycleTime" SG_ 1023 BCM_LeftDayLampError 100;
BA_ "GenSigCycleTime" SG_ 1023 BCM_RightFrontFoglampError 100;
BA_ "GenSigCycleTime" SG_ 1023 BCM_LeftFrontFoglampError 100;
BA_ "GenSigCycleTime" SG_ 1023 BCM_RightLowBeamError 100;
BA_ "GenSigCycleTime" SG_ 1023 BCM_LeftLowBeamError 100;
BA_ "GenSigCycleTime" SG_ 1023 BCM_FrontPositionLampError 100;
BA_ "GenSigCycleTime" SG_ 1023 BCM_HighBeamLampError 100;
BA_ "GenSigInvalidValue" SG_ 1023 BCM_AutoHeadlightSts "0";
BA_ "GenSigCycleTime" SG_ 1023 BCM_AutoHeadlightSts 100;
BA_ "GenSigInvalidValue" SG_ 1023 BCM_FrontFoglampStatus "3";
BA_ "GenSigCycleTime" SG_ 1023 BCM_FrontFoglampStatus 100;
BA_ "GenSigCycleTime" SG_ 1023 BCM_FollowMeTurnon 100;
BA_ "GenSigInvalidValue" SG_ 1023 BCM_PositionLampStatus "3";
BA_ "GenSigCycleTime" SG_ 1023 BCM_PositionLampStatus 100;
BA_ "GenSigInvalidValue" SG_ 1023 PEPS_WelcomeLightStaus "0";
BA_ "GenSigStartValue" SG_ 1023 PEPS_WelcomeLightStaus 1;
BA_ "GenSigCycleTime" SG_ 1023 PEPS_WelcomeLightStaus 100;
BA_ "GenSigCycleTime" SG_ 1023 BCM_Musiclightfeedback 100;
BA_ "GenSigCycleTime" SG_ 1023 BCM_MusicPlayRequestSignal 100;
BA_ "GenSigCycleTime" SG_ 1023 BCM_MusicLightModeSelectSts 100;
BA_ "GenSigCycleTime" SG_ 1310 BCM_CRCCheck_51E 500;
BA_ "GenSigCycleTime" SG_ 1310 BCM_RollingCounter_51E 500;
BA_ "GenSigInvalidValue" SG_ 1310 TPMS_Commendatorypressure "0";
BA_ "GenSigCycleTime" SG_ 1310 TPMS_Commendatorypressure 500;
BA_ "GenSigInvalidValue" SG_ 1310 TPMS_AerateFlag "0";
BA_ "GenSigCycleTime" SG_ 1310 TPMS_AerateFlag 500;
BA_ "GenSigInvalidValue" SG_ 1310 TPMS_Suggestion "0";
BA_ "GenSigCycleTime" SG_ 1310 TPMS_Suggestion 500;
BA_ "GenSigCycleTime" SG_ 1310 TPMS_LRLeakageWarning 500;
BA_ "GenSigCycleTime" SG_ 1310 TPMS_RRLeakageWarning 500;
BA_ "GenSigCycleTime" SG_ 1310 TPMS_RFLeakageWarning 500;
BA_ "GenSigCycleTime" SG_ 1310 TPMS_LFLeakageWarning 500;
BA_ "GenSigInvalidValue" SG_ 1310 TPMS_TireTemperature "255";
BA_ "GenSigStartValue" SG_ 1310 TPMS_TireTemperature 40;
BA_ "GenSigCycleTime" SG_ 1310 TPMS_TireTemperature 500;
BA_ "GenSigInvalidValue" SG_ 1310 TPMS_LFTemperatureWarning "0";
BA_ "GenSigCycleTime" SG_ 1310 TPMS_LFTemperatureWarning 500;
BA_ "GenSigInvalidValue" SG_ 1310 TPMS_RFTemperatureWarning "0";
BA_ "GenSigCycleTime" SG_ 1310 TPMS_RFTemperatureWarning 500;
BA_ "GenSigInvalidValue" SG_ 1310 TPMS_RRTemperatureWarning "0";
BA_ "GenSigCycleTime" SG_ 1310 TPMS_RRTemperatureWarning 500;
BA_ "GenSigInvalidValue" SG_ 1310 TPMS_LRTemperatureWarning "0";
BA_ "GenSigCycleTime" SG_ 1310 TPMS_LRTemperatureWarning 500;
BA_ "GenSigInvalidValue" SG_ 1310 TPMS_TirePosition "0";
BA_ "GenSigCycleTime" SG_ 1310 TPMS_TirePosition 500;
BA_ "GenSigCycleTime" SG_ 1683 ACC_DTC2_Status 500;
BA_ "GenSigCycleTime" SG_ 1683 ACC_DTC2_LowByte 500;
BA_ "GenSigCycleTime" SG_ 1683 ACC_DTC2_MiddByte 500;
BA_ "GenSigCycleTime" SG_ 1683 ACC_DTC2_HighByte 500;
BA_ "GenSigCycleTime" SG_ 1683 ACC_DTC1_Status 500;
BA_ "GenSigCycleTime" SG_ 1683 ACC_DTC1_LowByte 500;
BA_ "GenSigCycleTime" SG_ 1683 ACC_DTC1_MiddByte 500;
BA_ "GenSigCycleTime" SG_ 1683 ACC_DTC1_HighByte 500;
BA_ "GenSigCycleTime" SG_ 1684 LAS_DTC2_Status 500;
BA_ "GenSigCycleTime" SG_ 1684 LAS_DTC2_LowByte 500;
BA_ "GenSigCycleTime" SG_ 1684 LAS_DTC2_MiddByte 500;
BA_ "GenSigCycleTime" SG_ 1684 LAS_DTC2_HighByte 500;
BA_ "GenSigCycleTime" SG_ 1684 LAS_DTC1_Status 500;
BA_ "GenSigCycleTime" SG_ 1684 LAS_DTC1_LowByte 500;
BA_ "GenSigCycleTime" SG_ 1684 LAS_DTC1_MiddByte 500;
BA_ "GenSigCycleTime" SG_ 1684 LAS_DTC1_HighByte 500;
BA_ "GenSigSendType" SG_ 1106 NM_message452 1;
VAL_ 381 PCU_RearMotSts 0 "Not Ready" 1 "Ready" ;
VAL_ 381 PCU_ESPTqReqAvlRear 1 "NotAvailable" 0 "Available" ;
VAL_ 381 PCU_PwrTrainSts 3 "预留" 2 "Running" 1 "Crank" 0 "Stop" ;
VAL_ 381 PCU_MbRegenMaxWhlQlfr 2 "Faulty" 1 "Normal" 0 "NotIntialized" ;
VAL_ 381 PCU_MbRegenMaxFrontWhlVld 0 "Invalid" 1 "Valid" ;
VAL_ 381 PCU_APATorqRequestAvailable 1 "available" 0 "not available" ;
VAL_ 381 PCU_APARequestEnable 0 "no request" 1 "Control enabled" 2 " Control disable" 3 "invalid" ;
VAL_ 381 PCU_AccPedlVld 1 "invalid" 0 "valid" ;
VAL_ 381 PCU_StartStopActiveVld 0 "Invalid" 1 "Valid" ;
VAL_ 381 PCU_StartStopActive 0 "Not active，其他情况发0" 1 "active，发动机正常情况下（发动机无报错）停 机发1" ;
VAL_ 381 PCU_RearMotStsVld 0 "Invalid" 1 "Valid" ;
VAL_ 381 PCU_QECACC 0 "no error" 1 "reversible error" 2 "irreversible error" 3 "not defined" ;
VAL_ 381 PCU_PwrIndcdRealTqWhlFailr 0 "valid" 1 "invalid" ;
VAL_ 381 PCU_FrontMotStsVld 0 "Invalid" 1 "Valid" ;
VAL_ 381 PCU_FrontMotSts 0 "Not Ready" 1 "Ready（电机无故障，可以正常输出动力）" ;
VAL_ 381 PCU_ESPTqReqAvlFront 1 "NotAvailable" 0 "Available" ;
VAL_ 381 PCU_EngStsVld 0 "Invalid" 1 "Valid" ;
VAL_ 381 PCU_EngSts 0 "Not Ready" 1 "Ready(发动机无故障，运转正常，且转速高于怠速转速)" ;
VAL_ 381 PCU_EngClutchStsVld 0 "Invalid" 1 "Valid" ;
VAL_ 381 PCU_EngClutchSts 0 "Engaged " 1 "Disengaged" ;
VAL_ 381 PCU_ECGPOvrd 0 "no override" 1 "driver override" ;
VAL_ 381 PCU_AccReqPossible 0 "noerror" 1 "error" ;
VAL_ 381 RGearbox_ActualDrivingGear 0 "Neutral" 1 "1st gear" 2 "Initial " 3 "shift in progress" ;
VAL_ 381 PCU_TarGearReqValid 0 "Valid" 1 "Invalid" ;
VAL_ 381 PCU_TarGearReq 0 "Initial value" 1 "1st gear" 2 "2nd gear" 3 "3rd gear" 4 "4th gear" 5 "5th gear" 6 "6th gear" 7 "7th gear" 8 "8th gear" 9 "Reverse" 10 "Neutral" 11 "Reserved" 12 "Reserved" 14 "Reserved" 15 "Invalid" ;
VAL_ 381 PCU_SpdCtrlModSelect 3 "tq control mode select" 2 "fast speed select" 1 "idle control select" 0 "no mode select" ;
VAL_ 381 PCU_RealAccPedlVld 1 "invalid" 0 "valid" ;
VAL_ 381 PCU_MILReq 0 "not request" 1 "request" ;
VAL_ 381 PCU_K3CluSts 1 "not open" 0 "open" ;
VAL_ 381 PCU_FlywhTqTransLoadActInvld 1 "invalid" 0 "valid" ;
VAL_ 381 PCU_EngStrtMod 7 "ISG Start" 6 "BSG Start" 5 "Slip start" 4 "Pulse start" 3 "Creep start" 2 "Crank start" 1 "12V MOT start" 0 "No start" ;
VAL_ 381 PCU_ClrDiagcInfo 0 "Normal" 1 "Not used" 2 "PCU request EMS to clear P1872" 3 "PCU has cleared diagintoper EMS request" ;
VAL_ 381 PCU_StrtTrqCtl 1 "torque control during start" 0 "No torque control during start" ;
VAL_ 381 PCU_StrtInhb 1 "injection inhibition during start" 0 "No injection inhibition during start" ;
VAL_ 381 PCU_PtStsChrgCrp 3 "idle charge and creep" 2 "creep" 1 "idle charge" 0 "none" ;
VAL_ 381 PCU_FuCutOffReq 0 "Not request" 1 "Request" ;
VAL_ 381 PCU_EngIgnAgIntvEnbl 0 "unable" 1 "enable" ;
VAL_ 381 PCU_EngTqFlywhReqVld 1 "invalid" 0 "valid" ;
VAL_ 381 PCU_EngTqFlywhAllwdMaxVld 1 "invalid" 0 "valid" ;
VAL_ 381 PCU_EngStrtOrd 1 "Request" 0 "No trequest" ;
VAL_ 381 PCU_EngStpOrd 1 "Request" 0 "Not request" ;
VAL_ 381 PCU_EMSSurgeDamperEna 1 "enable" 0 "disable" ;
VAL_ 381 PCU_BrkPedlSts2 1 "Pressed" 0 "Not Pressed" ;
VAL_ 381 PCU_BrkPedlSts1 1 "Not Pressed" 0 "Pressed" ;
VAL_ 381 PCU_VehSts 0 "Standstill" 1 "EV Drive" 2 "Serial Drive" 3 "Parallel Drive" 4 "Regeneration" 5 " Parallel Charge" 6 "Idle Charge" 7 "Idle" ;
VAL_ 381 PCU_VehSpdVld 0 "Valid" 1 "NotValid" ;
VAL_ 381 PCU_ChrgUnlckILimReq 0 "not Limit" 1 "Limit" ;
VAL_ 381 PCU_ChrgSuspReq 0 "UnSuspend" 1 "Suspend" ;
VAL_ 381 PCU_ChrgIReqLimFac 0 "100%" 1 "70%" 2 "30%" 3 "0%" ;
VAL_ 381 PCU_ChrgAllwd 0 "notallow" 1 "allow" ;
VAL_ 381 PCU_CHMAsignalSts 0 "invalid" 1 "valid" ;
VAL_ 381 PCU_BMSOperModReq 0 "Initializing" 1 "Wakeup" 2 "PreCharge" 3 "HVActive" 4 "Powerdown" 5 "=Failure" 6 "Sleep" ;
VAL_ 381 PCU_BattIntrHeatAllwd 0 "notallow" 1 "allow" ;
VAL_ 382 EPS_Pinionang_Valid 0 "valid" 1 "invalid" ;
VAL_ 382 EPS_Handwheel_Relang_Valid 0 "valid" 1 "invalid" ;
VAL_ 382 EPS_Pinionang 14410 "Reserved" ;
VAL_ 382 EPS_LatCtrlActive 0 "Not Actived" 1 "Actived" ;
VAL_ 382 EPS_LatCtrlAvailabilityStatus 0 "not Availability " 1 "Availability" 2 "failure" 3 "reserved" ;
VAL_ 382 EPS_MeasuredTorsionBarTorqValid 0 "可用" 1 "不可用" ;
VAL_ 382 EPS_MeasuredTorsionBarTorque 0 "(Measured Torsion Bar Torque – 0x800)*0.01
?方向盘左打为正。
?在EPS ECU 开始助力之前、Initial 值输出为(0)。
?异常状态（确定故障）的情况下、Invalid 值输出为(0xFFF)。" ;
VAL_ 442 ACC_LatAngReqActive 0 "not Active" 1 "Active" ;
VAL_ 442 ACC_LatAngReq 14410 "Reserved" ;
VAL_ 442 ACC_MotorTorqueMinLimitRequest 2047 " Reserved" ;
VAL_ 442 ACC_MotorTorqueMaxLimitRequest 2047 " Reserved" ;
VAL_ 523 IBCU_BrkPedlStsGbVld 0 "NotInitialized" 1 "Normal" 2 "Invalid" ;
VAL_ 523 IBCU_BrkPedoplStsGb 0 " 制动未踩下" 101 " 制动踩下" 254 "异常" ;
VAL_ 523 ESP_Vehicle_Speed_Reference 0 "0~360km/h" 6401 "Reserved" 8191 "Invalid" ;
VAL_ 523 IBCU_precheckStatus 0 "not checked" 1 "in checking" 2 "checked" 3 "failed" ;
VAL_ 523 ESP_PrefillforAPA_Available 0 "notavailable" 1 "available" ;
VAL_ 523 ESP_PrefillforAPA_active 0 "notactive" 1 "active" ;
VAL_ 523 IBCU_BrakeDiscHighTempWarning 0 "no failure" 1 "OverheatLevel1" 2 "OverheatLevel2" 3 "reserved" ;
VAL_ 523 Wheel_Speed_RR_Valid_Data 0 "Valid" 1 "NotValid" ;
VAL_ 523 Wheel_Speed_RR_Direction 0 "Forward" 1 "backward" 2 "Standstill" 3 "Invalid" ;
VAL_ 523 Wheel_Speed_RL_Valid_Data 0 "Valid" 1 "NotValid" ;
VAL_ 523 Wheel_Speed_RL_Direction 0 "Forward" 1 "backward" 2 "Standstill" 3 "Invalid" ;
VAL_ 523 Wheel_Speed_FR_Valid_Data 0 "Valid" 1 "NotValid" ;
VAL_ 523 Wheel_Speed_FR_Direction 0 "Forward" 1 "backward" 2 "Standstill" 3 "Invalid" ;
VAL_ 523 Wheel_Speed_FL_Valid_Data 0 "Valid" 1 "NotValid" ;
VAL_ 523 Wheel_Speed_FL_Direction 0 "Forward" 1 "backward" 2 "Standstill" 3 "Invalid" ;
VAL_ 523 ESP_VehicleStandstill 0 "notstandstill" 1 "standstill" ;
VAL_ 523 ESP_VDCActive 0 "NotActive" 1 "Active" ;
VAL_ 523 ESP_UrgencyBrakeAlarm 0 "NotActive" 1 "Active" ;
VAL_ 523 ESP_TCSActive 0 "NotActive" 1 "Active" ;
VAL_ 523 ESP_QDCACC 0 "noerror" 1 "error" 2 "reserved" 3 "reserved" ;
VAL_ 523 ESP_PrefillAvailable 0 "notavailable" 1 "available" ;
VAL_ 523 ESP_PrefillActive 0 "notactive" 1 "active" ;
VAL_ 523 ESP_OnlyABSActive 0 "NotActive" 1 "Active" ;
VAL_ 523 ESP_MasCylBrakePressureValid 0 "Valid" 1 "Invalid" ;
VAL_ 523 ESP_IncreasePressureReqOK 0 "Not_OK" 1 "OK" ;
VAL_ 523 ESP_HHC_Available 0 "Available" 1 "NotAvailable" ;
VAL_ 523 ESP_HHC_Active 0 "functionisnotinactive" 1 "functionisinactive" ;
VAL_ 523 ESP_HDC_STATUS 0 "OFF" 1 "ON" 2 "Standby" 3 "Error" ;
VAL_ 523 ESP_HBBActiveStatus 0 "NotActive" 1 "Active" ;
VAL_ 523 ESP_ECDAvailable 0 "Valid" 1 "Invalid" ;
VAL_ 523 ESP_ECDActive 0 "NotActive" 1 "Active" ;
VAL_ 523 ESP_CDP_ParkingAvailForACC 0 "Available" 1 "not available" ;
VAL_ 523 ESP_CDP_ParkingActiveForACC 0 "Active" 1 "not Active" ;
VAL_ 523 ESP_CDD_Available_APA 1 "available" 0 "notavailable" ;
VAL_ 523 ESP_CDD_Available 0 "notavailable" 1 "available" ;
VAL_ 523 ESP_CDD_Active_APA 1 "active" 0 "notactive" ;
VAL_ 523 ESP_CDD_Active 0 "notactive" 1 "active" ;
VAL_ 523 ESP_BrakeOverHeatBrakeDiscTemp 0 "nothigh" 1 "temptoohigh" ;
VAL_ 523 ESP_BrakeLightOnRequest 0 "brakelightOFF" 1 "brakelightON" 2 "notused" 3 "signalnotavailable" ;
VAL_ 523 ESP_BrakeForce 0 "nobrakeforce" 1 "havebrakeforce" ;
VAL_ 523 ESP_AWBavailable 0 "notavailable" 1 "available" ;
VAL_ 523 ESP_AWBactive 0 "notactive" 1 "active" ;
VAL_ 523 ESP_AutoHoldStandby 0 "NotActive" 1 "Active" ;
VAL_ 523 ESP_AutoHoldAvailable 0 "Valid" 1 "Invalid" ;
VAL_ 523 ESP_AutoHoldActive 0 "NotActive" 1 "Active" ;
VAL_ 523 ESP_AEBdecActive 0 "notactive" 1 "active" ;
VAL_ 523 ESP_AEBAvailable 0 "notavailable" 1 "available" ;
VAL_ 523 ESP_ABAavailable 0 "notavailable" 1 "available" ;
VAL_ 523 ESP_ABAactive 0 "notactive" 1 "active" ;
VAL_ 523 ABS_TODFastOpenRequest 0 "Passive" 1 "OpenClutch" 2 "Torquemaxlimit" 3 "Error" ;
VAL_ 591 EPS_SystemSt 0 "disable" 1 "off" 2 "enable" 3 "warm int" 4 " Reserved" ;
VAL_ 591 EPS_LDW_ShakeLevStatus 0 "reserved" 1 "low" 2 "normal" 3 "high" ;
VAL_ 591 EPS_ConcussAvailabilityStatus 0 "Concuss Availability 震动可用但是未震动" 1 "Concuss Active震动激活中" 2 "EPS Concuss failure  EPS震动故障不可用" 3 "reserved" ;
VAL_ 591 EPS_TorqueAssistMode 0 "Normal" 1 "light" 2 "heavy" 3 "unknow" ;
VAL_ 591 EPS_IACC_abortreason 0 "NO_DRIVING_INTERUPTION" 1 "DRIVER_RECOVERY(Over ride)" 2 "VEHICLE_SPEED ERROR" 3 "REQUEST ERROR" 4 "DAE_THERMAL_SECURITY" 5 "OTHER_DEFAULT" 6 "ADAS message Error（CD569项目0x6=Reserved）" 7 "Reserved" ;
VAL_ 591 EPS_ModeSwitchSt 0 "No judgment" 1 "In judgment" ;
VAL_ 591 EPS_EPSFailed 0 "No failure" 1 "Slight failure" 2 "Critical failure" 3 "Fatal failure" 4 "Reserved" ;
VAL_ 591 EPS_TorqSensorStatus 0 "Normal" 1 "Abnormal" ;
VAL_ 591 EPS_APA_Abortfeedback 0 "NO_DRIVING_INTERUPTION" 1 "DRIVER_RECOVERY" 2 "TOO_HIGH_VEHICLE_SPEED" 3 "TOO_IMPORTANT_ANGULAR_ERROR" 4 "TOO_IMPORTANT_ANGULAR_SPEED_ERROR" 5 "DAE_THERMAL_SECURITY" 6 "DAE_LIMIT_SECURITY" 7 "OTHER_DEFAULT" ;
VAL_ 591 EPS_APA_EpasFAILED 0 "No Fail" 1 "Fail" ;
VAL_ 591 EPS_APA_ControlFeedback 0 "Control disable" 1 "Control enabled" ;
VAL_ 651 BCM_RefuelReq 0 "无请求" 1 "有请求" ;
VAL_ 651 BCM_TrunkReleaseTrigger 0 "none" 1 "RKE行李箱解锁" 2 "PKE行李箱解锁" 3 "行李箱外部开关解锁" 4 "脚踢行李箱解锁" 5 "车内行李箱开关解锁" 6 "远程行李箱解锁" 7 "蓝牙行李箱解锁" 8 "主动感应行李箱解锁" 9 "蓝牙实体钥匙行李箱解锁" ;
VAL_ 651 BCM_LockTrigger 0 "none" 1 "RKE闭锁" 2 "PKE闭锁" 3 "中控闭锁" 4 "速度落锁" 5 "二次落锁" 6 "机械闭锁" 7 "远程闭锁" 8 "蓝牙闭锁" 9 "离车自动闭锁" 10 "HU闭锁" 11 "APA后闭锁" 12 "主动迎宾闭锁" 13 "开放功能闭锁" 14 "电动背门双击闭锁" 15 "NFC闭锁" 16 "UWB实体钥匙闭锁" 17 "远程音乐灯光秀闭锁" 18 "人脸闭锁" 19 "分级迎宾闭锁" ;
VAL_ 651 BCM_UnlockTrigger 0 "none" 1 "RKE解锁" 2 "PKE解锁" 3 "中控解锁" 4 "驻车解锁" 5 "钥匙在车内解锁" 6 "机械解锁" 7 "远程解锁" 8 "蓝牙解锁" 9 "HU解锁" 10 "主动迎宾解锁" 11 "关门解锁功能" 12 "ACC安全停车解锁" 13 "开放功能解锁" 14 "NFC解锁" 15 "UWB实体钥匙解锁" 16 "远程音乐灯光秀解锁" 17 "人脸解锁" 18 "分级迎宾解锁" ;
VAL_ 651 BCM_TurnIndicatorLeft 0 "OFF" 1 "ON" 2 "Not used" 3 "Error" ;
VAL_ 651 BCM_TurnIndicatorRight 0 "OFF" 1 "ON" 2 "Not used" 3 "Error" ;
VAL_ 651 PEPS_ShiftForbidRq 0 "AllowShift" 1 "ForbidShift" ;
VAL_ 651 BCM_KeyAlarmStatus 0 " Disarmed" 1 " Prearmed" 2 " Armed" 3 " Activated" ;
VAL_ 651 PEPS_RemoteStartReq 0 " Not Remote Start" 1 " Remote Start" 2 "Reserved" 3 "invalid" ;
VAL_ 651 BCM_emergencylightstatus 0 "OFF" 1 "ON" 2 "Not used" 3 "Error（故障）" ;
VAL_ 651 BCM_PowerStatusFeedback 0 "OFF" 1 "ACC" 2 "ON" 3 "Start" ;
VAL_ 651 BCM_RearDefrosterstatus 0 "OFF" 1 "ON" 2 "Not used" 3 "Reserved" ;
VAL_ 651 BCM_DriverDoorStatus 0 "Close" 1 "Open" ;
VAL_ 651 BCM_HoodStatus 0 "Close" 1 "Open" ;
VAL_ 651 PEPS_StartControlsignal 0 " No Request" 1 "Startup Start" 2 "Startup Stop" 3 " Invalid" ;
VAL_ 651 BCM_LowBeamStatus 0 "OFF" 1 "ON" 2 "Not used" 3 "Reserved" ;
VAL_ 651 BCM_HighBeamStatus 0 "OFF" 1 "ON" 2 "Not used" 3 "Reserved" ;
VAL_ 651 BCM_TurnLightSwitchSts 0 "Not Actived" 1 "Left Actived" 2 "Right Actived" 3 "Invalid" ;
VAL_ 651 BCM_MirrorAdjustSts 0 "未调节
0x1=左外后视镜调节
0x2=右外后视镜调节
0x3=预留" ;
VAL_ 721 BCM_BrakeLampStatus 0 "OFF" 1 "ON" 2 "Not used" 3 "Reserved" ;
VAL_ 721 BCM_TrunkDoorStatus 0 "Close" 1 "Open" ;
VAL_ 721 BCM_RightRearDoorStatus 0 "Close" 1 "Open" ;
VAL_ 721 BCM_PassengerDoorStatus 0 "Close" 1 "Open" ;
VAL_ 721 PEPS_LuggageUnlockSignal 0 " Inactive" 1 " 遥控行李箱解锁" 2 " PE行李箱解锁" 3 " 不可用" ;
VAL_ 721 BCM_ReversePosition 0 " NOT IN Reverse" 1 " IN Reverse" ;
VAL_ 734 IP_DriverLCDALEDSts 0 "No Error" 1 "Error" ;
VAL_ 734 IP_PassengerLCDALEDSts 0 "No Error" 1 "Error" ;
VAL_ 734 IP_DISFail 0 "no error" 1 "error" ;
VAL_ 734 IP_QDashACCFail 0 "no error" 1 "error" 2 "reserved" 3 "reserved" ;
VAL_ 742 EMS_WarmUpCycle 1 "achieved" 0 "not achieved" ;
VAL_ 742 EMS_LoBattErr 1 "Error," 0 "No error" ;
VAL_ 742 EMS_IgnitionCyclesCounterValid 0 "valid" 1 "Invalid" ;
VAL_ 742 EMS_GeneralDenoStatusValid 0 "valid" 1 "Invalid" ;
VAL_ 742 EMS_DrivingCycle 1 "achieved" 0 "not achieved" ;
VAL_ 742 EMS_CooltTErr 0 "No error" 1 "Error" ;
VAL_ 742 EMS_CatalystWarmUp 1 "request." 0 "not request" ;
VAL_ 742 EMS_AltitudeFactorValid 0 "Valid" 1 "NotValid" ;
VAL_ 794 ADC_EcasModeReq 0 "No Request" 1 "Auto_Disable" 2 "Manual_Disable" 3 "Disable" 4 "Standard_Height" 5 "Reserved" ;
VAL_ 794 ACC_LngTakeOverReqReason 0 "无报警" 1 "控制器、传感器故障" 2 "关联子系统故障" 3 "超过纵向控制能力限制" 4 "前方存在危险目标（如行人、锥形筒等障碍物）" 5 "车道线置信度低" 6 "超过车速、曲率、方向盘转角等阈值限制" 7 "非安全状态（ESP、TCS、AEB等触发）" 8 "触发风险减缓" 9 "超出ODD范围" 10 "预留" ;
VAL_ 794 ACC_ELKAlert 0 "No warning" 1 "left Warning" 2 "right Warning" 3 "reserved" ;
VAL_ 794 ACC_ELKEnableStatus 0 "off" 1 "on" ;
VAL_ 794 ACC_ELKInterventionMode 0 " off" 1 " Road edge" 2 " Overtaking" 3 " Oncoming." ;
VAL_ 794 ACC_ELKMode 0 " off" 1 " passive" 2 "active" 3 " fault" 4 " reserved." ;
VAL_ 794 ACC_RRLaneDetection 0 "not detected" 1 "Dashed" 2 "solid" 3 "fence/road edge" ;
VAL_ 794 ACC_LLLaneDetection 0 "not detected" 1 "Dashed" 2 "solid" 3 "fence/road edge" ;
VAL_ 794 ACC_HighBeamControl 0 "No Request" 1 "Request" 2 "Reserved" ;
VAL_ 794 ACC_TargetBasedLateralControl 0 "no lateral control" 1 "around Based" 2 "lane based" 3 "target based" ;
VAL_ 794 ACC_IACCHWATextInfoForDriver 0 "no display" 1 "IACC Cancel" 2 "IACC deactivate" 3 "IACC unintended exit" 4 "unable to activate IACC" 5 "lane condition not available" 6 "ADR/DVR Status not Match" 7 "longitudinal control not available" 8 "IACC not available by EPS" 9 "exceed speed limit" 10 "driver overrides steering" 11 "caution about driving safty" 12 " system error" 13 " prohibition request for safestop" 14 "turn light switch on" 15 "Hands on plz" 16 " Please turn on IACC in incall " 17 " unable to active in curve" 18 " unable to active for not in lane/crossing lane" 19 "Longitude Exit" 20 "takeover request with safety stoping" 21 "takeover request with safety stop completed" 22 "other system error" 23 "unable to active in Bad weather" 24 "Prohibition request for rdf" 25 "Lights OFF please" 26 "智慧偏移，避让大型车辆" 27 " Driver Drowsy or Distracted" 28 "HWA recommend" 29 "lane missing" 30 "请注意侧方车辆，谨慎驾驶
0x1F=系统退出-安全带解开
0x20=系统状态-暂停状态
0x21=系统退出-车门开启
0x22=邻车道大车压迫-偏移避让正在偏移，避让车辆
0x23=锥形桶等障碍物-偏移避让
0x24=护栏压迫-偏移避让
0x25=智慧偏移，避让小车" ;
VAL_ 794 ACC_EmergencyLightingRequest 0 "no request" 1 "Level1" 2 "Level2" 3 "OFF" ;
VAL_ 794 ACC_DriverHandsOffStatus 0 "hands off" 1 "hands on Level1" 2 "hand on Level2" 3 "unkown" ;
VAL_ 794 ACC_IACCHWAMode 0 "off" 1 "standby" 2 "passive" 3 "active" 4 "suspend" 5 " prohibition" 6 "reserved" 7 "failure" ;
VAL_ 794 ACC_LaneChangeStatus 0 "未变道" 1 "向左变道中" 2 "向右变道中" 3 "变道结束" ;
VAL_ 794 ACC_RoadCurvatureFar 0 "-0.03-0.03" 121 "reserved" ;
VAL_ 794 ACC_RoadCurvatureNear 0 "-0.03-0.03" 121 "reserved" ;
VAL_ 794 ACC_RoadCurvature 0 "-0.03-0.03" 121 "reserved" ;
VAL_ 794 ACC_IACCHWAEnable 0 "OFF" 1 "ON" ;
VAL_ 794 ACC_RLaneMarkerType 0 "Dashed" 1 "solid" 2 "road edge" 3 "double lane mark" 4 "Botts' dots" 5 "other" 6 "fence" 7 "no display" 8 "Fishbone" 9 "Dashed_Fishbone" ;
VAL_ 794 ACC_LLaneMarkerType 0 "Dashed" 1 "solid" 2 "road edge" 3 "double lane mark" 4 "Botts' dots" 5 "other" 6 "fence" 7 "no display" 8 "Fishbone" 9 "Dashed_Fishbone" ;
VAL_ 794 ACC_HostLaneRightStatus 0 "No_display" 1 "Tracking" 2 "Intervention" 3 "Warning 
0x4=Centering " 5 "Crossing " 6 "UDLC_Wait_Active" 7 "ACCactive" 8 "UDLC_Not_Active" 9 " IACCactive" 10 "NIDactive" ;
VAL_ 794 ACC_HostLaneLeftStatus 0 "No_display" 1 "Tracking" 2 "Intervention" 3 "Warning 
0x4=Centering " 5 "Crossing " 6 "UDLC_Wait_Active" 7 "ACCactive" 8 "UDLC_Not_Active" 9 " IACCactive" 10 "NIDactive" ;
VAL_ 794 ACC_LASWarningModeSelectionSts 0 "Reserved" 1 "sound" 2 "vibration" 3 "sound and vibration" 4 "Reserved" ;
VAL_ 794 ACC_LASModeSelectionStatus 0 "Reserved" 1 "LDW" 2 "LKA" 3 "LCS" 4 "Reserved" 7 "OFF" ;
VAL_ 794 ACC_FRadarFailureStatus 0 " no failure" 1 "blind" 2 "reversible failure" 3 " irrversible failure" ;
VAL_ 794 ACC_AEBTargetLatRange 0 "-50-50m" 1001 "reserved" ;
VAL_ 794 ACC_AEBTargetRelSpeed 0 "-250-250" 501 "reserved" ;
VAL_ 794 ACC_AEBTargetLngRange 0 "-70~180" 501 "reserved" 511 "no display" ;
VAL_ 794 ACC_Voiceinfo 0 "no voice" 1 "latentWarning voive" 2 "FCW/AEB voice" 3 "ACC object detect voice" 4 "ACC object disappeared voice" 5 "ACC/IACC takeover request voice" 6 "Lane Left dangerous warning  voice" 7 "Lane Right dangerous warning  voice" 8 "reserved" 9 "IACC Active voice" 10 "IACC exit voice" 11 "reserved" 12 "reserved" 13 "cruise unintended exit" 14 "TrafficWarning" 15 "reserved" ;
VAL_ 794 ACC_AEBTargetmode 0 "none" 1 "video only mode" 2 "rader only mode" 3 "fusion mode" ;
VAL_ 794 ACC_AEBTextInfo 0 "no display" 1 "AEB Error by camera" 2 "AEB Error by FR" 3 "AEB Error by Dasy" 4 "AEB Error by FCR" 5 "AEB Error by EPBi" 6 "AEB Error by SAS" 7 "AEB Error by SRS" 8 "AEB Error by EMS" 9 "AEB Error by TCU" 10 "AEB Error by other" 11 "AEB Error by high temperature " 12 "reserved" ;
VAL_ 794 ACC_AEBStatus 0 "off" 1 "on" 2 " reserved" 3 "failure" ;
VAL_ 853 EMS_CruiseDistance 0 "Inactive" 1 "Acitve" ;
VAL_ 853 EMS_CruiseSwitchSET 0 "Inactive" 1 "Acitve" ;
VAL_ 853 EMS_CruiseSwitchCANCEL 0 "Inactive" 1 "Acitve" ;
VAL_ 853 EMS_CruiseSwitchResume 0 "Inactive" 1 "Acitve" ;
VAL_ 853 EMS_CruiseSwitchOnOff 0 "Off" 1 "On" ;
VAL_ 943 HU_Novice_Enable 0 "Inactive" 1 "Off" 2 "On" 3 "Reserved" ;
VAL_ 943 HU_EHPHeartFlag 0 "正常" 1 "异常" ;
VAL_ 943 HU_EHRHeartFlag 0 "正常" 1 "异常" ;
VAL_ 943 HU_ServiceRoadDis 0 " 0~600m" 61 "Out of Range" 62 "reserved" 63 "unknown" ;
VAL_ 943 HU_ServiceRoad 0 "unknown" 1 "进入服务区引路" 2 "reserve" 3 "invalid" ;
VAL_ 943 HU_BridgeDis 0 " 0~600m" 61 "Out of Range" 62 "reserved" 63 "unknown" ;
VAL_ 943 HU_BridgeInfo 0 "unknown" 1 "桥梁入口" 2 "桥梁中" 3 "桥梁出口" ;
VAL_ 943 HU_AccidentProneDistance 0 " 0~600m" 61 "Out of Range" 62 "reserved" 63 "unknown" ;
VAL_ 943 HU_AccidentProne 0 "unknown" 1 "前方为事故多发地" 2 "reserve
0x3=invalid" ;
VAL_ 943 HU_IntervalVelocityDis 0 " 0~600m" 61 "Out of Range" 62 "reserved" 63 "unknown" ;
VAL_ 943 HU_IntervalVelocityInfo 0 " unknown" 1 "区间测速起始点" 2 "区间测速结束点
0x3=reserved" ;
VAL_ 943 HU_SlopeGradient_100m 1023 " unknown" ;
VAL_ 943 HU_SlopeGradient_50m 1023 " unknown" ;
VAL_ 943 HU_SlopeGradient_40m 1023 " unknown" ;
VAL_ 943 HU_SlopeGradient_30m 1023 " unknown" ;
VAL_ 943 HU_SlopeGradient_20m 1023 " unknown" ;
VAL_ 943 HU_SlopeGradient_10m 767 " unknown" ;
VAL_ 943 HU_RampDistance 0 " 0~3000m" 301 "reserved" 1022 "Out of Range" 1023 "unknown" ;
VAL_ 943 HU_NavSpeedLimitType 0 "Unknown" 1 "Speed-Limit Sign" 2 "Road Camera" 3 "Interval Velocity" ;
VAL_ 943 HU_CurveDistance 0 " 0~600m" 61 "Out of Range" 62 "reserved" 63 "unknown" ;
VAL_ 943 HU_EnterCurveInfo 0 " unknown" 1 "弯道进口" 2 "弯道中" 3 "弯道出口" ;
VAL_ 943 HU_NavCurrentRoadType 0 "
0x0=Road Type Unknown= Small road, Walking Street" 1 "Road Type Class 1= Secondary Roads" 2 "Road Type Class 2= Mainly Road in City" 3 "Road Type Class 3= Mainly Road in City, Normal Province Road, Mainly street" 4 "Road Type Class 4= Province Road, Mainly Road " 5 "Road Type Class 5= Highway, National Road, Speed road" 6 "Reserved

2.搭载ADAS=
0x0=未知" 1 "城市主要道路" 2 "城市快速路" 3 "省道，县道" 4 "国道" 5 "高速路" 6 "次要道路，普通道路，乡公路，县乡内部路" 7 "预留" ;
VAL_ 943 HU_EnterRampInfo 0 "Unknown" 1 "匝道进口" 2 "匝道中" 3 "匝道出口" ;
VAL_ 943 HU_RampInfo 0 "Unknown" 1 "有匝道，但本车不出高速" 2 "本车通过匝道进入高速" 3 "本车通过匝道出高速" ;
VAL_ 943 HU_NavStatus 0 "Normal" 1 "Error" ;
VAL_ 943 HU_NavSpeedLimitUnits 3 "reserved" 2 "unit mph" 1 "unit kph" 0 "unknown." ;
VAL_ 943 HU_NavSpeedLimitStatus 3 "reserved" 2 "reserved" 1 "invalid" 0 "valid" ;
VAL_ 943 HU_NavSpeedLimit 0 "Unlimited" 1 "SL 5" 2 "SL 10" 32 "SL 160" 254 "Unknown" 255 "Invalid" ;
VAL_ 943 HU_SpeedLimitDistance 0 " 0~600m" 61 "Out of Range" 62 "reserved" 63 "unknown" ;
VAL_ 947 BCM_DoorHandle_TimeDifference 0 "0ms" 1 "5ms" 251 "预留" 255 "Invalid" ;
VAL_ 947 BCM_RightRearDoorHandleStatus 0 "无效" 1 "展开位置" 2 "收回位置" 3 "预留" ;
VAL_ 947 BCM_PassengeDoorHandleStatus 0 "无效" 1 "展开位置" 2 "收回位置" 3 "预留" ;
VAL_ 947 LCM_ReverseLightSts 0 "OFF" 1 "ON" 2 "Not used" 3 "Error" ;
VAL_ 947 BCM_ReverseLampError 0 "无故障" 1 "有故障" ;
VAL_ 947 BCM_CHMLampError 0 "无故障" 1 "有故障" ;
VAL_ 947 BCM_BrakeLampError 0 "无故障" 1 "有故障" ;
VAL_ 947 BCM_RightRearFoglampError 0 "无故障" 1 "有故障" ;
VAL_ 947 BCM_LeftRearFoglampError 0 "无故障" 1 "有故障" ;
VAL_ 947 BCM_RearPositionLampError 0 "无故障" 1 "有故障" ;
VAL_ 947 BCM_RearFoglampStatus 0 "OFF" 1 "ON" 2 "Not used" 3 "Error" ;
VAL_ 957 HU_ADSRoadVoiceEnable 0 "Inactive" 1 "Off" 2 "On" 3 " Reserved" ;
VAL_ 957 HU_ADSLaneChangeVoiceEnable 0 "Inactive" 1 "Off" 2 "On" 3 " Reserved" ;
VAL_ 957 HU_ADSSafeVoiceEnable 0 "Inactive" 1 "Off" 2 "On" 3 " Reserved" ;
VAL_ 957 HU_AVMMapDisplayFeedback 0 "reserved" 1 "open" 2 "closed" 3 "invalid" ;
VAL_ 957 HU_APAThemeChange 0 "Day" 1 "Night" 2 "RACE" 3 "Reserved" ;
VAL_ 957 HU_RearFoglampSet 0 "inactive" 1 "off
0x2=on
0x3=Reserve" ;
VAL_ 957 HU_AutoHeadLiSet 0 "inactive" 1 "off
0x2=位置灯
0x3=近光灯
0x4=自动大灯
0x5~0x7=Reserve" ;
VAL_ 957 HU_TransparentValueCarRequest 0 "Inactive" 1 "0% ~ 100% 透明度值
0x66~0x7f = Reserved" ;
VAL_ 957 HU_RADSSwitch 0 "Invalid" 1 "On" 2 "Off" 3 "Suspend" ;
VAL_ 957 HU_CurrentMedia_Info 0 "Invalid" 1 "FM1" 2 "FM2" 3 "FM3" 4 "AM1" 5 "AM2" 6 "AM2" 7 "MW2" 8 "LW" 9 "OIRT" 10 "保留" 16 "HDD Audio 本地音乐" 17 "HDD Video" 18 "USB音乐" 19 "USB Video" 20 "蓝牙音乐" 21 "AUX" 22 "DISC" 23 "第三方音源" 24 "在线电台" 25 "在线音乐" 26 "在线节目" 27 "预留" ;
VAL_ 957 HU_LaneChangeReq 0 "NoRequest" 1 "LaneChangeToLeft" 2 " LaneChangeToRight" 3 "Reserved" ;
VAL_ 957 HU_HWAEnable 0 "Inactive" 1 "OFF" 2 "ON" 3 "Reserved" ;
VAL_ 957 HU_Compass 0 " 0~360°" 361 " Reserved" 511 "Invalid Value" ;
VAL_ 957 HU_APARemoteDispSts 0 "off" 1 "on" ;
VAL_ 957 HU_RemoteDispSts 0 "Inactive" 1 "Active" ;
VAL_ 957 HU_IRLCEnable 0 "Inactive" 1 "OFF" 2 "ON" 3 "Reserved" ;
VAL_ 957 HU_ADSRescueConfirm 0 "no response" 1 "do not need rescue" 2 "need rescue" 3 "cancel" ;
VAL_ 957 HU_CSLAEnable 0 "OFF" 1 "All Speed-Limit" 2 "Road Camera" 3 "invalid" ;
VAL_ 957 HU_UDLCEnable 0 "Inactive" 1 "OFF" 2 "ON" 3 "Reserved" ;
VAL_ 957 HU_ESSEnable 0 "Inactive" 1 "OFF" 2 "ON" 3 "Reserved" ;
VAL_ 957 HU_ELKEnable 0 "Inactive" 1 "OFF" 2 "ON" 3 "Reserved" ;
VAL_ 957 HU_TLAEnable 0 "Inactive" 1 "OFF" 2 "ON" 3 "Reserved" ;
VAL_ 957 HU_EXT_RemoteDetectUploadStatus 0 "Invalid" 1 "Yes" 2 "No" 3 "Reserved" ;
VAL_ 957 HU_PACModeSelect 0 "normal" 1 "parallel" 2 "asistant line off" 3 "Invalid" ;
VAL_ 957 HU_APAActive 0 "disactive" 1 "active" ;
VAL_ 957 HU_CrossParkingModeSet 0 "Inactive" 1 "Back In" 2 "Head In" 3 "Reserved" ;
VAL_ 957 HU_ASPSwitch 0 "Inactive" 1 "Off" 2 "On" 3 "Reserved" ;
VAL_ 957 HU_ASPRemindEnable 0 "Inactive" 1 "Off" 2 "On" 3 "Reserved" ;
VAL_ 957 HU_ASPModeSelect 0 "Idle" 1 "HU ASP mode" 2 "APP ASP mode" 3 "Cancle" 4 "Reserved" 7 "Invalid" ;
VAL_ 957 HU_LAEBEnable 0 "Inactive" 1 "Off" 2 "On" 3 "Reserved" ;
VAL_ 957 HU_APAModeSelect 0 "Parallel Mode（平行）" 1 "Cross Mode（垂直）" 2 " POC Mode （泊出）" 3 "Invalid" 4 "Echelon Mode（斜列式）" 5 "function  off" 6 "default" 7 "No selection" ;
VAL_ 957 HU_DVRUpdateReq 0 "no action（无操作）" 1 "UpdateReq（升级请求）" 2 "reserved（预留）" 3 "reserved（预留）" ;
VAL_ 957 HU_LicenseNumberCheckSum 0 " (字符内容1 +字符内容2 …+ 字符内容n) XOR 0xFF" ;
VAL_ 957 HU_LicenseNumber 0 "Inactive" 1 "A" 2 "B" 3 "C" 4 "D" 5 "E" 6 "F" 7 "G" 8 "H" 9 "I" 10 "J" 11 "K" 12 "L" 13 "M" 14 "N" 15 "O" 16 "P" 17 "Q" 18 "R" 19 "S" 20 "T" 21 "U" 22 "V" 23 "W" 24 "X" 25 "Y" 26 "Z" 27 " ? " 28 " - " 29 "0" 30 "1" 31 "2" 32 "3" 33 "4" 34 "5" 35 "6" 36 "7" 37 "8" 38 "9" 39 "京" 40 "津" 41 "冀" 42 "晋" 43 "蒙" 44 "辽" 45 "吉" 46 "黑" 47 "沪" 48 "苏" 49 "浙" 50 "皖" 51 "闽" 52 "赣" 53 "鲁" 54 "豫" 55 "鄂" 56 "湘" 57 "粤" 58 "桂" 59 "琼" 60 "渝" 61 "川" 62 "贵" 63 "云" 64 "臧" 65 "陕" 66 "甘" 67 "青" 68 "宁" 69 "新" 70 "港" 71 "澳" 72 "台" 73 "领" 74 "使" 75 "警" 76 "学" 77 " Reserved" ;
VAL_ 957 HU_LicenseNumberSet 0 "Inactive" 1 "Set Number 1" 2 " Set Number 2" 3 " Set Number 3" 4 " Set Number 4" 5 " Set Number 5" 6 " Set Number 6" 7 " Set Number 7" 8 " Set Number 8" 9 " Set Number 9" 10 " Reserved" ;
VAL_ 957 HU_WheelHubSet 0 "Inactive" 1 "type 1" 2 "type 2" 3 "type 3" 4 "type 4" 5 " Reserved" ;
VAL_ 957 HU_BodyColourSet 0 "Inactive" 1 "colour 1" 2 "colour 2" 3 "colour 3" 4 "colour 4" 5 "colour 5" 6 "colour 6" 7 "colour 7" 8 "colour 8" 9 "colour 9" 10 "colour 10" 11 "colour 11" 12 "colour 12" 13 "colour 13" 14 "colour 14" 15 "Reserved" ;
VAL_ 957 HU_AVMDVRReplayModeReq 0 "no request" 1 "enter cycle mode browse" 2 "enter emergency mode browse" 3 "enter photo mode browse" 4 "enter DAS mode browse" 5 "Reserved" 6 "Reserved" 7 "Reserved" ;
VAL_ 957 HU_HUDPosAdjustDec 0 "not active" 1 "active" ;
VAL_ 957 HU_HUDPosAdjustInc 0 "not active" 1 "active" ;
VAL_ 957 HU_VC_VR 0 "Recording" 1 "Recognizing" 2 "Display" 3 "Reserved" ;
VAL_ 957 HU_Seeoffanimation 0 "notactive" 1 "active" ;
VAL_ 957 HU_LanguageSync 0 "Chinese" 1 "English" 2 "Russian" 3 "Arabic  其他位预留" ;
VAL_ 957 HU_DVREditSelected 0 "Not Selected" 1 "Selected" ;
VAL_ 957 HU_SurrondingMonitorDone 0 "No Feedback" 1 "Finished" ;
VAL_ 957 HU_BcallReq 0 "no request" 1 "call up(拨电话）" 2 "hang up(挂电话）0x3=Reserved" ;
VAL_ 957 HU_DVRErrorRecord 0 "Inactive" 1 "Quit" 2 "DisplayReq" 3 "Reserved" ;
VAL_ 957 HU_DVRSystemImprint 0 "Inactive" 1 "Quit" 2 "DisplayReq" 3 "Reserved" ;
VAL_ 957 HU_SDCapacity 0 "Inactive" 1 "Quit" 2 "DisplayReq" 3 "Reserved" ;
VAL_ 957 HU_TUIDReq 0 " NoRequest" 1 "Request" 2 " Reserved" 3 "Invalid" ;
VAL_ 957 HU_RegisterStatus 0 "NoRegister" 1 "RegisterSucceed" 2 "RegisterUnsuccessful" 3 "Registered" ;
VAL_ 957 HU_AutoViewSet 0 "Off" 1 "On" ;
VAL_ 957 HU_RealTimeReq 0 "Inactive" 1 "Quit" 2 "Enter" 3 "Reserved" ;
VAL_ 957 HU_RebroadcastReq 0 "Inactive" 1 "Quit" 2 "Enter" 3 "Reserved" ;
VAL_ 957 HU_360AVMdetectionRequest 0 "No Request" 1 "All+Left" 2 "All+Right" 3 "All+ Front" 4 "All+Rear" 5 "180° Front" 6 "Left+Right" 7 "180°Rear" 8 "All+3DFront" 9 "All+3DRear" 10 "All+3DLeft" 11 "All+3DRight" 12 "All+3DLeftFront" 13 "All+3DRightFront" 14 "All+3DLeftRear" 15 "All+3DRightRear" 16 "All+FrontLookdown" 17 "All+RearLookdown" 18 "ALL+TopFront" 19 "Reserved" ;
VAL_ 957 HU_3DAVMReq 0 "Disable" 1 "Enable" 2 "Reserved" 3 "Invalid" ;
VAL_ 957 HU_VisionAngleReq 0 "No Request" 1 "120°请求" 2 "180°请求" 3 "Invalid" ;
VAL_ 964 HU_MapMatchStatus 0 "Successl" 1 "Fail" 2 "保留" 3 "无效" ;
VAL_ 964 HU_MapDataUpdateStatus 0 "未更新" 1 "1个月内更新" 2 "3个月内更新" 3 "6个月内更新" 4 "1年内更新" 5 " reserved" 7 "Invalid" ;
VAL_ 964 HU_RoadCurvature_600m 0 " -0.16192 ~ -0.00001，负数代表向左的弯道曲率" 8191 " 0，代表曲率为0的直道" 512 " 0.00001 ~ 0.16192，正数代表向右的弯道曲率" 5631 " unknown" ;
VAL_ 964 HU_RoadCurvature_400m 0 " -0.16192 ~ -0.00001，负数代表向左的弯道曲率" 8191 " 0，代表曲率为0的直道" 512 " 0.00001 ~ 0.16192，正数代表向右的弯道曲率" 5375 " unknown" ;
VAL_ 964 HU_RoadCurvature_300m 0 " -0.16192 ~ -0.00001，负数代表向左的弯道曲率" 8191 " 0，代表曲率为0的直道" 512 " 0.00001 ~ 0.16192，正数代表向右的弯道曲率" 5119 " unknown" ;
VAL_ 964 HU_RoadCurvature_100m 0 " -0.16192 ~ -0.00001，负数代表向左的弯道曲率" 8191 " 0，代表曲率为0的直道" 512 " 0.00001 ~ 0.16192，正数代表向右的弯道曲率" 4863 " unknown" ;
VAL_ 964 HU_RoadCurvature_90m 0 " -0.16192 ~ -0.00001，负数代表向左的弯道曲率" 8191 " 0，代表曲率为0的直道" 512 " 0.00001 ~ 0.16192，正数代表向右的弯道曲率" 4607 " unknown" ;
VAL_ 964 HU_RoadCurvature_80m 0 " -0.16192 ~ -0.00001，负数代表向左的弯道曲率" 8191 " 0，代表曲率为0的直道" 512 " 0.00001 ~ 0.16192，正数代表向右的弯道曲率" 4351 " unknown" ;
VAL_ 964 HU_RoadCurvature_70m 0 " -0.16192 ~ -0.00001，负数代表向左的弯道曲率" 8191 " 0，代表曲率为0的直道" 512 " 0.00001 ~ 0.16192，正数代表向右的弯道曲率" 2559 " unknown" ;
VAL_ 964 HU_RoadCurvature_60m 0 " -0.16192 ~ -0.00001，负数代表向左的弯道曲率" 8191 " 0，代表曲率为0的直道" 512 " 0.00001 ~ 0.16192，正数代表向右的弯道曲率" 2303 " unknown" ;
VAL_ 964 HU_RoadCurvature_50m 0 " -0.16192 ~ -0.00001，负数代表向左的弯道曲率" 8191 " 0，代表曲率为0的直道" 512 " 0.00001 ~ 0.16192，正数代表向右的弯道曲率" 2047 " unknown" ;
VAL_ 964 HU_RoadCurvature_40m 0 " -0.16192 ~ -0.00001，负数代表向左的弯道曲率" 8191 " 0，代表曲率为0的直道" 512 " 0.00001 ~ 0.16192，正数代表向右的弯道曲率" 1791 " unknown" ;
VAL_ 964 HU_RoadCurvature_30m 0 " -0.16192 ~ -0.00001，负数代表向左的弯道曲率" 8191 " 0，代表曲率为0的直道" 512 " 0.00001 ~ 0.16192，正数代表向右的弯道曲率" 1535 " unknown" ;
VAL_ 964 HU_RoadCurvature_20m 0 " -0.16192 ~ -0.00001，负数代表向左的弯道曲率" 8191 " 0，代表曲率为0的直道" 512 " 0.00001 ~ 0.16192，正数代表向右的弯道曲率" 1279 " unknown" ;
VAL_ 964 HU_RoadCurvature_10m 0 " -0.16192 ~ -0.00001，负数代表向左的弯道曲率" 8191 " 0，代表曲率为0的直道" 512 " 0.00001 ~ 0.16192，正数代表向右的弯道曲率" 1023 " unknown" ;
VAL_ 964 HU_Road_TrafficFlow 0 "unknown" 1 "畅通" 2 "缓行" 3 " 拥堵，0x4=严重拥堵，0x5=无交通流,0x6=reserved.0x7=invalid" ;
VAL_ 964 HU_Lane_Changtype 0 "NO change，0x1=Merge" 2 "Separate，
0x3=invalid" ;
VAL_ 964 HU_To_NumchangeOfLanes_Dist 0 " 0~600m" 61 "Out of Range" 62 "reserved" 63 "unknown" ;
VAL_ 964 HU_TollDis 0 " 0~600m" 61 "Out of Range" 62 "reserved" 63 "unknown" ;
VAL_ 964 HU_TollInfo 0 "=路径无收费站" 1 "路径有收费站" 2 "预留" 3 "invalid" ;
VAL_ 964 HU_LaneCnt 0 "unknown,0x1-0x5=当前道路车道数量，0x6=大于等于6,,0x7=当前道路单项行驶且车辆逆行" ;
VAL_ 964 HU_ForwardRoadType 0 "
0x0=Road Type Unknown= Small road, Walking Street" 1 "Road Type Class 1= Secondary Roads" 2 "Road Type Class 2= Mainly Road in City" 3 "Road Type Class 3= Mainly Road in City, Normal Province Road, Mainly street" 4 "Road Type Class 4= Province Road, Mainly Road " 5 "Road Type Class 5= Highway, National Road, Speed road" 6 "Reserved

2.搭载ADAS=
0x0=未知" 1 "城市主要道路" 2 "城市快速路" 3 "省道，县道" 4 "国道" 5 "高速路" 6 "次要道路，普通道路，乡公路，县乡内部路" 7 "预留" ;
VAL_ 964 HU_RampSide 0 "Unknown" 1 "道路左边" 2 "道路右边" 3 "直线匝道" ;
VAL_ 964 HU_NavGuiganceStatus 0 "没有导航引导路径" 1 "有导航引导路径" 2 "Reserved" 3 "Reserved" ;
VAL_ 964 HU_TunnelLength 0 " 0~600m" 61 "Out of Range" 62 "reserved" 63 "unknown" ;
VAL_ 964 HU_RoadCurvatureFar 0 " -0.16192 ~ -0.00001，负数代表向左的弯道曲率" 8191 " 0，代表曲率为0的直道" 512 " 0.00001 ~ 0.16192，正数代表向右的弯道曲率" 1023 " unknown" ;
VAL_ 964 HU_TunnelDistance 0 " 0~600m" 61 "Out of Range" 62 "reserved" 63 "unknown" ;
VAL_ 964 HU_RoadCurvature 0 " -0.16192 ~ -0.00001，负数代表向左的弯道曲率" 8191 " 0，代表曲率为0的直道" 512 " 0.00001 ~ 0.16192，正数代表向右的弯道曲率" 1023 " unknown" ;
VAL_ 964 HU_EnterTunnelInfo 0 " unknown" 1 "隧道入口" 2 "隧道中" 3 "隧道出口" ;
VAL_ 1021 BCM_RearFoglampStatusFB 0 "inactive" 1 "off
0x2=on
0x3=Reserve" ;
VAL_ 1021 BCM_AutHeadLiSts 0 "inactive" 1 "off
0x2=位置灯
0x3=近光灯
0x4=自动大灯
0x5~0x7=Reserve" ;
VAL_ 1021 BCM_DrvModSwSts 0 "Initial" 1 "Back" 2 "Forward" 3 "Fault" ;
VAL_ 1021 BCM_FrontWindshieldWarmStatus 0 "inactive" 1 "on" 2 "off " 3 "reserved" ;
VAL_ 1021 BCM_SwitchDimmerlevel 0 "白天模式" 1 "Level1~Level21" 31 "invalid" ;
VAL_ 1021 BCM_EPSTorqSYNStatus 0 "inactive" 1 "ON" 2 "OFF" 3 "reserved" ;
VAL_ 1021 BCM_EPSTorqueMode 0 "normal " 1 "light " 2 "heavy " 3 "reserved" ;
VAL_ 1021 BCM_DriveMode 0 "Normal" 1 "Eco" 2 "Sport  " 3 "Snow" 4 "Sport+" 5 "Smart" 6 "Race" 7 "Reserved" 15 "Invalid" ;
VAL_ 1021 BCM_PowerManageLevel 0 "Valid" 1 "Level1" 2 " Level2" 3 " Level3" 4 " Level4" 5 "Reserve" 7 "Invalid" ;
VAL_ 1023 BCM_FloorLampStatus 0 "OFF" 1 "ON" 2 "Not used" 3 "Reserved" ;
VAL_ 1023 BCM_TurnIndicatorRightError 0 "无故障" 1 "有故障" ;
VAL_ 1023 BCM_TurnIndicatorLeftError 0 "无故障" 1 "有故障" ;
VAL_ 1023 BCM_PositionLampSwitchStatus 0 "Off" 1 "On" ;
VAL_ 1023 LCM_DRLSts 0 "Not Actived" 1 "Actived" ;
VAL_ 1023 BCM_FollowMeHomeLightSetStatus 0 "invalid" 1 "Off" 2 "10s" 3 "30s" 4 "60s" 5 "120s" 6 "Reserved" 7 "Reserved" ;
VAL_ 1023 BCM_RightDayLampError 0 "无故障" 1 "有故障" ;
VAL_ 1023 BCM_LeftDayLampError 0 "无故障" 1 "有故障" ;
VAL_ 1023 BCM_RightFrontFoglampError 0 "无故障" 1 "有故障" ;
VAL_ 1023 BCM_LeftFrontFoglampError 0 "无故障" 1 "有故障" ;
VAL_ 1023 BCM_RightLowBeamError 0 "无故障" 1 "有故障" ;
VAL_ 1023 BCM_LeftLowBeamError 0 "无故障" 1 "有故障" ;
VAL_ 1023 BCM_FrontPositionLampError 0 "无故障" 1 "有故障" ;
VAL_ 1023 BCM_HighBeamLampError 0 "No error" 1 " error" ;
VAL_ 1023 BCM_AutoHeadlightSts 0 "Not Actived" 1 "Actived" ;
VAL_ 1023 BCM_FrontFoglampStatus 0 "OFF" 1 "ON" 2 "Not used" 3 "Reserved" ;
VAL_ 1023 BCM_FollowMeTurnon 0 "OFF" 1 "ON" ;
VAL_ 1023 BCM_PositionLampStatus 0 "OFF" 1 "ON" 2 "Not used" 3 "Reserved" ;
VAL_ 1023 PEPS_WelcomeLightStaus 0 "inactive" 1 "On" 2 "Off" 3 "Reserved" ;
VAL_ 1023 BCM_Musiclightfeedback 0 "inactive" 1 "enter" 2 "exit" 3 "Reserved" ;
VAL_ 1023 BCM_MusicPlayRequestSignal 0 "inactive " 1 "start " 2 "end " 3 " illegal" ;
VAL_ 1023 BCM_MusicLightModeSelectSts 0 "Inactive" 1 "Light Mode1" 2 "Light Mode2" 3 "Light Mode3" 4 "Light Mode4" 5 "Light Mode5" 6 "Light Mode6" 7 "Light Mode7" ;
VAL_ 1310 TPMS_Commendatorypressure 0 "invalid" 1 "2.0bar" 2 "2.1bar" 3 "2.2bar" 4 "2.3bar" 5 "2.4" 6 "2.5bar" 7 "2.6bar" 8 "2.7bar" 9 "2.9bar" 10 "reseved" ;
VAL_ 1310 TPMS_AerateFlag 0 "invalid" 1 "active" ;
VAL_ 1310 TPMS_Suggestion 0 "No warning" 1 "slow down（谨慎驾驶）" 2 "check tire（检查轮胎）" 3 "renewal tire（更换轮胎）" 4 "low pressure（低压提示） " 5 "low pressure caused by temperature （气温变化引起的低压提示）" 6 "reseved" ;
VAL_ 1310 TPMS_LRLeakageWarning 0 "No any tire" 1 "Left Rear tire quik leakage" 2 "Left Rear tire quik leakage" 3 "Reserved" ;
VAL_ 1310 TPMS_RRLeakageWarning 0 "No any tire" 1 "Right Rear tire quik leakage" 2 "Right Rear tire slow leakage" ;
VAL_ 1310 TPMS_RFLeakageWarning 0 "No any tire" 1 "Right Front tire  quik leakage" 2 "Right Front tire  slow leakage" 3 "Reserved" ;
VAL_ 1310 TPMS_LFLeakageWarning 0 "No any tire" 1 "Left Front tire quik leakage" 2 "Left Front tire slow leakage" 3 "Reserved" ;
VAL_ 1310 TPMS_LFTemperatureWarning 0 "No temperature warning" 1 "Temperature warning" ;
VAL_ 1310 TPMS_RFTemperatureWarning 0 "No temperature warning" 1 "Temperature warning" ;
VAL_ 1310 TPMS_RRTemperatureWarning 0 "No temperature warning" 1 "Temperature warning" ;
VAL_ 1310 TPMS_LRTemperatureWarning 0 "No temperature warning" 1 "Temperature warning" ;
VAL_ 1310 TPMS_TirePosition 0 "No any sensor" 1 "Left Front tire.
0x2=Right Front tire" 3 "Right Rear tire.
0x4=Left Rear tire" 5 "reseved." ;
